VERSION ""

NS_ :

BS_:

BU_: DCM CCU C_ECU C_ECU_GW

BO_ 940 BIU3AC: 8 C_ECU_GW
 SG_ BIU3AC_7_0_HEADLAMP_SMALL : 56|1@1+ (1,0) [0|1] ""  CCU
 SG_ BIU3AC_7_1_HEADLAMP_LO_REQ : 57|1@1+ (1,0) [0|1] "" Vector__XXX
 SG_ BIU3AC_7_2_HEADLAMP_HI_REQ : 58|1@1+ (1,0) [0|1] ""  CCU
 SG_ BIU3AC_7_3_FT_FOG_RELAY_REQ : 59|1@1+ (1,0) [0|1] ""  CCU
 SG_ BIU3AC_7_4_FOGLAMP_RR : 60|1@1+ (1,0) [0|1] ""  CCU
 SG_ BIU3AC_7_5_DRL : 61|1@1+ (1,0) [0|1] "" Vector__XXX
 SG_ BIU3AC_7_6_WIPER_FRONT : 62|1@1+ (1,0) [0|1] ""  CCU
 SG_ BIU3AC_7_7_RDEF_RELAY_REQ : 63|1@1+ (1,0) [0|1] "" Vector__XXX
 SG_ BIU3AC_6_0_RDEFOGSW : 48|1@1+ (1,0) [0|1] "" Vector__XXX
 SG_ BIU3AC_6_1_CSTM_PRG : 49|1@1+ (1,0) [0|1] ""  CCU
 SG_ BIU3AC_6_2_FAIL_SHIFTLOCKSOL : 50|1@1+ (1,0) [0|1] "" Vector__XXX
 SG_ BIU3AC_6_3_REQ_CANCEL_ISS : 51|1@1+ (1,0) [0|1] "" Vector__XXX
 SG_ BIU3AC_6_4_REVERSE_MT : 52|1@1+ (1,0) [0|1] ""  CCU
 SG_ BIU3AC_6_5_HANDBRAKE : 53|1@1+ (1,0) [0|1] ""  CCU
 SG_ BIU3AC_6_6_BRAKELAMPSW : 54|1@1+ (1,0) [0|1] "" Vector__XXX
 SG_ BIU3AC_6_7_TOWING_SW : 55|1@1+ (1,0) [0|1] "" Vector__XXX
 SG_ BIU3AC_5_0_LANE_OFF_SW : 40|2@1+ (1,0) [0|3] "" Vector__XXX
 SG_ BIU3AC_5_2_PCR_OFF_SW : 42|2@1+ (1,0) [0|3] "" Vector__XXX
 SG_ BIU3AC_5_4_DIMMER_CANCEL : 44|1@1+ (1,0) [0|1] ""  CCU
 SG_ BIU3AC_5_5_KEYSW : 45|1@1+ (1,0) [0|1] "" Vector__XXX
 SG_ BIU3AC_5_6_IND_ND_SHIFTLOCK : 46|1@1+ (1,0) [0|1] "" Vector__XXX
 SG_ BIU3AC_4_0_DOOR_DRVR : 32|1@1+ (1,0) [0|1] ""  DCM,CCU
 SG_ BIU3AC_4_1_DOOR_PASS : 33|1@1+ (1,0) [0|1] ""  DCM,CCU
 SG_ BIU3AC_4_2_DOOR_RRRH : 34|1@1+ (1,0) [0|1] ""  DCM,CCU
 SG_ BIU3AC_4_3_DOOR_RRLH : 35|1@1+ (1,0) [0|1] ""  DCM,CCU
 SG_ BIU3AC_4_4_DOOR_RG : 36|1@1+ (1,0) [0|1] ""  DCM,CCU
 SG_ BIU3AC_4_5_DOOR_TR : 37|1@1+ (1,0) [0|1] ""  DCM,CCU
 SG_ BIU3AC_4_6_HOOD_CLOSE : 38|1@1+ (1,0) [0|1] ""  DCM,CCU
 SG_ BIU3AC_4_7_HOOD_OPEN : 39|1@1+ (1,0) [0|1] ""  CCU
 SG_ BIU3AC_3_0_GW_STSW_RES : 24|1@1+ (1,0) [0|1] "" Vector__XXX
 SG_ BIU3AC_3_1_GW_POWER_RES : 25|2@1+ (1,0) [0|2] "" Vector__XXX
 SG_ BIU3AC_3_3_ST1 : 27|1@1+ (1,0) [0|1] "" Vector__XXX
 SG_ BIU3AC_3_4_ST2 : 28|1@1+ (1,0) [0|1] "" Vector__XXX
 SG_ BIU3AC_3_5_ACC : 29|1@1+ (1,0) [0|1] ""  CCU
 SG_ BIU3AC_3_6_IGA : 30|1@1+ (1,0) [0|1] ""  CCU
 SG_ BIU3AC_3_7_BAT_BACKUP : 31|1@1+ (1,0) [0|1] "" Vector__XXX
 SG_ BIU3AC_2_0_CSTM_AC : 16|1@1+ (1,0) [0|1] "" Vector__XXX
 SG_ BIU3AC_2_1_IMB_SMT : 17|2@1+ (1,0) [0|3] ""  DCM,CCU
 SG_ BIU3AC_2_3_CSTM_WGN_SDN : 19|1@1+ (1,0) [0|1] ""  DCM
 SG_ BIU3AC_2_4_VAL_SEAT_BACK_CTSM : 20|1@1+ (1,0) [0|1] "" Vector__XXX
 SG_ BIU3AC_2_5_VAL_MIR_AFOLD_CTSM : 21|1@1+ (1,0) [0|1] "" Vector__XXX
 SG_ BIU3AC_2_6_VAL_MIR_RTILT_CTSM : 22|1@1+ (1,0) [0|1] "" Vector__XXX
 SG_ BIU3AC_2_7_WIPER_REAR : 23|1@1+ (1,0) [0|1] ""  CCU
 SG_ BIU3AC_1_0_MSG_COUNTER : 8|4@1+ (1,0) [0|15] ""  DCM,CCU
 SG_ BIU3AC_1_4_PADDLESHIFT_DOWN_SW : 12|1@1+ (1,0) [0|1] "" Vector__XXX
 SG_ BIU3AC_1_5_PADDLESHIFT_UP_SW : 13|1@1+ (1,0) [0|1] "" Vector__XXX
 SG_ BIU3AC_1_6_MANUALMODE_SW : 14|1@1+ (1,0) [0|1] "" Vector__XXX
 SG_ BIU3AC_0_0_CHECK_SUM : 0|8@1+ (1,0) [0|255] ""  DCM,CCU

BO_ 1616 BIU650: 8 C_ECU_GW
 SG_ BIU650_7_0_Reserved : 56|1@1+ (1,0) [0|1] ""  CCU
 SG_ BIU650_7_1_Reserved : 57|1@1+ (1,0) [0|1] ""  CCU
 SG_ BIU650_7_2_Reserved : 58|1@1+ (1,0) [0|1] ""  CCU
 SG_ BIU650_7_3_DOOR_LINK_SW_STS : 59|1@1+ (1,0) [0|1] ""  CCU
 SG_ BIU650_7_4_Reserved : 60|1@1+ (1,0) [0|1] ""  CCU
 SG_ BIU650_6_0_Reserved : 48|3@1+ (1,0) [0|7] ""  CCU
 SG_ BIU650_6_3_RR_WIPER_STATUS : 51|2@1+ (1,0) [0|3] ""  CCU
 SG_ BIU650_6_5_WIPER_SENSITIVITY_CTM : 53|2@1+ (1,0) [0|3] ""  CCU
 SG_ BIU650_5_0_Reserved : 40|1@1+ (1,0) [0|1] "" Vector__XXX
 SG_ BIU650_5_1_Reserved : 41|1@1+ (1,0) [0|1] "" Vector__XXX
 SG_ BIU650_5_2_FMH_DOOR_LOCK : 42|2@1+ (1,0) [0|3] "" Vector__XXX
 SG_ BIU650_5_4_LMH_DOOR_LOCK : 44|2@1+ (1,0) [0|3] "" Vector__XXX
 SG_ BIU650_4_0_REQ_OPE_AUTOLIGHT : 32|2@1+ (1,0) [0|3] "" Vector__XXX
 SG_ BIU650_4_2_STATE_SHINSSR : 34|2@1+ (1,0) [0|3] "" Vector__XXX
 SG_ BIU650_4_4_STATE_RLS_FAIL : 36|2@1+ (1,0) [0|3] "" Vector__XXX
 SG_ BIU650_3_0_REQ_FWASHER_ITLOCK : 24|1@1+ (1,0) [0|1] "" Vector__XXX
 SG_ BIU650_3_1_FWIPER_RTN : 25|1@1+ (1,0) [0|1] "" Vector__XXX
 SG_ BIU650_3_2_TURN_LAMP_STATE_LEFT : 26|1@1+ (1,0) [0|1] "" Vector__XXX
 SG_ BIU650_3_3_TURN_LAMP_STATE_RIGHT : 27|1@1+ (1,0) [0|1] "" Vector__XXX
 SG_ BIU650_3_4_Reserved : 28|1@1+ (1,0) [0|1] "" Vector__XXX
 SG_ BIU650_2_0_HEADLAMP_SMALL_SW : 16|1@1+ (1,0) [0|1] "" Vector__XXX
 SG_ BIU650_2_1_HEADLAMP_LO_SW : 17|1@1+ (1,0) [0|1] "" Vector__XXX
 SG_ BIU650_2_2_HEADLAMP_OFF_SW : 18|1@1+ (1,0) [0|1] "" Vector__XXX
 SG_ BIU650_2_3_HEADLAMP_Hi_SW : 19|1@1+ (1,0) [0|1] "" Vector__XXX
 SG_ BIU650_2_4_HEAD_LAMP_PASS_SW : 20|1@1+ (1,0) [0|1] "" Vector__XXX
 SG_ BIU650_2_5_FFOG_SW : 21|1@1+ (1,0) [0|1] "" Vector__XXX
 SG_ BIU650_2_6_RFOG_SW : 22|1@1+ (1,0) [0|1] "" Vector__XXX
 SG_ BIU650_1_0_MSG_COUNTER : 8|4@1+ (1,0) [0|15] "" Vector__XXX
 SG_ BIU650_0_0_CHECK_SUM : 0|8@1+ (1,0) [0|255] "" Vector__XXX

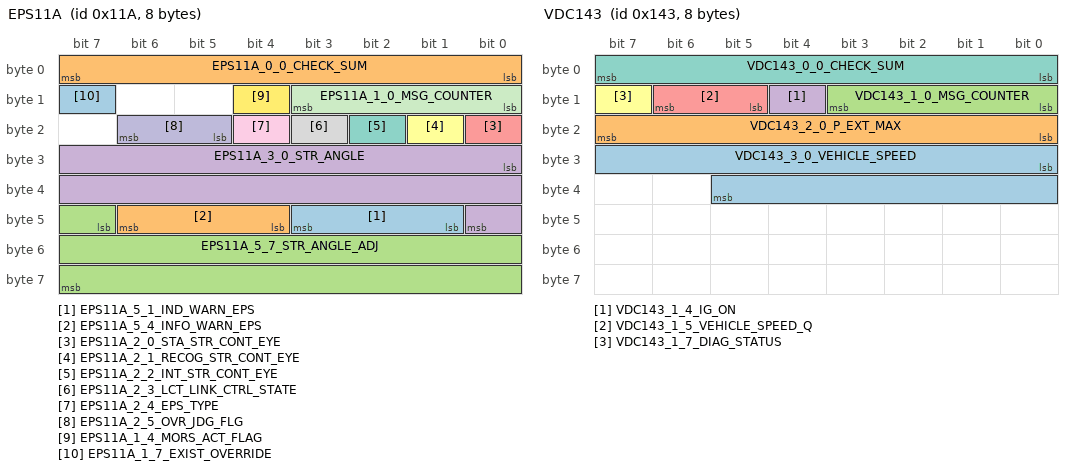
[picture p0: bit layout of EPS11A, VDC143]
BO_ 282 EPS11A: 8 C_ECU_GW
 SG_ EPS11A_5_1_IND_WARN_EPS : 41|3@1+ (1,0) [0|6] ""  DCM
 SG_ EPS11A_5_4_INFO_WARN_EPS : 44|3@1+ (1,0) [0|7] "" Vector__XXX
 SG_ EPS11A_5_7_STR_ANGLE_ADJ : 47|17@1- (0.01,0) [-655|655] "deg"  CCU
 SG_ EPS11A_3_0_STR_ANGLE : 24|17@1- (0.01,0) [-655|655] "deg" Vector__XXX
 SG_ EPS11A_2_0_STA_STR_CONT_EYE : 16|1@1+ (1,0) [0|1] "" Vector__XXX
 SG_ EPS11A_2_1_RECOG_STR_CONT_EYE : 17|1@1+ (1,0) [0|1] "" Vector__XXX
 SG_ EPS11A_2_2_INT_STR_CONT_EYE : 18|1@1+ (1,0) [0|1] "" Vector__XXX
 SG_ EPS11A_2_3_LCT_LINK_CTRL_STATE : 19|1@1+ (1,0) [0|1] "" Vector__XXX
 SG_ EPS11A_2_4_EPS_TYPE : 20|1@1+ (1,0) [0|1] "" Vector__XXX
 SG_ EPS11A_2_5_OVR_JDG_FLG : 21|2@1+ (1,0) [0|3] "" Vector__XXX
 SG_ EPS11A_1_0_MSG_COUNTER : 8|4@1+ (1,0) [0|15] ""  DCM
 SG_ EPS11A_1_4_MORS_ACT_FLAG : 12|1@1+ (1,0) [0|1] "" Vector__XXX
 SG_ EPS11A_1_7_EXIST_OVERRIDE : 15|1@1+ (1,0) [0|1] "" Vector__XXX
 SG_ EPS11A_0_0_CHECK_SUM : 0|8@1+ (1,0) [0|255] ""  DCM

BO_ 811 EPB32B: 8 C_ECU_GW
 SG_ EPB32B_7_0_AVH_TARGET_PRESS : 56|8@1+ (0.0235,0) [0|255] "MPa" Vector__XXX
 SG_ EPB32B_6_0_VEHICLE_RUN_STOP_FLG : 48|2@1+ (1,0) [0|3] "" Vector__XXX
 SG_ EPB32B_6_2_REQ_HILL_P_CAUTION : 50|1@1+ (1,0) [0|1] "" Vector__XXX
 SG_ EPB32B_5_0_FLG_AVH_OILPRES_EPB : 40|1@1+ (1,0) [0|1] "" Vector__XXX
 SG_ EPB32B_5_1_FLG_AVH : 41|1@1+ (1,0) [0|1] "" Vector__XXX
 SG_ EPB32B_5_2_AVH_INTENSIFY_PRES : 42|1@1+ (1,0) [0|1] "" Vector__XXX
 SG_ EPB32B_5_3_BREAK_IND : 43|2@1+ (1,0) [0|3] "" Vector__XXX
 SG_ EPB32B_5_5_AVH_ON_LAMP : 45|1@1+ (1,0) [0|1] ""  CCU
 SG_ EPB32B_5_6_AVH_FUNC_ON_LUMP : 46|1@1+ (1,0) [0|1] ""  CCU
 SG_ EPB32B_5_7_AVH_ACTIVE : 47|1@1+ (1,0) [0|1] ""  CCU
 SG_ EPB32B_4_0_BUZZER : 32|2@1+ (1,0) [0|3] "" Vector__XXX
 SG_ EPB32B_4_2_HILL_HOLD_ON_LAMP : 34|1@1+ (1,0) [0|1] "" Vector__XXX
 SG_ EPB32B_4_3_CLAMP_LAMP : 35|2@1+ (1,0) [0|3] ""  CCU
 SG_ EPB32B_4_5_WARN_LAMP : 37|2@1+ (1,0) [0|3] "" Vector__XXX
 SG_ EPB32B_4_7_WARN_EPB_MET_LCD : 39|1@1+ (1,0) [0|1] "" Vector__XXX
 SG_ EPB32B_3_0_STATUS_EPB : 24|3@1+ (1,0) [0|7] ""  CCU
 SG_ EPB32B_3_3_DYNAMIC_PARKING : 27|1@1+ (1,0) [0|1] "" Vector__XXX
 SG_ EPB32B_3_4_HILL_HOLD_RUN_FLG : 28|1@1+ (1,0) [0|1] "" Vector__XXX
 SG_ EPB32B_3_5_INHIBIT_ISS_DELAY : 29|1@1+ (1,0) [0|1] "" Vector__XXX
 SG_ EPB32B_3_6_INHIBIT_ISS : 30|1@1+ (1,0) [0|1] "" Vector__XXX
 SG_ EPB32B_3_7_AVH_PERMIT_CONT_ACC : 31|1@1+ (1,0) [0|1] "" Vector__XXX
 SG_ EPB32B_2_0_ERR_INFO : 16|2@1+ (1,0) [0|3] "" Vector__XXX
 SG_ EPB32B_2_2_EPB_FAIL_FLG1 : 18|1@1+ (1,0) [0|1] "" Vector__XXX
 SG_ EPB32B_2_3_EPB_FAIL_FLG2 : 19|1@1+ (1,0) [0|1] "" Vector__XXX
 SG_ EPB32B_2_4_EPB_FAIL_FLG3 : 20|1@1+ (1,0) [0|1] "" Vector__XXX
 SG_ EPB32B_1_0_MSG_COUNTER : 8|4@1+ (1,0) [0|15] ""  CCU
 SG_ EPB32B_1_4_WAKE_UP_FRAME : 12|1@1+ (1,0) [0|1] "" Vector__XXX
 SG_ EPB32B_1_5_REQ_COMM_CONT : 13|1@1+ (1,0) [0|1] "" Vector__XXX
 SG_ EPB32B_1_6 : 14|1@1+ (1,0) [0|1] "" Vector__XXX
 SG_ EPB32B_0_0_CHECK_SUM : 0|8@1+ (1,0) [0|255] ""  CCU

BO_ 323 VDC143: 8 C_ECU_GW
 SG_ VDC143_3_0_VEHICLE_SPEED : 24|14@1+ (0.05625,0) [0|299.98125] "km/h"  CCU
 SG_ VDC143_2_0_P_EXT_MAX : 16|8@1+ (1,0) [0|250] "bar" Vector__XXX
 SG_ VDC143_1_0_MSG_COUNTER : 8|4@1+ (1,0) [0|15] "" Vector__XXX
 SG_ VDC143_1_4_IG_ON : 12|1@1+ (1,0) [0|1] "" Vector__XXX
 SG_ VDC143_1_5_VEHICLE_SPEED_Q : 13|2@1+ (1,0) [0|3] "" Vector__XXX
 SG_ VDC143_1_7_DIAG_STATUS : 15|1@1+ (1,0) [0|1] "" Vector__XXX
 SG_ VDC143_0_0_CHECK_SUM : 0|8@1+ (1,0) [0|255] "" Vector__XXX

BO_ 808 VDC328: 8 C_ECU_GW
 SG_ VDC328_7_1_IND_WARN_CBC : 57|1@1+ (1,0) [0|1] "" Vector__XXX
 SG_ VDC328_7_2_ACTIVATE_CBC : 58|1@1+ (1,0) [0|1] "" Vector__XXX
 SG_ VDC328_7_3_FLAG_ACT_CBC : 59|1@1+ (1,0) [0|1] "" Vector__XXX
 SG_ VDC328_6_0_PROHIBIT_VDC_OFF_CCU : 48|1@1+ (1,0) [0|1] ""  CCU
 SG_ VDC328_6_1_PROHIBIT_AVH_CCU : 49|1@1+ (1,0) [0|1] "" Vector__XXX
 SG_ VDC328_5_0_VDC_BUZZER : 40|2@1+ (1,0) [0|3] "" Vector__XXX
 SG_ VDC328_5_2_WARN_BRAKE_BOOST : 42|1@1+ (1,0) [0|1] "" Vector__XXX
 SG_ VDC328_5_4_WARN_RBS : 44|2@1+ (1,0) [0|3] "" Vector__XXX
 SG_ VDC328_5_6_IND_HSA_ON : 46|1@1+ (1,0) [0|1] "" Vector__XXX
 SG_ VDC328_5_7_IND_TCS_OFF : 47|1@1+ (1,0) [0|1] "" Vector__XXX
 SG_ VDC328_4_0_IND_VDC_OFF : 32|1@1+ (1,0) [0|1] ""  CCU
 SG_ VDC328_4_1_STATE_ACTIVATE_VDC : 33|1@1+ (1,0) [0|1] ""  CCU
 SG_ VDC328_4_2_IND_HSA_OFF : 34|1@1+ (1,0) [0|1] ""  DCM
 SG_ VDC328_4_3_IND_HDC : 35|2@1+ (1,0) [0|3] ""  CCU
 SG_ VDC328_4_5_WARNING_BRAKE_SYS : 37|2@1+ (1,0) [0|3] "" Vector__XXX
 SG_ VDC328_4_7_ACTIVE_OHB : 39|1@1+ (1,0) [0|1] "" Vector__XXX
 SG_ VDC328_3_0_IND_WARN_EBD : 24|1@1+ (1,0) [0|1] ""  DCM
 SG_ VDC328_3_1_IND_WARN_ABS : 25|1@1+ (1,0) [0|1] ""  DCM
 SG_ VDC328_3_2_IND_WARN_VDC : 26|1@1+ (1,0) [0|1] ""  DCM,CCU
 SG_ VDC328_3_3_IND_WARN_HSA : 27|1@1+ (1,0) [0|1] ""  DCM
 SG_ VDC328_3_4_WARN_BRAKEFLUID_LV : 28|2@1+ (1,0) [0|3] "" Vector__XXX
 SG_ VDC328_3_6_IND_TCS_OFF : 30|1@1+ (1,0) [0|1] "" Vector__XXX
 SG_ VDC328_3_7_EXIST_EPB : 31|1@1+ (1,0) [0|1] ""  CCU
 SG_ VDC328_2_0_WARN_EBD_MET_LCD : 16|1@1+ (1,0) [0|1] "" Vector__XXX
 SG_ VDC328_2_1_WARN_ABS_MET_LCD : 17|1@1+ (1,0) [0|1] "" Vector__XXX
 SG_ VDC328_2_2_WARN_VDC_MET_LCD : 18|1@1+ (1,0) [0|1] "" Vector__XXX
 SG_ VDC328_2_3_WARN_HSA_MET_LCD : 19|1@1+ (1,0) [0|1] "" Vector__XXX
 SG_ VDC328_2_4_EXIST_VECTARING : 20|1@1+ (1,0) [0|1] "" Vector__XXX
 SG_ VDC328_1_0_MSG_COUNTER : 8|4@1+ (1,0) [0|15] ""  DCM,CCU
 SG_ VDC328_0_0_CHECK_SUM : 0|8@1+ (1,0) [0|255] ""  DCM,CCU

BO_ 316 VDC13C: 8 C_ECU_GW
 SG_ VDC13C_7_0_RCV_FAIL_ADA : 56|1@1+ (1,0) [0|1] "" Vector__XXX
 SG_ VDC13C_7_1_FAIL_PCU : 57|1@1+ (1,0) [0|1] "" Vector__XXX
 SG_ VDC13C_7_2_CONT_STATE_ES_BRAKE : 58|1@1+ (1,0) [0|1] "" Vector__XXX
 SG_ VDC13C_7_3_ASST_PRECRUSH_ACC : 59|1@1+ (1,0) [0|1] "" Vector__XXX
 SG_ VDC13C_7_4_CONT_STATE_PRECRUSH : 60|1@1+ (1,0) [0|1] "" Vector__XXX
 SG_ VDC13C_7_5_PERMIT_BRAKE_ACC : 61|1@1+ (1,0) [0|1] "" Vector__XXX
 SG_ VDC13C_7_6_DETECT_BRAKING : 62|1@1+ (1,0) [0|1] "" Vector__XXX
 SG_ VDC13C_7_7_EMERGENCY_BRAKE : 63|1@1+ (1,0) [0|1] "" Vector__XXX
 SG_ VDC13C_6_0_SPD_PULSE_INTEGRAL : 48|6@1+ (1,0) [0|63] ""  CCU
 SG_ VDC13C_6_6_VDC_OFF : 54|1@1+ (1,0) [0|1] ""  CCU
 SG_ VDC13C_6_7_STBY_PREVIEW_VDC : 55|1@1+ (1,0) [0|1] "" Vector__XXX
 SG_ VDC13C_5_0_SPD_PULSE_RRRH : 40|7@1+ (1,0) [0|95] "" Vector__XXX
 SG_ VDC13C_5_7_ACTIVATE_TSM : 47|1@1+ (1,0) [0|1] "" Vector__XXX
 SG_ VDC13C_4_0_SPD_PULSE_RRLH : 32|7@1+ (1,0) [0|95] "" Vector__XXX
 SG_ VDC13C_4_7_ACTIVATE_RMI : 39|1@1+ (1,0) [0|1] "" Vector__XXX
 SG_ VDC13C_3_0_SPD_PULSE_FTRH : 24|7@1+ (1,0) [0|95] "" Vector__XXX
 SG_ VDC13C_3_7_ACTIVATE_VECTARING : 31|1@1+ (1,0) [0|1] ""  CCU
 SG_ VDC13C_2_0_SPD_PULSE_FTLH : 16|7@1+ (1,0) [0|95] "" Vector__XXX
 SG_ VDC13C_2_7_STATE_ACTIVATE_HSA : 23|1@1+ (1,0) [0|1] "" Vector__XXX
 SG_ VDC13C_1_0_MSG_COUNTER : 8|4@1+ (1,0) [0|15] ""  CCU
 SG_ VDC13C_1_4_ACTIVE_BRAKEHOLD : 12|1@1+ (1,0) [0|1] "" Vector__XXX
 SG_ VDC13C_1_5_PROHIBIT_BRAKEHOLD : 13|1@1+ (1,0) [0|1] "" Vector__XXX
 SG_ VDC13C_1_6_BRAKELAMP_RELAY : 14|1@1+ (1,0) [0|1] "" Vector__XXX
 SG_ VDC13C_1_7_STATUS_BRAKELAMP : 15|1@1+ (1,0) [0|1] "" Vector__XXX
 SG_ VDC13C_0_0_CHECK_SUM : 0|8@1+ (1,0) [0|255] ""  CCU

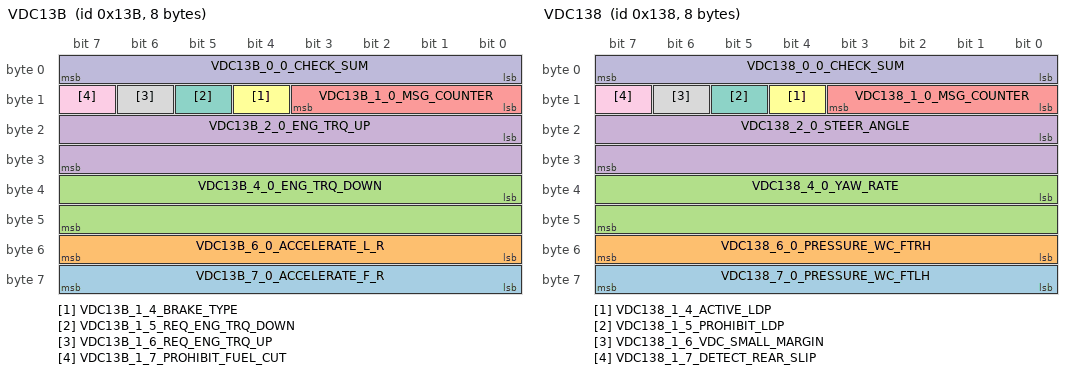
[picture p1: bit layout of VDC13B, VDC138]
BO_ 315 VDC13B: 8 C_ECU_GW
 SG_ VDC13B_7_0_ACCELERATE_F_R : 56|8@1- (0.1,0) [-12.5|12.5] "m/s^2"  CCU
 SG_ VDC13B_6_0_ACCELERATE_L_R : 48|8@1- (0.1923,0) [-17.64|17.64] "m/s^2"  CCU
 SG_ VDC13B_4_0_ENG_TRQ_DOWN : 32|16@1+ (0.1,-1000) [-1000|5553.5] "Nm" Vector__XXX
 SG_ VDC13B_2_0_ENG_TRQ_UP : 16|16@1+ (0.1,-1000) [-1000|5553.5] "Nm" Vector__XXX
 SG_ VDC13B_1_0_MSG_COUNTER : 8|4@1+ (1,0) [0|15] ""  CCU
 SG_ VDC13B_1_4_BRAKE_TYPE : 12|1@1+ (1,0) [0|1] "" Vector__XXX
 SG_ VDC13B_1_5_REQ_ENG_TRQ_DOWN : 13|1@1+ (1,0) [0|1] "" Vector__XXX
 SG_ VDC13B_1_6_REQ_ENG_TRQ_UP : 14|1@1+ (1,0) [0|1] "" Vector__XXX
 SG_ VDC13B_1_7_PROHIBIT_FUEL_CUT : 15|1@1+ (1,0) [0|1] "" Vector__XXX
 SG_ VDC13B_0_0_CHECK_SUM : 0|8@1+ (1,0) [0|255] ""  CCU

BO_ 313 VDC139: 8 C_ECU_GW
 SG_ VDC139_7_4_FAIL_PRESSURE_SSR : 60|1@1+ (1,0) [0|1] "" Vector__XXX
 SG_ VDC139_7_5_STATUS_EPB : 61|3@1+ (1,0) [0|7] "" Vector__XXX
 SG_ VDC139_6_0_SSR_N_PRESS : 48|12@1+ (1,0) [193|3896] "" Vector__XXX
 SG_ VDC139_5_0_PRESSURE_BRAKE : 40|8@1+ (0.13058823529412,0) [0|25] "MPa" Vector__XXX
 SG_ VDC139_4_0_HDC_STATUS : 32|2@1+ (1,0) [0|3] "" Vector__XXX
 SG_ VDC139_4_2_BRAKELAMPSW : 34|1@1+ (1,0) [0|1] ""  CCU
 SG_ VDC139_4_3_FAIL_BRAKELAMPSW : 35|1@1+ (1,0) [0|1] "" Vector__XXX
 SG_ VDC139_4_4_ACTIVATE_ABS : 36|1@1+ (1,0) [0|1] ""  CCU
 SG_ VDC139_4_5_ACTIVATE_TCS : 37|1@1+ (1,0) [0|1] ""  CCU
 SG_ VDC139_4_6_CONT_OVER_STR : 38|1@1+ (1,0) [0|1] ""  CCU
 SG_ VDC139_4_7_CONT_UNDER_STR : 39|1@1+ (1,0) [0|1] ""  CCU
 SG_ VDC139_3_5_FAIL_VDC_SSR : 29|1@1+ (1,0) [0|1] ""  CCU
 SG_ VDC139_3_6_FAIL_SPD_SSR_FHI : 30|1@1+ (1,0) [0|1] "" Vector__XXX
 SG_ VDC139_3_7_FAIL_ABS_SYS : 31|1@1+ (1,0) [0|1] "" Vector__XXX
 SG_ VDC139_2_0_SPD_WHEEL_AVE : 16|13@1+ (0.05625,0) [0|299.98125] "km/h"  DCM,CCU
 SG_ VDC139_1_0_MSG_COUNTER : 8|4@1+ (1,0) [0|15] ""  DCM,CCU
 SG_ VDC139_1_4_FAIL_HDC_SYS : 12|1@1+ (1,0) [0|1] "" Vector__XXX
 SG_ VDC139_1_5_VEHICLE_HIGHT : 13|2@1+ (1,0) [0|2] ""  CCU
 SG_ VDC139_1_7_REPROGRAMING : 15|1@1+ (1,0) [0|1] ""  CCU
 SG_ VDC139_0_0_CHECK_SUM : 0|8@1+ (1,0) [0|255] ""  DCM,CCU

BO_ 312 VDC138: 8 C_ECU_GW
 SG_ VDC138_7_0_PRESSURE_WC_FTLH : 56|8@1+ (0.08,0) [0|20.4] "MPa" Vector__XXX
 SG_ VDC138_6_0_PRESSURE_WC_FTRH : 48|8@1+ (0.08,0) [0|20.4] "MPa" Vector__XXX
 SG_ VDC138_4_0_YAW_RATE : 32|16@1- (0.0047358121330724,0) [-1.571|1.571] "rad/s"  CCU
 SG_ VDC138_2_0_STEER_ANGLE : 16|16@1- (0.1,0) [-719.9|719.9] "deg"  CCU
 SG_ VDC138_1_0_MSG_COUNTER : 8|4@1+ (1,0) [0|15] ""  CCU
 SG_ VDC138_1_4_ACTIVE_LDP : 12|1@1+ (1,0) [0|1] "" Vector__XXX
 SG_ VDC138_1_5_PROHIBIT_LDP : 13|1@1+ (1,0) [0|1] "" Vector__XXX
 SG_ VDC138_1_6_VDC_SMALL_MARGIN : 14|1@1+ (1,0) [0|1] "" Vector__XXX
 SG_ VDC138_1_7_DETECT_REAR_SLIP : 15|1@1+ (1,0) [0|1] "" Vector__XXX
 SG_ VDC138_0_0_CHECK_SUM : 0|8@1+ (1,0) [0|255] ""  CCU

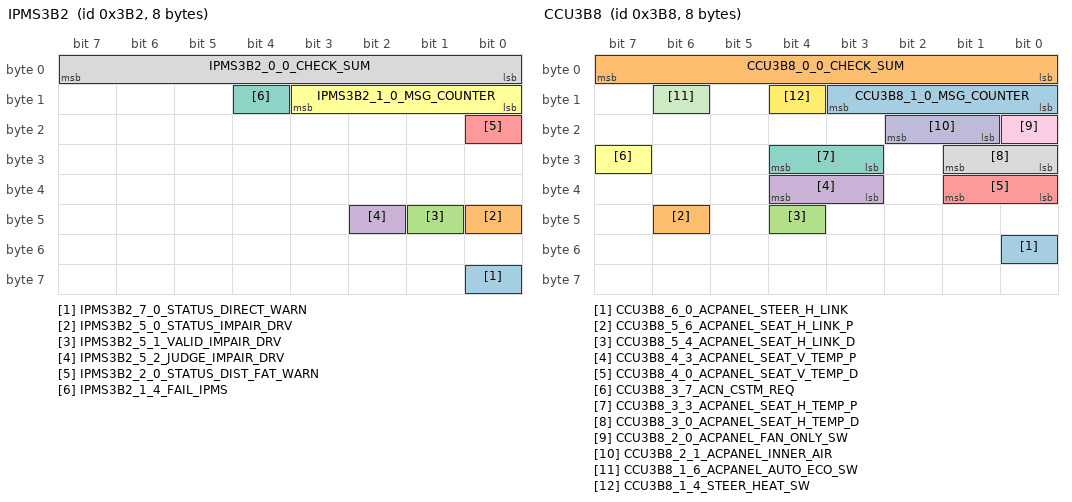
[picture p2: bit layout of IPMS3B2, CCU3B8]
BO_ 946 IPMS3B2: 8 C_ECU_GW
 SG_ IPMS3B2_7_0_STATUS_DIRECT_WARN : 56|1@1+ (1,0) [0|0] ""  CCU
 SG_ IPMS3B2_5_0_STATUS_IMPAIR_DRV : 40|1@1+ (1,0) [0|1] ""  CCU
 SG_ IPMS3B2_5_1_VALID_IMPAIR_DRV : 41|1@1+ (1,0) [0|1] ""  CCU
 SG_ IPMS3B2_5_2_JUDGE_IMPAIR_DRV : 42|1@1+ (1,0) [0|1] ""  CCU
 SG_ IPMS3B2_2_0_STATUS_DIST_FAT_WARN : 16|1@1+ (1,0) [0|1] ""  CCU
 SG_ IPMS3B2_1_0_MSG_COUNTER : 8|4@1+ (1,0) [0|15] ""  CCU
 SG_ IPMS3B2_1_4_FAIL_IPMS : 12|1@1+ (1,0) [0|1] "" Vector__XXX
 SG_ IPMS3B2_0_0_CHECK_SUM : 0|8@1+ (1,0) [0|255] ""  CCU

BO_ 952 CCU3B8: 8 CCU
 SG_ CCU3B8_6_0_ACPANEL_STEER_H_LINK : 48|1@1+ (1,0) [0|3] ""  C_ECU_GW
 SG_ CCU3B8_5_6_ACPANEL_SEAT_H_LINK_P : 46|1@1+ (1,0) [0|3] ""  C_ECU_GW
 SG_ CCU3B8_5_4_ACPANEL_SEAT_H_LINK_D : 44|1@1+ (1,0) [0|3] ""  C_ECU_GW
 SG_ CCU3B8_4_3_ACPANEL_SEAT_V_TEMP_P : 35|2@1+ (1,0) [0|3] ""  C_ECU_GW
 SG_ CCU3B8_4_0_ACPANEL_SEAT_V_TEMP_D : 32|2@1+ (1,0) [0|3] ""  C_ECU_GW
 SG_ CCU3B8_3_7_ACN_CSTM_REQ : 31|1@1+ (1,0) [0|1] ""  C_ECU_GW
 SG_ CCU3B8_3_3_ACPANEL_SEAT_H_TEMP_P : 27|2@1+ (1,0) [0|3] ""  C_ECU_GW
 SG_ CCU3B8_3_0_ACPANEL_SEAT_H_TEMP_D : 24|2@1+ (1,0) [0|3] ""  C_ECU_GW
 SG_ CCU3B8_2_0_ACPANEL_FAN_ONLY_SW : 16|1@1+ (1,0) [0|3] ""  C_ECU_GW
 SG_ CCU3B8_2_1_ACPANEL_INNER_AIR : 17|2@1+ (1,0) [0|3] ""  C_ECU_GW
 SG_ CCU3B8_1_6_ACPANEL_AUTO_ECO_SW : 14|1@1+ (1,0) [0|3] ""  C_ECU,C_ECU_GW
 SG_ CCU3B8_1_4_STEER_HEAT_SW : 12|1@1+ (1,0) [0|3] ""  C_ECU_GW
 SG_ CCU3B8_1_0_MSG_COUNTER : 8|4@1+ (1,0) [0|15] ""  C_ECU_GW
 SG_ CCU3B8_0_0_CHECK_SUM : 0|8@1+ (1,0) [0|255] ""  C_ECU_GW

BO_ 1712 CCU6B0: 8 CCU
 SG_ CCU6B0_7_0_AIL_CSTM_PRS_REQ : 56|1@1+ (1,0) [0|1] ""  C_ECU_GW
 SG_ CCU6B0_7_1_AIL_RENDER_REQ : 57|3@1+ (1,0) [0|5] ""  C_ECU_GW
 SG_ CCU6B0_6_0_AIL_FIRST_BRIGHT_REQ : 48|4@1+ (1,0) [0|9] ""  C_ECU_GW
 SG_ CCU6B0_6_4_AIL_SECOND_BRIGHT_REQ : 52|4@1+ (1,0) [0|15] ""  C_ECU_GW
 SG_ CCU6B0_5_0_AIL_SECOND_COLOR_REQ : 40|6@1+ (1,0) [0|63] ""  C_ECU_GW
 SG_ CCU6B0_4_0_AIL_FIRST_COLOR_REQ : 32|6@1+ (1,0) [0|63] ""  C_ECU_GW
 SG_ CCU6B0_3_0_AIL_ADAS_VEH_DIS_REQ : 24|1@1+ (1,0) [0|1] ""  C_ECU_GW
 SG_ CCU6B0_3_1_AIL_ADAS_LANE_DEV_REQ : 25|1@1+ (1,0) [0|1] ""  C_ECU_GW
 SG_ CCU6B0_3_2_AIL_ADAS_FT_CROSS_REQ : 26|1@1+ (1,0) [0|1] ""  C_ECU_GW
 SG_ CCU6B0_3_3_AIL_ADAS_HANDS_FR_REQ : 27|1@1+ (1,0) [0|1] ""  C_ECU_GW
 SG_ CCU6B0_2_0_AIL_WEL_FOL_REQ : 16|1@1+ (1,0) [0|1] ""  C_ECU_GW
 SG_ CCU6B0_2_1_AIL_ADAS_EXP_REQ : 17|1@1+ (1,0) [0|1] ""  C_ECU_GW
 SG_ CCU6B0_2_2_AIL_NOTIFI_EXP_REQ : 18|1@1+ (1,0) [0|1] ""  C_ECU_GW
 SG_ CCU6B0_2_3_AIL_AIR_CON_EXP_REQ : 19|1@1+ (1,0) [0|1] ""  C_ECU_GW
 SG_ CCU6B0_1_0_MSG_COUNTER : 8|4@1+ (1,0) [0|15] ""  C_ECU_GW
 SG_ CCU6B0_1_4_AIL_CUSTOM_REQ : 12|1@1+ (1,0) [0|1] ""  C_ECU_GW
 SG_ CCU6B0_1_5_AIL_CUSTOM_RESET_REQ : 13|1@1+ (1,0) [0|1] ""  C_ECU_GW
 SG_ CCU6B0_1_6_AIL_ON_OFF_REQ : 14|1@1+ (1,0) [0|1] ""  C_ECU_GW
 SG_ CCU6B0_0_0_CHECK_SUM : 0|8@1+ (1,0) [0|255] ""  C_ECU_GW

BO_ 1711 CCU6AF: 8 CCU
 SG_ CCU6AF_1_0_MSG_COUNTER : 8|4@1+ (1,0) [0|15] ""  C_ECU_GW
 SG_ CCU6AF_0_0_CHECK_SUM : 0|8@1+ (1,0) [0|255] ""  C_ECU_GW

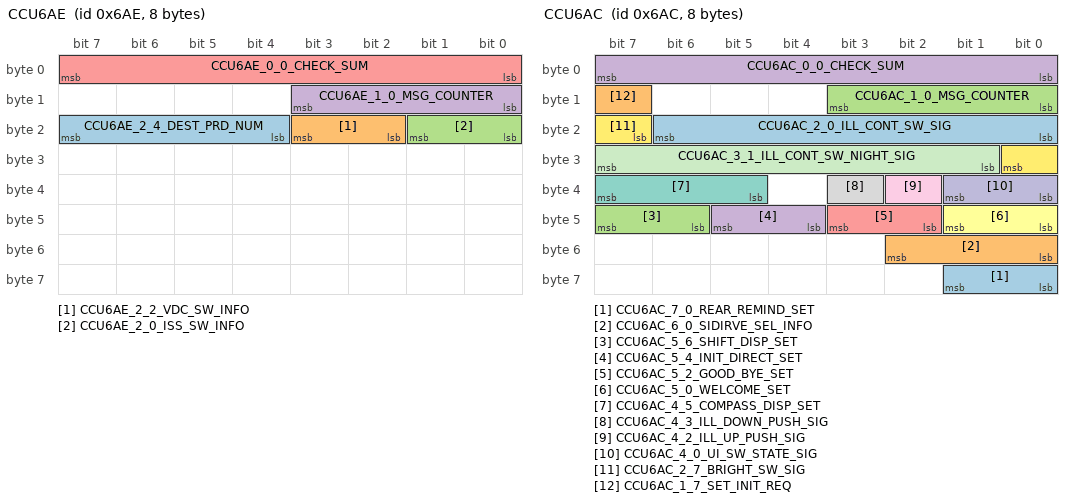
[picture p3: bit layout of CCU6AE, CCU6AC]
BO_ 1710 CCU6AE: 8 CCU
 SG_ CCU6AE_2_4_DEST_PRD_NUM : 20|4@1+ (1,0) [0|21] ""  C_ECU_GW
 SG_ CCU6AE_2_2_VDC_SW_INFO : 18|2@1+ (1,0) [0|2] ""  C_ECU_GW
 SG_ CCU6AE_2_0_ISS_SW_INFO : 16|2@1+ (1,0) [0|1] ""  C_ECU_GW
 SG_ CCU6AE_1_0_MSG_COUNTER : 8|4@1+ (1,0) [0|15] ""  C_ECU_GW
 SG_ CCU6AE_0_0_CHECK_SUM : 0|8@1+ (1,0) [0|255] ""  C_ECU_GW

BO_ 1709 CCU6AD: 8 CCU
 SG_ CCU6AD_7_0_DMS_SET_REQ : 56|1@1+ (1,0) [0|1] ""  C_ECU_GW
 SG_ CCU6AD_7_1_DP_POPUP_RES : 57|2@1+ (1,0) [0|3] ""  C_ECU,C_ECU_GW
 SG_ CCU6AD_6_3_EYE_MONI_BLUE_IND_SET : 51|1@1+ (1,0) [0|1] ""  C_ECU_GW
 SG_ CCU6AD_6_2_EYE_MONI_GRE_IND_SET : 50|1@1+ (1,0) [0|1] ""  C_ECU_GW
 SG_ CCU6AD_6_1_EYE_MONI_YEL_IND_SET : 49|1@1+ (1,0) [0|1] ""  C_ECU_GW
 SG_ CCU6AD_6_0_EYE_MONI_RED_IND_SET : 48|1@1+ (1,0) [0|1] ""  C_ECU_GW
 SG_ CCU6AD_5_0_DP_OPERATION_FLAG : 40|4@1+ (1,0) [0|15] ""  C_ECU_GW
 SG_ CCU6AD_5_4_DP_OPERATION_NO : 44|4@1+ (1,0) [0|15] ""  C_ECU_GW
 SG_ CCU6AD_4_7_DP_CCU_FAIL : 39|1@1+ (1,0) [0|1] ""  C_ECU,C_ECU_GW
 SG_ CCU6AD_4_3_ALERT_BUZZ_REQ : 35|3@1+ (1,0) [0|3] ""  C_ECU_GW
 SG_ CCU6AD_4_0_ALERT_VOL_LEVEL_SET : 32|3@1+ (1,0) [0|3] ""  C_ECU_GW
 SG_ CCU6AD_3_2_PREC_CAR_START_VOL : 26|3@1+ (1,0) [0|3] ""  C_ECU_GW
 SG_ CCU6AD_3_0_PREC_CAR_SIG_VOL_SET : 24|2@1+ (1,0) [0|2] ""  C_ECU_GW
 SG_ CCU6AD_2_3_MET_TEMP_UNIT_SET : 19|2@1+ (1,0) [0|2] ""  C_ECU_GW
 SG_ CCU6AD_2_0_UNIT_SET : 16|3@1+ (1,0) [0|6] ""  C_ECU_GW
 SG_ CCU6AD_1_0_MSG_COUNTER : 8|4@1+ (1,0) [0|15] ""  C_ECU_GW
 SG_ CCU6AD_1_4_DP_DKY_OPERATION_NO : 12|4@1+ (1,0) [0|15] ""  C_ECU,C_ECU_GW
 SG_ CCU6AD_0_0_CHECK_SUM : 0|8@1+ (1,0) [0|255] ""  C_ECU_GW

BO_ 1708 CCU6AC: 8 CCU
 SG_ CCU6AC_7_0_REAR_REMIND_SET : 56|2@1+ (1,0) [0|3] ""  C_ECU_GW
 SG_ CCU6AC_6_0_SIDIRVE_SEL_INFO : 48|3@1+ (1,0) [0|6] ""  C_ECU_GW
 SG_ CCU6AC_5_6_SHIFT_DISP_SET : 46|2@1+ (1,0) [0|2] ""  C_ECU_GW
 SG_ CCU6AC_5_4_INIT_DIRECT_SET : 44|2@1+ (1,0) [0|2] ""  C_ECU_GW
 SG_ CCU6AC_5_2_GOOD_BYE_SET : 42|2@1+ (1,0) [0|2] ""  C_ECU_GW
 SG_ CCU6AC_5_0_WELCOME_SET : 40|2@1+ (1,0) [0|2] ""  C_ECU_GW
 SG_ CCU6AC_4_5_COMPASS_DISP_SET : 37|3@1+ (1,0) [0|5] ""  C_ECU_GW
 SG_ CCU6AC_4_3_ILL_DOWN_PUSH_SIG : 35|1@1+ (1,0) [0|1] ""  C_ECU_GW
 SG_ CCU6AC_4_2_ILL_UP_PUSH_SIG : 34|1@1+ (1,0) [0|1] ""  C_ECU_GW
 SG_ CCU6AC_4_0_UI_SW_STATE_SIG : 32|2@1+ (1,0) [0|3] ""  C_ECU_GW
 SG_ CCU6AC_3_1_ILL_CONT_SW_NIGHT_SIG : 25|7@1+ (1,0) [0|100] ""  C_ECU_GW
 SG_ CCU6AC_2_7_BRIGHT_SW_SIG : 23|2@1+ (1,0) [0|2] ""  C_ECU_GW
 SG_ CCU6AC_2_0_ILL_CONT_SW_SIG : 16|7@1+ (1,0) [0|100] ""  C_ECU_GW
 SG_ CCU6AC_1_7_SET_INIT_REQ : 15|1@1+ (1,0) [0|1] ""  C_ECU_GW
 SG_ CCU6AC_1_0_MSG_COUNTER : 8|4@1+ (1,0) [0|15] ""  C_ECU_GW
 SG_ CCU6AC_0_0_CHECK_SUM : 0|8@1+ (1,0) [0|255] ""  C_ECU_GW

BO_ 1707 CCU6AB: 8 CCU
 SG_ CCU6AB_7_3_REQ_RESET_CSTM_TPM : 59|1@1+ (1,0) [0|1] ""  C_ECU_GW
 SG_ CCU6AB_7_2_TPM_CSTM_CHG_REQ : 58|1@1+ (1,0) [0|1] ""  C_ECU_GW
 SG_ CCU6AB_7_0_CSTM_TIRE_UNIT : 56|2@1+ (1,0) [0|1] ""  C_ECU_GW
 SG_ CCU6AB_6_3_REQ_RESET_CSTM_AHL : 51|1@1+ (1,0) [0|1] ""  C_ECU_GW
 SG_ CCU6AB_6_2_SRH_CSTM_CHG_REQ : 50|1@1+ (1,0) [0|1] ""  C_ECU_GW
 SG_ CCU6AB_6_0_SRH_CSTM_CHG_SET : 48|2@1+ (1,0) [0|1] ""  C_ECU_GW
 SG_ CCU6AB_5_0_SEATAWAY_DST_CSTM : 40|2@1+ (1,0) [0|3] ""  C_ECU,C_ECU_GW
 SG_ CCU6AB_5_2_DRIVER_POSI_REQ : 42|4@1+ (1,0) [0|2] ""  C_ECU,C_ECU_GW
 SG_ CCU6AB_5_6_OCCUPANT_DETECT_REQ : 46|2@1+ (1,0) [0|3] ""  C_ECU,C_ECU_GW
 SG_ CCU6AB_4_6_AFOLD_SW_MIR_SW : 38|2@1+ (1,0) [0|1] ""  C_ECU,C_ECU_GW
 SG_ CCU6AB_4_2_MIR_DIRECTION_MIR_SW : 34|4@1+ (1,0) [0|4] ""  C_ECU,C_ECU_GW
 SG_ CCU6AB_4_0_MIR_SELECT_LR_MIR_SW : 32|2@1+ (1,0) [0|2] ""  C_ECU,C_ECU_GW
 SG_ CCU6AB_3_0_PRG_OPENER_SW : 24|1@1+ (1,0) [0|1] ""  C_ECU,C_ECU_GW
 SG_ CCU6AB_3_1_PRG_MEM_CHG_REQ : 25|1@1+ (1,0) [0|1] ""  C_ECU,C_ECU_GW
 SG_ CCU6AB_3_2_PRG_HF_CHG_REQ : 26|1@1+ (1,0) [0|1] ""  C_ECU,C_ECU_GW
 SG_ CCU6AB_3_6_MIR_RTILT_R_CSTM : 30|1@1+ (1,0) [0|1] ""  C_ECU,C_ECU_GW
 SG_ CCU6AB_3_7_MIR_RTILT_L_CSTM : 31|1@1+ (1,0) [0|1] ""  C_ECU,C_ECU_GW
 SG_ CCU6AB_2_6_WASH_CAR_MODE_REQ : 22|2@1+ (1,0) [0|1] ""  C_ECU,C_ECU_GW
 SG_ CCU6AB_2_4_SHUT_DOWN_MODE_REQ : 20|2@1+ (1,0) [0|1] ""  C_ECU,C_ECU_GW
 SG_ CCU6AB_2_2_PET_MODE_SWITCH_REQ : 18|2@1+ (1,0) [0|1] ""  C_ECU,C_ECU_GW
 SG_ CCU6AB_2_0_POW_ON_FIX_MODE_REQ : 16|2@1+ (1,0) [0|1] ""  C_ECU,C_ECU_GW
 SG_ CCU6AB_1_7_CECU_CSTM_RESET_REQ : 15|1@1+ (1,0) [0|1] ""  C_ECU,C_ECU_GW
 SG_ CCU6AB_1_0_MSG_COUNTER : 8|4@1+ (1,0) [0|15] ""  C_ECU,C_ECU_GW
 SG_ CCU6AB_0_0_CHECK_SUM : 0|8@1+ (1,0) [0|255] ""  C_ECU,C_ECU_GW

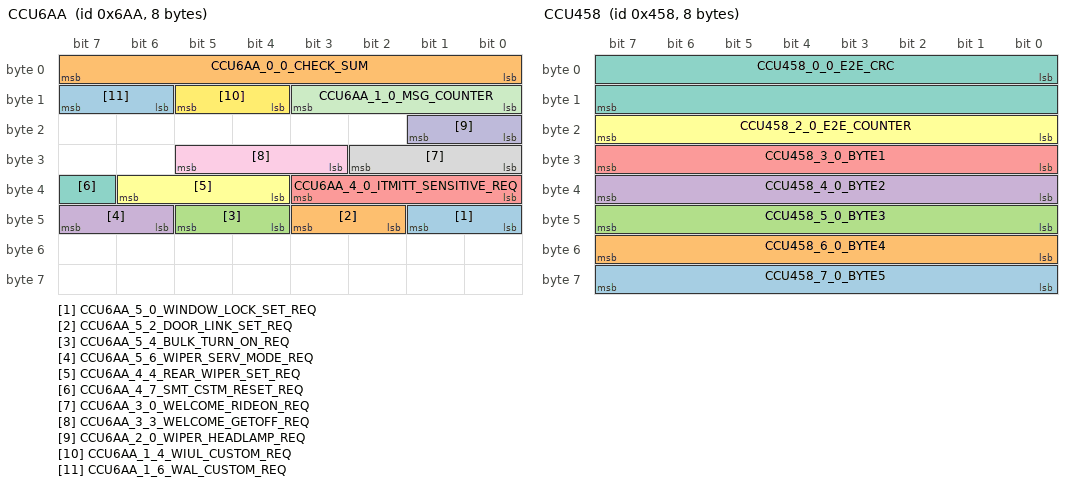
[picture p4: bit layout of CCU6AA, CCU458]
BO_ 1706 CCU6AA: 8 CCU
 SG_ CCU6AA_5_0_WINDOW_LOCK_SET_REQ : 40|2@1+ (1,0) [0|1] ""  C_ECU_GW
 SG_ CCU6AA_5_2_DOOR_LINK_SET_REQ : 42|2@1+ (1,0) [0|1] ""  C_ECU_GW
 SG_ CCU6AA_5_4_BULK_TURN_ON_REQ : 44|2@1+ (1,0) [0|1] ""  C_ECU_GW
 SG_ CCU6AA_5_6_WIPER_SERV_MODE_REQ : 46|2@1+ (1,0) [0|3] ""  C_ECU_GW
 SG_ CCU6AA_4_0_ITMITT_SENSITIVE_REQ : 32|4@1+ (1,0) [0|21] ""  C_ECU_GW
 SG_ CCU6AA_4_4_REAR_WIPER_SET_REQ : 36|3@1+ (1,0) [0|3] ""  C_ECU_GW
 SG_ CCU6AA_4_7_SMT_CSTM_RESET_REQ : 39|1@1+ (1,0) [0|1] ""  C_ECU_GW
 SG_ CCU6AA_3_0_WELCOME_RIDEON_REQ : 24|3@1+ (1,0) [0|7] ""  C_ECU,C_ECU_GW
 SG_ CCU6AA_3_3_WELCOME_GETOFF_REQ : 27|3@1+ (1,0) [0|7] ""  C_ECU,C_ECU_GW
 SG_ CCU6AA_2_0_WIPER_HEADLAMP_REQ : 16|2@1+ (1,0) [0|3] ""  C_ECU,C_ECU_GW
 SG_ CCU6AA_1_0_MSG_COUNTER : 8|4@1+ (1,0) [0|15] ""  C_ECU,C_ECU_GW
 SG_ CCU6AA_1_4_WIUL_CUSTOM_REQ : 12|2@1+ (1,0) [0|2] ""  C_ECU_GW
 SG_ CCU6AA_1_6_WAL_CUSTOM_REQ : 14|2@1+ (1,0) [0|2] ""  C_ECU_GW
 SG_ CCU6AA_0_0_CHECK_SUM : 0|8@1+ (1,0) [0|255] ""  C_ECU,C_ECU_GW

BO_ 1704 CCU6A8: 8 CCU
 SG_ CCU6A8_7_5_TRQ_CHG_MODE_SET : 61|2@1+ (1,0) [0|3] ""  C_ECU_GW
 SG_ CCU6A8_7_3_ADAPT_DEC_CHG_REQ : 59|2@1+ (1,0) [0|3] ""  C_ECU_GW
 SG_ CCU6A8_7_0_DEC_SELECT_REQ_B : 56|3@1+ (1,0) [0|3] ""  C_ECU_GW
 SG_ CCU6A8_6_5_DEC_SELECT_REQ_D : 53|3@1+ (1,0) [0|3] ""  C_ECU_GW
 SG_ CCU6A8_6_2_DEC_SELECT_REQ_ALL : 50|3@1+ (1,0) [0|3] ""  C_ECU_GW
 SG_ CCU6A8_6_0_DEC_SELECT_REQ_IND : 48|2@1+ (1,0) [0|3] ""  C_ECU_GW
 SG_ CCU6A8_5_2_TOWING_MODE_REQ : 42|2@1+ (1,0) [0|2] ""  C_ECU_GW
 SG_ CCU6A8_5_0_FACTORY_MODE_STATE : 40|2@1+ (1,0) [0|3] ""  C_ECU_GW
 SG_ CCU6A8_4_2_TRIP_RESET_REQ : 34|2@1+ (1,0) [0|1] ""  C_ECU_GW
 SG_ CCU6A8_4_0_TRIP_SWITCH_REQ : 32|2@1+ (1,0) [0|3] ""  C_ECU_GW
 SG_ CCU6A8_3_0_DOW_SFT_POS_SET : 24|2@1+ (1,0) [0|1] ""  C_ECU_GW
 SG_ CCU6A8_2_6_DOW_SET : 22|2@1+ (1,0) [0|1] ""  C_ECU_GW
 SG_ CCU6A8_2_4_RCTA_SET : 20|2@1+ (1,0) [0|1] ""  C_ECU_GW
 SG_ CCU6A8_2_2_BSD_LCA_2ND_SET : 18|2@1+ (1,0) [0|1] ""  C_ECU_GW
 SG_ CCU6A8_2_0_SRVD_SET : 16|2@1+ (1,0) [0|1] ""  C_ECU_GW
 SG_ CCU6A8_1_6_RCR_CSTM_RESET_REQ : 14|1@1+ (1,0) [0|1] ""  C_ECU_GW
 SG_ CCU6A8_1_4_BEV_CSTM_RESET_REQ : 12|1@1+ (1,0) [0|1] ""  C_ECU_GW
 SG_ CCU6A8_1_0_MSG_COUNTER : 8|4@1+ (1,0) [0|15] ""  C_ECU_GW
 SG_ CCU6A8_0_0_CHECK_SUM : 0|8@1+ (1,0) [0|255] ""  C_ECU_GW

BO_ 1149 CCU47D: 32 CCU
 SG_ CCU47D_3_0_AA_EST_CHG_TIME : 24|32@1+ (1,0) [0|4294967294] "sec"  C_ECU_GW
 SG_ CCU47D_2_0_E2E_COUNTER : 16|8@1+ (1,0) [0|255] ""  C_ECU_GW
 SG_ CCU47D_0_0_E2E_CRC : 0|16@1+ (1,0) [0|65535] ""  C_ECU_GW

BO_ 1148 CCU47C: 32 CCU
 SG_ CCU47C_7_0_AA_CRG_MAX_OUT_WAT : 56|32@1+ (1,0) [0|4294967294] "watts"  C_ECU_GW
 SG_ CCU47C_3_0_AA_DEP_MIN_BAT_LEVEL : 24|32@1+ (1,0) [0|4294967294] "wh"  C_ECU_GW
 SG_ CCU47C_2_0_E2E_COUNTER : 16|8@1+ (1,0) [0|255] ""  C_ECU_GW
 SG_ CCU47C_0_0_E2E_CRC : 0|16@1+ (1,0) [0|65535] ""  C_ECU_GW

BO_ 1146 CCU47A: 32 CCU
 SG_ CCU47A_24_0_MRM_OPERATION_INFO : 192|3@1+ (1,0) [0|6] ""  C_ECU_GW
 SG_ CCU47A_21_2_DATA_COLLECT_LOC : 170|2@1+ (1,0) [0|3] ""  C_ECU_GW
 SG_ CCU47A_21_0_DATA_COLLECT_IMAGE : 168|2@1+ (1,0) [0|3] ""  C_ECU_GW
 SG_ CCU47A_20_6_ADDON_CSTM : 166|2@1+ (1,0) [0|3] ""  C_ECU_GW
 SG_ CCU47A_20_4_EYE_LANE_SELECT_CONT : 164|2@1+ (1,0) [0|3] ""  C_ECU_GW
 SG_ CCU47A_20_2_DATA_COLLECT_CSTM : 162|2@1+ (1,0) [0|3] ""  C_ECU_GW
 SG_ CCU47A_20_0_V2N_CSTM : 160|2@1+ (1,0) [0|3] ""  C_ECU_GW
 SG_ CCU47A_19_6_PROPOSAL_HMI_CSTM : 158|2@1+ (1,0) [0|3] ""  C_ECU_GW
 SG_ CCU47A_19_4_EYE_LANE_SELECT_CSTM : 156|2@1+ (1,0) [0|3] ""  C_ECU_GW
 SG_ CCU47A_19_2_EYE_GREEN_LIGHT_CSTM : 154|2@1+ (1,0) [0|3] ""  C_ECU_GW
 SG_ CCU47A_19_0_LSW_CSTM : 152|2@1+ (1,0) [0|3] ""  C_ECU_GW
 SG_ CCU47A_16_0_ISA_IACC_ACCEPT_CONT : 128|2@1+ (1,0) [0|3] ""  C_ECU_GW
 SG_ CCU47A_15_0_SLWF_OFFSET_OV50 : 120|5@1+ (1,0) [0|31] ""  C_ECU_GW
 SG_ CCU47A_14_0_SLWF_OFFSET_U50 : 112|5@1+ (1,0) [0|31] ""  C_ECU_GW
 SG_ CCU47A_13_0_ISA_IACC_OFFSET_OV50 : 104|5@1+ (1,0) [0|31] ""  C_ECU_GW
 SG_ CCU47A_12_0_ISA_IACC_OFFSET_U50 : 96|5@1+ (1,0) [0|31] ""  C_ECU_GW
 SG_ CCU47A_11_5_SLWF_OFS_CONT : 93|2@1+ (1,0) [0|3] ""  C_ECU_GW
 SG_ CCU47A_11_3_ISA_IACC_OFS_CONT : 91|2@1+ (1,0) [0|3] ""  C_ECU_GW
 SG_ CCU47A_11_0_ISA_IACC_ACCEPT_CSTM : 88|3@1+ (1,0) [0|7] ""  C_ECU_GW
 SG_ CCU47A_10_6_EYE_LOADSIGNS_SYS : 86|2@1+ (1,0) [0|3] ""  C_ECU_GW
 SG_ CCU47A_10_4_SLWF_CSTM : 84|2@1+ (1,0) [0|3] ""  C_ECU_GW
 SG_ CCU47A_10_2_SIGN_SWITCH_SOUND : 82|2@1+ (1,0) [0|3] ""  C_ECU_GW
 SG_ CCU47A_10_0_EYE_LOADSIGNS_ADD : 80|2@1+ (1,0) [0|3] ""  C_ECU_GW
 SG_ CCU47A_6_6_TEMP_OFF_REQ : 54|1@1+ (1,0) [0|1] ""  C_ECU_GW
 SG_ CCU47A_6_2_CSTM_SONNER : 50|2@1+ (1,0) [0|3] ""  C_ECU_GW
 SG_ CCU47A_6_0_CSTM_RAB : 48|2@1+ (1,0) [0|3] ""  C_ECU_GW
 SG_ CCU47A_5_7_SNR_CSTM_RESET_REQ : 47|1@1+ (1,0) [0|1] ""  C_ECU_GW
 SG_ CCU47A_5_6_ADAS_CSTM_RESET_REQ : 46|1@1+ (1,0) [0|1] ""  C_ECU_GW
 SG_ CCU47A_5_2_PED_RAB_TIMING : 42|3@1+ (1,0) [0|7] ""  C_ECU_GW
 SG_ CCU47A_5_0_PED_RAB_ON_OFF : 40|2@1+ (1,0) [0|3] ""  C_ECU_GW
 SG_ CCU47A_3_0_EYE_CSTM_CHG_REQ_47A : 24|1@1+ (1,0) [0|1] ""  C_ECU_GW
 SG_ CCU47A_2_0_E2E_COUNTER : 16|8@1+ (1,0) [0|255] ""  C_ECU_GW
 SG_ CCU47A_0_0_E2E_CRC : 0|16@1+ (1,0) [0|65535] ""  C_ECU_GW

BO_ 1145 CCU479: 32 CCU
 SG_ CCU479_29_4_ACC_TGT_OPT_HIGHWAY : 236|2@1+ (1,0) [0|3] ""  C_ECU_GW
 SG_ CCU479_29_2_ACC_TGT_OPT_SLOWDOWN : 234|2@1+ (1,0) [0|3] ""  C_ECU_GW
 SG_ CCU479_29_0_ACC_TGT_OPT_STOP : 232|2@1+ (1,0) [0|3] ""  C_ECU_GW
 SG_ CCU479_28_2_EYE_ACC_FUNC_CONT : 226|2@1+ (1,0) [0|3] ""  C_ECU_GW
 SG_ CCU479_28_0_ACC_TARGET_OPT_CSTM : 224|2@1+ (1,0) [0|3] ""  C_ECU_GW
 SG_ CCU479_27_5_EYE_ACC_SYS_CSTM : 221|2@1+ (1,0) [0|3] ""  C_ECU_GW
 SG_ CCU479_27_3_ACC_OVERTAKE_CSTM : 219|2@1+ (1,0) [0|3] ""  C_ECU_GW
 SG_ CCU479_27_0_EYE_ACC_CONT_CSTM : 216|3@1+ (1,0) [0|7] ""  C_ECU_GW
 SG_ CCU479_24_4_EYE_LKS_OPT_OFFSET : 196|2@1+ (1,0) [0|3] ""  C_ECU_GW
 SG_ CCU479_24_2_EYE_LKS_OPT_NAVI : 194|2@1+ (1,0) [0|3] ""  C_ECU_GW
 SG_ CCU479_24_0_EYE_LKS_OPT_AUTOPASS : 192|2@1+ (1,0) [0|3] ""  C_ECU_GW
 SG_ CCU479_23_2_EYE_LKS_OPT_CONT : 186|2@1+ (1,0) [0|3] ""  C_ECU_GW
 SG_ CCU479_23_0_EYE_ACTIVE_LKS_CSTM : 184|2@1+ (1,0) [0|3] ""  C_ECU_GW
 SG_ CCU479_21_4_EYE_ELK_CTRL_CSTM : 172|2@1+ (1,0) [0|3] ""  C_ECU_GW
 SG_ CCU479_21_2_EYE_ELK_VIB_CSTM : 170|2@1+ (1,0) [0|3] ""  C_ECU_GW
 SG_ CCU479_21_0_EYE_ELK_SOUND_CSTM : 168|2@1+ (1,0) [0|3] ""  C_ECU_GW
 SG_ CCU479_20_6_ELK_ASSISTTYPE_CONT : 166|2@1+ (1,0) [0|3] ""  C_ECU_GW
 SG_ CCU479_20_4_EYE_LDW_TIMING_CONT : 164|2@1+ (1,0) [0|3] ""  C_ECU_GW
 SG_ CCU479_20_2_LDW_OFF_EXE : 162|2@1+ (1,0) [0|3] ""  C_ECU_GW
 SG_ CCU479_20_0_EYE_ELK_CSTM : 160|2@1+ (1,0) [0|3] ""  C_ECU_GW
 SG_ CCU479_19_6_LDP_TARGET_SIDE_VHCL : 158|2@1+ (1,0) [0|3] ""  C_ECU_GW
 SG_ CCU479_19_4_LDP_TARGET_SIDE_OBJ : 156|2@1+ (1,0) [0|3] ""  C_ECU_GW
 SG_ CCU479_19_2_LDP_TARGET_DASHLINE : 154|2@1+ (1,0) [0|3] ""  C_ECU_GW
 SG_ CCU479_19_0_LDP_TARGET_SOLIDLINE : 152|2@1+ (1,0) [0|3] ""  C_ECU_GW
 SG_ CCU479_18_6_LDP_TARGET_CONT : 150|2@1+ (1,0) [0|3] ""  C_ECU_GW
 SG_ CCU479_18_4_LANE_DEP_LDP_CSTM : 148|2@1+ (1,0) [0|3] ""  C_ECU_GW
 SG_ CCU479_18_2_LANE_DEP_LDW_VI_CSTM : 146|2@1+ (1,0) [0|3] ""  C_ECU_GW
 SG_ CCU479_18_0_LANE_DEP_LDW_SO_CSTM : 144|2@1+ (1,0) [0|3] ""  C_ECU_GW
 SG_ CCU479_17_5_LANE_DEP_LDW_CONT : 141|2@1+ (1,0) [0|3] ""  C_ECU_GW
 SG_ CCU479_17_2_EYE_LDW_TIMING_CSTM : 138|3@1+ (1,0) [0|7] ""  C_ECU_GW
 SG_ CCU479_17_0_LANE_DEPARTURE_CSTM : 136|2@1+ (1,0) [0|3] ""  C_ECU_GW
 SG_ CCU479_16_2_EYE_MIS_AT_BACK_CONT : 130|2@1+ (1,0) [0|3] ""  C_ECU_GW
 SG_ CCU479_16_0_EYE_SAFTY_MODE_SENS : 128|2@1+ (1,0) [0|3] ""  C_ECU_GW
 SG_ CCU479_15_6_FCTI_NOTICE_CONT : 126|2@1+ (1,0) [0|3] ""  C_ECU_GW
 SG_ CCU479_15_4_FCW_TYPE_CONT : 124|2@1+ (1,0) [0|3] ""  C_ECU_GW
 SG_ CCU479_15_2_FCW_TIMING_CONT : 122|2@1+ (1,0) [0|3] ""  C_ECU_GW
 SG_ CCU479_15_0_BRAKE_TIMING_CONT : 120|2@1+ (1,0) [0|3] ""  C_ECU_GW
 SG_ CCU479_14_5_FCW_OFF_EXE : 117|2@1+ (1,0) [0|3] ""  C_ECU_GW
 SG_ CCU479_14_2_EYE_MIS_AT_BACK_LV : 114|3@1+ (1,0) [0|7] ""  C_ECU_GW
 SG_ CCU479_14_0_EYE_MIS_AT_BACK_CSTM : 112|2@1+ (1,0) [0|3] ""  C_ECU_GW
 SG_ CCU479_13_2_FCTI_PULSE_CSTM : 106|2@1+ (1,0) [0|3] ""  C_ECU_GW
 SG_ CCU479_13_0_FCTI_SOUND_CSTM : 104|2@1+ (1,0) [0|3] ""  C_ECU_GW
 SG_ CCU479_12_4_EYE_SAFTY_MODE_LV : 100|3@1+ (1,0) [0|7] ""  C_ECU_GW
 SG_ CCU479_12_2_EYE_SAFTY_MODE_CSTM : 98|2@1+ (1,0) [0|3] ""  C_ECU_GW
 SG_ CCU479_12_0_FCTI_CONT_CSTM : 96|2@1+ (1,0) [0|3] ""  C_ECU_GW
 SG_ CCU479_11_2_FCW_TYPE_PULSE_CSTM : 90|2@1+ (1,0) [0|3] ""  C_ECU_GW
 SG_ CCU479_11_0_FCW_TYPE_SOUND_CSTM : 88|2@1+ (1,0) [0|3] ""  C_ECU_GW
 SG_ CCU479_10_5_FCW_TIMING_CSTM : 85|3@1+ (1,0) [0|7] ""  C_ECU_GW
 SG_ CCU479_10_2_BRAKE_TIMING_CSTM : 82|3@1+ (1,0) [0|7] ""  C_ECU_GW
 SG_ CCU479_10_0_EYE_P_CR_CSTM : 80|2@1+ (1,0) [0|3] ""  C_ECU_GW
 SG_ CCU479_6_4_SUPPRESS_SPD_TGT_SLO : 52|2@1+ (1,0) [0|3] ""  C_ECU_GW
 SG_ CCU479_6_2_SUPPRESS_SPD_TGT_SUR : 50|2@1+ (1,0) [0|3] ""  C_ECU_GW
 SG_ CCU479_6_0_SUPPRESS_SPD_TGT_VEH : 48|2@1+ (1,0) [0|3] ""  C_ECU_GW
 SG_ CCU479_5_5_ACTIVE_AVOIDANCE_LV : 45|3@1+ (1,0) [0|7] ""  C_ECU_GW
 SG_ CCU479_5_3_ACTIVE_AVOIDANCE : 43|2@1+ (1,0) [0|3] ""  C_ECU_GW
 SG_ CCU479_5_0_SUPPRESS_SPEED_LEVEL : 40|3@1+ (1,0) [0|7] ""  C_ECU_GW
 SG_ CCU479_4_4_SUPPRESS_SPD_TGT_CONT : 36|2@1+ (1,0) [0|3] ""  C_ECU_GW
 SG_ CCU479_4_2_SUPPRESS_SPEED_CSTM : 34|2@1+ (1,0) [0|3] ""  C_ECU_GW
 SG_ CCU479_4_0_PDA_CSTM : 32|2@1+ (1,0) [0|3] ""  C_ECU_GW
 SG_ CCU479_3_1_FAIL_CCU_TO_EYE : 25|2@1+ (1,0) [0|3] ""  C_ECU_GW
 SG_ CCU479_3_0_CCU_VALID : 24|1@1+ (1,0) [0|1] ""  C_ECU_GW
 SG_ CCU479_2_0_E2E_COUNTER : 16|8@1+ (1,0) [0|255] ""  C_ECU_GW
 SG_ CCU479_0_0_E2E_CRC : 0|16@1+ (1,0) [0|65535] ""  C_ECU_GW

BO_ 1144 CCU478: 32 CCU
 SG_ CCU478_25_0_LAT_CHG_WEEK_DAYS : 200|8@1+ (1,0) [0|255] ""  C_ECU_GW
 SG_ CCU478_24_3_Reserved : 195|5@1+ (1,0) [0|31] ""  C_ECU_GW
 SG_ CCU478_23_0_LAT_CHG_END_TIME : 184|11@1+ (1,0) [0|1439] "min"  C_ECU_GW
 SG_ CCU478_22_5_Reserved : 181|3@1+ (1,0) [0|7] ""  C_ECU_GW
 SG_ CCU478_21_2_LAT_CHG_START_TIME : 170|11@1+ (1,0) [0|1439] "min"  C_ECU_GW
 SG_ CCU478_21_0_LAT_CHG_SET_TYPE : 168|2@1+ (1,0) [0|3] ""  C_ECU_GW
 SG_ CCU478_20_6_Reserved : 166|2@1+ (1,0) [0|3] ""  C_ECU_GW
 SG_ CCU478_20_2_TIRE_SIZE : 162|4@1+ (1,0) [0|7] ""  C_ECU_GW
 SG_ CCU478_20_0_TIRE_TYPE : 160|2@1+ (1,0) [0|3] ""  C_ECU_GW
 SG_ CCU478_19_4_Reserved : 156|2@1+ (1,0) [0|3] ""  C_ECU_GW
 SG_ CCU478_19_2_SW_PFO_MOD_CHG : 154|2@1+ (1,0) [0|2] ""  C_ECU_GW
 SG_ CCU478_19_0_DEP_TIM_CHG_FLG : 152|1@1+ (1,0) [0|3] ""  DCM,C_ECU_GW
 SG_ CCU478_18_0_DEP_TIM4_WEEK_DAYS : 144|8@1+ (1,0) [0|255] ""  DCM,C_ECU_GW
 SG_ CCU478_17_3_Reserved : 139|5@1+ (1,0) [0|31] ""  C_ECU_GW
 SG_ CCU478_16_0_DEP_TIM4_START_TIME : 128|11@1+ (1,0) [0|1439] "min"  DCM,C_ECU_GW
 SG_ CCU478_15_7_DEP_TIM4_PER_FLG : 127|1@1+ (1,0) [0|1] ""  DCM,C_ECU_GW
 SG_ CCU478_15_5_DEP_TIM4_SW_STS : 125|2@1+ (1,0) [0|3] ""  DCM,C_ECU_GW
 SG_ CCU478_15_0_TIM4_DISP_ID : 120|5@1+ (1,0) [0|31] ""  DCM,C_ECU_GW
 SG_ CCU478_14_0_DEP_TIM3_WEEK_DAYS : 112|8@1+ (1,0) [0|255] ""  DCM,C_ECU_GW
 SG_ CCU478_13_3_Reserved : 107|5@1+ (1,0) [0|31] ""  C_ECU_GW
 SG_ CCU478_12_0_DEP_TIM3_START_TIME : 96|11@1+ (1,0) [0|1439] "min"  DCM,C_ECU_GW
 SG_ CCU478_11_7_DEP_TIM3_PER_FLG : 95|1@1+ (1,0) [0|1] ""  DCM,C_ECU_GW
 SG_ CCU478_11_5_DEP_TIM3_SW_STS : 93|2@1+ (1,0) [0|3] ""  DCM,C_ECU_GW
 SG_ CCU478_11_0_TIM3_DISP_ID : 88|5@1+ (1,0) [0|31] ""  DCM,C_ECU_GW
 SG_ CCU478_10_0_DEP_TIM2_WEEK_DAYS : 80|8@1+ (1,0) [0|255] ""  DCM,C_ECU_GW
 SG_ CCU478_9_3_Reserved : 75|5@1+ (1,0) [0|31] ""  C_ECU_GW
 SG_ CCU478_8_0_DEP_TIM2_START_TIME : 64|11@1+ (1,0) [0|1439] "min"  DCM,C_ECU_GW
 SG_ CCU478_7_7_DEP_TIM2_PER_FLG : 63|1@1+ (1,0) [0|1] ""  DCM,C_ECU_GW
 SG_ CCU478_7_5_DEP_TIM2_SW_STS : 61|2@1+ (1,0) [0|3] ""  DCM,C_ECU_GW
 SG_ CCU478_7_0_TIM2_DISP_ID : 56|5@1+ (1,0) [0|31] ""  DCM,C_ECU_GW
 SG_ CCU478_6_0_DEP_TIM1_WEEK_DAYS : 48|8@1+ (1,0) [0|255] ""  DCM,C_ECU_GW
 SG_ CCU478_5_3_Reserved : 43|5@1+ (1,0) [0|31] ""  C_ECU_GW
 SG_ CCU478_4_0_DEP_TIM1_START_TIME : 32|11@1+ (1,0) [0|1439] "min"  DCM,C_ECU_GW
 SG_ CCU478_3_7_DEP_TIM1_PER_FLG : 31|1@1+ (1,0) [0|1] ""  DCM,C_ECU_GW
 SG_ CCU478_3_5_DEP_TIM1_SW_STS : 29|2@1+ (1,0) [0|3] ""  DCM,C_ECU_GW
 SG_ CCU478_3_0_TIM1_DISP_ID : 24|5@1+ (1,0) [0|31] ""  DCM,C_ECU_GW
 SG_ CCU478_2_0_E2E_COUNTER : 16|8@1+ (1,0) [0|255] ""  DCM,C_ECU_GW
 SG_ CCU478_0_0_E2E_CRC : 0|16@1+ (1,0) [0|65535] ""  DCM,C_ECU_GW

BO_ 1143 CCU477: 32 CCU
 SG_ CCU477_28_4_Reserved : 228|4@1+ (1,0) [0|16] ""  C_ECU_GW
 SG_ CCU477_28_2_TIM_CHG_CHG_FLG : 226|1@1+ (1,0) [0|3] ""  DCM,C_ECU_GW
 SG_ CCU477_28_0_TIM_CHG_ICON_DISP : 224|2@1+ (1,0) [0|3] ""  C_ECU_GW
 SG_ CCU477_27_4_TIM_CHG_STATUS : 220|4@1+ (1,0) [0|15] ""  C_ECU_GW
 SG_ CCU477_27_1_DEP_TIM_PRE_CON_FLAG : 217|3@1+ (1,0) [0|7] ""  C_ECU,C_ECU_GW
 SG_ CCU477_27_0_TIM_CHG_PERM_FLAG : 216|1@1+ (1,0) [0|1] ""  C_ECU,C_ECU_GW
 SG_ CCU477_26_0_TIM4_CHG_WEEK_DAYS : 208|8@1+ (1,0) [0|255] ""  DCM,C_ECU_GW
 SG_ CCU477_25_3_Reserved : 203|5@1+ (1,0) [0|31] ""  C_ECU_GW
 SG_ CCU477_24_0_TIM4_CHG_END_TIME : 192|11@1+ (1,0) [0|1439] "min"  DCM,C_ECU_GW
 SG_ CCU477_23_5_Reserved : 189|3@1+ (1,0) [0|7] ""  C_ECU_GW
 SG_ CCU477_22_2_TIM4_CHG_START_TIME : 178|11@1+ (1,0) [0|1439] "min"  DCM,C_ECU_GW
 SG_ CCU477_22_0_TIM4_CHG_SET_TYPE : 176|2@1+ (1,0) [0|3] ""  DCM,C_ECU_GW
 SG_ CCU477_21_7_Reserved : 175|1@1+ (1,0) [0|1] ""  C_ECU_GW
 SG_ CCU477_21_5_TIM4_CHG_SW_STS : 173|2@1+ (1,0) [0|3] ""  DCM,C_ECU_GW
 SG_ CCU477_21_0_TIM4_DISP_ID : 168|5@1+ (1,0) [0|31] ""  DCM,C_ECU_GW
 SG_ CCU477_20_0_TIM3_CHG_WEEK_DAYS : 160|8@1+ (1,0) [0|255] ""  DCM,C_ECU_GW
 SG_ CCU477_19_3_Reserved : 155|5@1+ (1,0) [0|31] ""  C_ECU_GW
 SG_ CCU477_18_0_TIM3_CHG_END_TIME : 144|11@1+ (1,0) [0|1439] "min"  DCM,C_ECU_GW
 SG_ CCU477_17_5_Reserved : 141|3@1+ (1,0) [0|7] ""  C_ECU_GW
 SG_ CCU477_16_2_TIM3_CHG_START_TIME : 130|11@1+ (1,0) [0|1439] "min"  DCM,C_ECU_GW
 SG_ CCU477_16_0_TIM3_CHG_SET_TYPE : 128|2@1+ (1,0) [0|3] ""  DCM,C_ECU_GW
 SG_ CCU477_15_7_Reserved : 127|1@1+ (1,0) [0|1] ""  C_ECU_GW
 SG_ CCU477_15_5_TIM3_CHG_SW_STS : 125|2@1+ (1,0) [0|3] ""  DCM,C_ECU_GW
 SG_ CCU477_15_0_TIM3_DISP_ID : 120|5@1+ (1,0) [0|31] ""  DCM,C_ECU_GW
 SG_ CCU477_14_0_TIM2_CHG_WEEK_DAYS : 112|8@1+ (1,0) [0|255] ""  DCM,C_ECU_GW
 SG_ CCU477_13_3_Reserved : 107|5@1+ (1,0) [0|31] ""  C_ECU_GW
 SG_ CCU477_12_0_TIM2_CHG_END_TIME : 96|11@1+ (1,0) [0|1439] "min"  DCM,C_ECU_GW
 SG_ CCU477_11_5_Reserved : 93|3@1+ (1,0) [0|7] ""  C_ECU_GW
 SG_ CCU477_10_2_TIM2_CHG_START_TIME : 82|11@1+ (1,0) [0|1439] "min"  DCM,C_ECU_GW
 SG_ CCU477_10_0_TIM2_CHG_SET_TYPE : 80|2@1+ (1,0) [0|3] ""  DCM,C_ECU_GW
 SG_ CCU477_9_7_Reserved : 79|1@1+ (1,0) [0|1] ""  C_ECU_GW
 SG_ CCU477_9_5_TIM2_CHG_SW_STS : 77|2@1+ (1,0) [0|3] ""  DCM,C_ECU_GW
 SG_ CCU477_9_0_TIM2_DISP_ID : 72|5@1+ (1,0) [0|31] ""  DCM,C_ECU_GW
 SG_ CCU477_8_0_TIM1_CHG_WEEK_DAYS : 64|8@1+ (1,0) [0|255] ""  DCM,C_ECU_GW
 SG_ CCU477_7_3_Reserved : 59|5@1+ (1,0) [0|31] ""  C_ECU_GW
 SG_ CCU477_6_0_TIM1_CHG_END_TIME : 48|11@1+ (1,0) [0|1439] "min"  DCM,C_ECU_GW
 SG_ CCU477_5_5_Reserved : 45|3@1+ (1,0) [0|7] ""  C_ECU_GW
 SG_ CCU477_4_2_TIM1_CHG_START_TIME : 34|11@1+ (1,0) [0|1439] "min"  DCM,C_ECU_GW
 SG_ CCU477_4_0_TIM1_CHG_SET_TYPE : 32|2@1+ (1,0) [0|3] ""  DCM,C_ECU_GW
 SG_ CCU477_3_7_Reserved : 31|1@1+ (1,0) [0|1] ""  C_ECU_GW
 SG_ CCU477_3_5_TIM1_CHG_SW_STS : 29|2@1+ (1,0) [0|3] ""  DCM,C_ECU_GW
 SG_ CCU477_3_0_TIM1_DISP_ID : 24|5@1+ (1,0) [0|31] ""  DCM,C_ECU_GW
 SG_ CCU477_2_0_E2E_COUNTER : 16|8@1+ (1,0) [0|255] ""  DCM,C_ECU,C_ECU_GW
 SG_ CCU477_0_0_E2E_CRC : 0|16@1+ (1,0) [0|65535] ""  DCM,C_ECU,C_ECU_GW

BO_ 1142 CCU476: 32 CCU
 SG_ CCU476_17_2_SW_STOP_CHG : 138|1@1+ (1,0) [0|1] ""  C_ECU_GW
 SG_ CCU476_17_1_SW_NORMAL_MOD_CHG : 137|1@1+ (1,0) [0|1] ""  C_ECU_GW
 SG_ CCU476_17_0_SW_PWR_MOD_CHG : 136|1@1+ (1,0) [0|1] ""  C_ECU_GW
 SG_ CCU476_16_4_AC_CUR_MAX_LIM_CHG : 132|4@1+ (1,0) [0|6] "A"  C_ECU_GW
 SG_ CCU476_16_0_DC_PWR_MAX_LIM_CHG : 128|4@1+ (1,0) [0|8] "kW"  C_ECU_GW
 SG_ CCU476_15_0_SOC_MAX_LIM_CHG : 120|7@1+ (1,0) [0|100] "%"  C_ECU_GW
 SG_ CCU476_14_0_HIS_ID_PNC : 112|7@1+ (1,0) [0|100] ""  C_ECU_GW
 SG_ CCU476_13_5_SW_CAUTION_PNC : 109|1@1+ (1,0) [0|1] ""  C_ECU_GW
 SG_ CCU476_13_4_SW_NEW_PNC : 108|1@1+ (1,0) [0|1] ""  C_ECU_GW
 SG_ CCU476_13_3_START_CTR_PNC : 107|1@1+ (1,0) [0|1] ""  C_ECU_GW
 SG_ CCU476_13_1_STS_PNC : 105|2@1+ (1,0) [0|3] ""  C_ECU_GW
 SG_ CCU476_13_0_DESC_PNC : 104|1@1+ (1,0) [0|1] ""  C_ECU_GW
 SG_ CCU476_11_1_STOP_TIM_TIM_CHG : 89|9@1+ (5,0) [0|1435] ""  C_ECU_GW
 SG_ CCU476_10_0_START_TIM_TIM_CHG : 80|9@1+ (5,0) [0|1435] ""  C_ECU_GW
 SG_ CCU476_9_0_WKD_SET_TIM_CHG : 72|3@1+ (1,0) [0|7] ""  C_ECU_GW
 SG_ CCU476_8_0_LOGIN_REQ_TIM_CHG : 64|2@1+ (1,0) [0|3] ""  C_ECU_GW
 SG_ CCU476_7_0_WKD_SEL_TIM_CHG : 56|7@1+ (1,0) [0|127] ""  C_ECU_GW
 SG_ CCU476_5_1_STOP_TIM_CH_TIM_CHG : 41|9@1+ (5,0) [0|1435] ""  C_ECU_GW
 SG_ CCU476_4_0_START_TIM_CH_TIM_CHG : 32|9@1+ (5,0) [0|1435] ""  C_ECU_GW
 SG_ CCU476_3_0_PNC_SW_REQ_CCU : 24|3@1+ (1,0) [0|5] ""  C_ECU_GW
 SG_ CCU476_2_7_SW_TIM_CHG : 23|1@1+ (1,0) [0|1] ""  C_ECU_GW
 SG_ CCU476_2_0_E2E_COUNTER : 16|8@1+ (1,0) [0|255] ""  C_ECU_GW
 SG_ CCU476_0_0_E2E_CRC : 0|16@1+ (1,0) [0|65535] ""  C_ECU_GW

BO_ 1141 CCU475: 32 CCU
 SG_ CCU475_4_0_SOC_MIN_PWR_SPL : 32|7@1+ (1,0) [0|100] "%"  C_ECU_GW
 SG_ CCU475_3_4_Reserved : 28|4@1+ (1,0) [0|15] ""  C_ECU_GW
 SG_ CCU475_3_2_SW_PWR_SPL_DC : 26|2@1+ (1,0) [0|2] ""  C_ECU_GW
 SG_ CCU475_3_0_SW_PWR_SPL_AC : 24|2@1+ (1,0) [0|3] ""  C_ECU_GW
 SG_ CCU475_2_0_E2E_COUNTER : 16|8@1+ (1,0) [0|255] ""  C_ECU_GW
 SG_ CCU475_0_0_E2E_CRC : 0|16@1+ (1,0) [0|65535] ""  C_ECU_GW

BO_ 927 AVN39F: 8 CCU

BO_ 1112 CCU458: 8 CCU
 SG_ CCU458_7_0_BYTE5 : 56|8@1+ (1,0) [0|255] ""  C_ECU_GW
 SG_ CCU458_6_0_BYTE4 : 48|8@1+ (1,0) [0|255] ""  C_ECU_GW
 SG_ CCU458_5_0_BYTE3 : 40|8@1+ (1,0) [0|255] ""  C_ECU_GW
 SG_ CCU458_4_0_BYTE2 : 32|8@1+ (1,0) [0|255] ""  C_ECU_GW
 SG_ CCU458_3_0_BYTE1 : 24|8@1+ (1,0) [0|255] ""  C_ECU_GW
 SG_ CCU458_2_0_E2E_COUNTER : 16|8@1+ (1,0) [0|255] ""  C_ECU_GW
 SG_ CCU458_0_0_E2E_CRC : 0|16@1+ (1,0) [0|65535] ""  C_ECU_GW

BO_ 1105 CCU451: 32 CCU
 SG_ CCU451_31_0_BYTE26 : 248|8@1+ (1,0) [0|255] ""  C_ECU_GW
 SG_ CCU451_30_0_BYTE25 : 240|8@1+ (1,0) [0|255] ""  C_ECU_GW
 SG_ CCU451_29_0_BYTE24 : 232|8@1+ (1,0) [0|255] ""  C_ECU_GW
 SG_ CCU451_28_0_BYTE23 : 224|8@1+ (1,0) [0|255] ""  C_ECU_GW
 SG_ CCU451_27_0_BYTE22 : 216|8@1+ (1,0) [0|255] ""  C_ECU_GW
 SG_ CCU451_26_0_BYTE21 : 208|8@1+ (1,0) [0|255] ""  C_ECU_GW
 SG_ CCU451_25_0_BYTE20 : 200|8@1+ (1,0) [0|255] ""  C_ECU_GW
 SG_ CCU451_24_0_BYTE19 : 192|8@1+ (1,0) [0|255] ""  C_ECU_GW
 SG_ CCU451_23_0_BYTE18 : 184|8@1+ (1,0) [0|255] ""  C_ECU_GW
 SG_ CCU451_22_0_BYTE17 : 176|8@1+ (1,0) [0|255] ""  C_ECU_GW
 SG_ CCU451_21_0_BYTE16 : 168|8@1+ (1,0) [0|255] ""  C_ECU_GW
 SG_ CCU451_20_0_BYTE15 : 160|8@1+ (1,0) [0|255] ""  C_ECU_GW
 SG_ CCU451_19_0_BYTE14 : 152|8@1+ (1,0) [0|255] ""  C_ECU_GW
 SG_ CCU451_18_0_BYTE13 : 144|8@1+ (1,0) [0|255] ""  C_ECU_GW
 SG_ CCU451_17_0_BYTE12 : 136|8@1+ (1,0) [0|255] ""  C_ECU_GW
 SG_ CCU451_16_0_BYTE11 : 128|8@1+ (1,0) [0|255] ""  C_ECU_GW
 SG_ CCU451_15_0_BYTE10 : 120|8@1+ (1,0) [0|255] ""  C_ECU_GW
 SG_ CCU451_14_0_BYTE9 : 112|8@1+ (1,0) [0|255] ""  C_ECU_GW
 SG_ CCU451_13_0_BYTE8 : 104|8@1+ (1,0) [0|255] ""  C_ECU_GW
 SG_ CCU451_12_0_BYTE7 : 96|8@1+ (1,0) [0|255] ""  C_ECU_GW
 SG_ CCU451_11_0_BYTE6 : 88|8@1+ (1,0) [0|255] ""  C_ECU_GW
 SG_ CCU451_10_0_BYTE5 : 80|8@1+ (1,0) [0|255] ""  C_ECU_GW
 SG_ CCU451_9_0_BYTE4 : 72|8@1+ (1,0) [0|255] ""  C_ECU_GW
 SG_ CCU451_8_0_CHG_BTN_FLG_CCU : 64|3@1+ (1,0) [0|4] ""  DCM,C_ECU_GW
 SG_ CCU451_8_3_CHG_CNG_FLG_CCU : 67|1@1+ (1,0) [0|1] ""  DCM,C_ECU_GW
 SG_ CCU451_8_4_Reserved : 68|4@1+ (1,0) [0|15] ""  C_ECU_GW
 SG_ CCU451_7_3_Reserved : 59|5@1+ (1,0) [0|31] ""  C_ECU_GW
 SG_ CCU451_6_0_CHG_COMTI : 48|11@1+ (1,0) [0|1439] ""  C_ECU_GW
 SG_ CCU451_5_0_SW_RIGHT_NOW_PRE_CON : 40|2@1+ (1,0) [0|4] ""  C_ECU_GW
 SG_ CCU451_5_2_Reserved : 42|6@1+ (1,0) [0|63] ""  C_ECU_GW
 SG_ CCU451_4_1_CHG_HILMT_REQ : 33|7@1+ (1,0) [50|100] "%"  C_ECU_GW
 SG_ CCU451_4_0_CHG_STP_REQ : 32|1@1+ (1,0) [0|1] ""  C_ECU_GW
 SG_ CCU451_3_4_DCCHG_PWRUPLMT : 28|4@1+ (1,0) [0|15] ""  C_ECU_GW
 SG_ CCU451_3_0_ACCHG_CORUPLMT : 24|4@1+ (1,0) [0|15] ""  C_ECU_GW
 SG_ CCU451_2_0_E2E_COUNTER : 16|8@1+ (1,0) [0|255] ""  DCM,C_ECU_GW
 SG_ CCU451_0_0_E2E_CRC : 0|16@1+ (1,0) [0|65535] ""  DCM,C_ECU_GW

BO_ 1665 CECU681: 8 C_ECU
 SG_ CECU681_6_7_DP_CHANGE_SET_REQ : 55|1@1+ (1,0) [0|1] ""  CCU
 SG_ CECU681_6_4_SMT_LINK : 52|1@1+ (1,0) [0|1] ""  CCU
 SG_ CECU681_6_3_IPMS_LINK : 51|1@1+ (1,0) [0|1] ""  CCU
 SG_ CECU681_5_6_DP_DKYMEM_LIST_NO15 : 46|1@1+ (1,0) [0|1] ""  CCU
 SG_ CECU681_5_5_DP_DKYMEM_LIST_NO14 : 45|1@1+ (1,0) [0|1] ""  CCU
 SG_ CECU681_5_4_DP_DKYMEM_LIST_NO13 : 44|1@1+ (1,0) [0|1] ""  CCU
 SG_ CECU681_5_3_DP_DKYMEM_LIST_NO12 : 43|1@1+ (1,0) [0|1] ""  CCU
 SG_ CECU681_5_2_DP_DKYMEM_LIST_NO11 : 42|1@1+ (1,0) [0|1] ""  CCU
 SG_ CECU681_5_1_DP_DKYMEM_LIST_NO10 : 41|1@1+ (1,0) [0|1] ""  CCU
 SG_ CECU681_5_0_DP_DKYMEM_LIST_NO9 : 40|1@1+ (1,0) [0|1] ""  CCU
 SG_ CECU681_4_7_DP_DKYMEM_LIST_NO8 : 39|1@1+ (1,0) [0|1] ""  CCU
 SG_ CECU681_4_6_DP_DKYMEM_LIST_NO7 : 38|1@1+ (1,0) [0|1] ""  CCU
 SG_ CECU681_4_5_DP_DKYMEM_LIST_NO6 : 37|1@1+ (1,0) [0|1] ""  CCU
 SG_ CECU681_4_4_DP_DKYMEM_LIST_NO5 : 36|1@1+ (1,0) [0|1] ""  CCU
 SG_ CECU681_4_3_DP_DKYMEM_LIST_NO4 : 35|1@1+ (1,0) [0|1] ""  CCU
 SG_ CECU681_4_2_DP_DKYMEM_LIST_NO3 : 34|1@1+ (1,0) [0|1] ""  CCU
 SG_ CECU681_4_1_DP_DKYMEM_LIST_NO2 : 33|1@1+ (1,0) [0|1] ""  CCU
 SG_ CECU681_4_0_DP_DKYMEM_LIST_NO1 : 32|1@1+ (1,0) [0|1] ""  CCU
 SG_ CECU681_3_5_RECOG_FACTOR : 29|3@1+ (1,0) [0|7] ""  CCU
 SG_ CECU681_3_4_RECOG_USER_VALIDFRAG : 28|1@1+ (1,0) [0|1] ""  CCU
 SG_ CECU681_3_0_RESULT_NOTICE_REQ : 24|4@1+ (1,0) [0|15] ""  CCU
 SG_ CECU681_2_4_RECOG_USER_NO : 20|4@1+ (1,0) [0|15] ""  CCU
 SG_ CECU681_2_0_POPUP_NOTICE_NO : 16|4@1+ (1,0) [0|15] ""  CCU
 SG_ CECU681_1_7_DP_FAILE_FRAG : 15|1@1+ (1,0) [0|1] ""  CCU
 SG_ CECU681_1_5_DP_PROCESS_RESULT : 13|2@1+ (1,0) [0|3] ""  CCU
 SG_ CECU681_1_4_POPUP_NOTICE_REQ : 12|1@1+ (1,0) [0|1] ""  CCU
 SG_ CECU681_1_0_MSG_COUNTER : 8|4@1+ (1,0) [0|15] ""  CCU
 SG_ CECU681_0_0_CHECK_SUM : 0|8@1+ (1,0) [0|255] ""  CCU

BO_ 1664 CECU680: 32 C_ECU
 SG_ CECU680_7_0_RSLT_DEV : 56|8@1+ (1,0) [0|79] ""  CCU
 SG_ CECU680_6_4_SDK_PRG : 52|3@1+ (1,0) [0|7] ""  CCU
 SG_ CECU680_6_0_RSLT_AUTHORITY : 48|4@1+ (1,0) [0|3] ""  CCU
 SG_ CECU680_5_6_RDK_SWAPGRL : 46|2@1+ (1,0) [0|2] "" Vector__XXX
 SG_ CECU680_5_4_RDK_ORRL : 44|2@1+ (1,0) [0|2] ""  CCU
 SG_ CECU680_4_6_RDK_ADRL : 38|2@1+ (1,0) [0|2] ""  CCU
 SG_ CECU680_4_4_RDK_ODRL : 36|2@1+ (1,0) [0|2] ""  CCU
 SG_ CECU680_4_2_RDK_FDRL : 34|2@1+ (1,0) [0|2] ""  CCU
 SG_ CECU680_4_0_RDK_OGRL : 32|2@1+ (1,0) [0|2] ""  CCU
 SG_ CECU680_3_7_ADK_ADLA : 31|1@1+ (1,0) [0|1] ""  CCU
 SG_ CECU680_3_6_ADK_OWDA : 30|1@1+ (1,0) [0|1] ""  CCU
 SG_ CECU680_3_4_ADK_REGA : 28|1@1+ (1,0) [0|1] "" Vector__XXX
 SG_ CECU680_3_3_ADK_STCA : 27|1@1+ (1,0) [0|1] "" Vector__XXX
 SG_ CECU680_3_2_ADK_SWAPSTACA : 26|1@1+ (1,0) [0|1] "" Vector__XXX
 SG_ CECU680_3_1_ADK_FWDA : 25|1@1+ (1,0) [0|1] ""  CCU
 SG_ CECU680_3_0_ADK_SWAPWDA : 24|1@1+ (1,0) [0|1] ""  CCU
 SG_ CECU680_2_0_E2E_COUNTER : 16|8@1+ (1,0) [0|255] ""  CCU
 SG_ CECU680_0_0_E2E_CRC : 0|16@1+ (1,0) [0|65535] ""  CCU

BO_ 1726 CCU6BE: 32 CCU
 SG_ CCU6BE_10_0_CCU_BOOT_STATE : 80|3@1+ (1,0) [0|7] ""  C_ECU_GW
 SG_ CCU6BE_9_0_DISP_DRAINAGE : 72|4@1+ (1,0) [0|5] ""  C_ECU_GW
 SG_ CCU6BE_8_0_DISP_POURING_WATER : 64|4@1+ (1,0) [0|13] ""  C_ECU_GW
 SG_ CCU6BE_7_4_QDK_DEV : 60|4@1+ (1,0) [0|15] ""  C_ECU,C_ECU_GW
 SG_ CCU6BE_5_0_SLOTID_ERASE : 40|16@1+ (1,0) [0|65535] ""  C_ECU,C_ECU_GW
 SG_ CCU6BE_4_2_QDK_OSWAP : 34|2@1+ (1,0) [0|2] ""  C_ECU,C_ECU_GW
 SG_ CCU6BE_4_4_QDK_FDRQ : 36|2@1+ (1,0) [0|2] ""  C_ECU,C_ECU_GW
 SG_ CCU6BE_4_6_QDK_OWCQ : 38|2@1+ (1,0) [0|2] ""  C_ECU,C_ECU_GW
 SG_ CCU6BE_3_0_QDK_ORRQ : 24|2@1+ (1,0) [0|2] ""  C_ECU,C_ECU_GW
 SG_ CCU6BE_3_2_QDK_OGRQ : 26|2@1+ (1,0) [0|2] ""  C_ECU,C_ECU_GW
 SG_ CCU6BE_3_4_QDK_ODRQ : 28|2@1+ (1,0) [0|2] ""  C_ECU,C_ECU_GW
 SG_ CCU6BE_3_6_QDK_ADLQ : 30|2@1+ (1,0) [0|2] ""  C_ECU,C_ECU_GW
 SG_ CCU6BE_2_0_E2E_COUNTER : 16|8@1+ (1,0) [0|255] ""  C_ECU,C_ECU_GW
 SG_ CCU6BE_0_0_CRC : 0|16@1+ (1,0) [0|65535] ""  C_ECU,C_ECU_GW

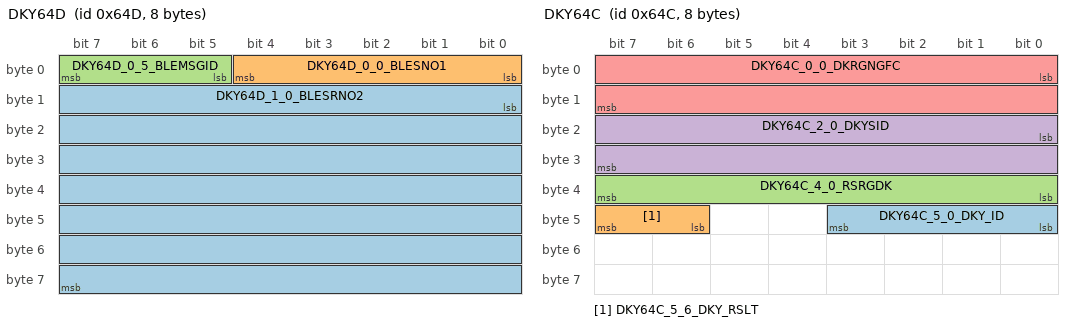
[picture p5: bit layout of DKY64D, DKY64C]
BO_ 1613 DKY64D: 8 C_ECU_GW
 SG_ DKY64D_1_0_BLESRNO2 : 8|56@1+ (1,0) [0|7.2057594037928E+16] ""  DCM
 SG_ DKY64D_0_0_BLESNO1 : 0|5@1+ (1,0) [0|31] ""  DCM
 SG_ DKY64D_0_5_BLEMSGID : 5|3@1+ (1,0) [0|5] ""  DCM

BO_ 1612 DKY64C: 8 C_ECU_GW
 SG_ DKY64C_5_0_DKY_ID : 40|4@1+ (1,0) [0|15] "" Vector__XXX
 SG_ DKY64C_5_6_DKY_RSLT : 46|2@1+ (1,0) [0|3] "" Vector__XXX
 SG_ DKY64C_4_0_RSRGDK : 32|8@1+ (1,0) [0|54] "" Vector__XXX
 SG_ DKY64C_2_0_DKYSID : 16|16@1+ (1,0) [0|65535] "" Vector__XXX
 SG_ DKY64C_0_0_DKRGNGFC : 0|16@1+ (1,0) [0|132] ""  CCU

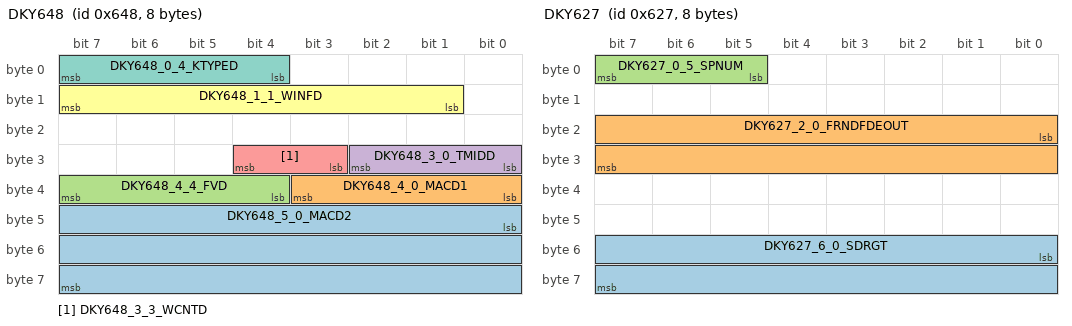
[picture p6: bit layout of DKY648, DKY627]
BO_ 1608 DKY648: 8 C_ECU_GW
 SG_ DKY648_5_0_MACD2 : 40|24@1+ (1,0) [0|16777215] "" Vector__XXX
 SG_ DKY648_4_0_MACD1 : 32|4@1+ (1,0) [0|15] "" Vector__XXX
 SG_ DKY648_4_4_FVD : 36|4@1+ (1,0) [0|15] "" Vector__XXX
 SG_ DKY648_3_0_TMIDD : 24|3@1+ (1,0) [0|7] "" Vector__XXX
 SG_ DKY648_3_3_WCNTD : 27|2@1+ (1,0) [0|3] "" Vector__XXX
 SG_ DKY648_1_1_WINFD : 9|7@1+ (1,0) [0|32] "" Vector__XXX
 SG_ DKY648_0_4_KTYPED : 4|4@1+ (1,0) [0|14] "" Vector__XXX

BO_ 1575 DKY627: 8 C_ECU_GW
 SG_ DKY627_6_0_SDRGT : 48|16@1+ (1,0) [0|65535] ""  CCU
 SG_ DKY627_2_0_FRNDFDEOUT : 16|16@1+ (1,0) [0|65535] ""  CCU
 SG_ DKY627_0_5_SPNUM : 5|3@1+ (1,0) [0|4] "" Vector__XXX

CM_ SG_ 940 BIU3AC_7_0_HEADLAMP_SMALL "ﾍｯﾄﾞﾗﾝﾌﾟ　ｽﾓｰﾙ
";
CM_ SG_ 940 BIU3AC_7_1_HEADLAMP_LO_REQ "ﾗｲﾃｨﾝｸﾞLo出力要求
";
CM_ SG_ 940 BIU3AC_7_2_HEADLAMP_HI_REQ "ﾗｲﾃｨﾝｸﾞHi出力要求
";
CM_ SG_ 940 BIU3AC_7_3_FT_FOG_RELAY_REQ "Fﾌｫｸﾞﾗﾝﾌﾟﾘﾚｰ出力要求
";
CM_ SG_ 940 BIU3AC_7_4_FOGLAMP_RR "ﾘｱﾌｫｸﾞﾗﾝﾌﾟ
";
CM_ SG_ 940 BIU3AC_7_5_DRL "DRL出力信号
";
CM_ SG_ 940 BIU3AC_7_6_WIPER_FRONT "FTﾜｲﾊﾟ(RTN)
";
CM_ SG_ 940 BIU3AC_7_7_RDEF_RELAY_REQ "ﾘｱﾃﾞﾌｫｯｶﾞ出力要求
";
CM_ SG_ 940 BIU3AC_6_0_RDEFOGSW "ﾘｱﾃﾞﾌｫｯｶﾞSW状態
";
CM_ SG_ 940 BIU3AC_6_1_CSTM_PRG "ﾊﾟﾜｰﾘｱｹﾞｰﾄ有無ﾌﾗｸﾞ
";
CM_ SG_ 940 BIU3AC_6_2_FAIL_SHIFTLOCKSOL "ｼﾌﾄﾛｯｸｿﾚﾉｲﾄﾞ異常
";
CM_ SG_ 940 BIU3AC_6_3_REQ_CANCEL_ISS "ISSｷｬﾝｾﾙ要求
";
CM_ SG_ 940 BIU3AC_6_4_REVERSE_MT "MTﾘﾊﾞｰｽSW
";
CM_ SG_ 940 BIU3AC_6_5_HANDBRAKE "ﾊﾟｰｷﾝｸﾞﾌﾞﾚｰｷSW
";
CM_ SG_ 940 BIU3AC_6_6_BRAKELAMPSW "ﾌﾞﾚｰｷﾗﾝﾌﾟSW
";
CM_ SG_ 940 BIU3AC_6_7_TOWING_SW "ﾄｰｲﾝｸﾞSW
";
CM_ SG_ 940 BIU3AC_5_0_LANE_OFF_SW "LANE OFFｽｲｯﾁ
";
CM_ SG_ 940 BIU3AC_5_2_PCR_OFF_SW "P-CR　OFFｽｲｯﾁ
";
CM_ SG_ 940 BIU3AC_5_4_DIMMER_CANCEL "ﾃﾞｨﾏｰｷｬﾝｾﾙ信号
";
CM_ SG_ 940 BIU3AC_5_5_KEYSW "ｷｰSW
";
CM_ SG_ 940 BIU3AC_5_6_IND_ND_SHIFTLOCK "N-Dｼﾌﾄﾛｯｸ用ﾌﾞﾚｰｷ押下表示有無
";
CM_ SG_ 940 BIU3AC_4_0_DOOR_DRVR "ﾄﾞｱSW　D席
";
CM_ SG_ 940 BIU3AC_4_1_DOOR_PASS "ﾄﾞｱSW　P席
";
CM_ SG_ 940 BIU3AC_4_2_DOOR_RRRH "ﾄﾞｱSW　後席右
";
CM_ SG_ 940 BIU3AC_4_3_DOOR_RRLH "ﾄﾞｱSW　後席左
";
CM_ SG_ 940 BIU3AC_4_4_DOOR_RG "ﾄﾞｱSW　Rｹﾞｰﾄ
";
CM_ SG_ 940 BIU3AC_4_5_DOOR_TR "ﾄﾞｱSW　ﾄﾗﾝｸ
";
CM_ SG_ 940 BIU3AC_4_6_HOOD_CLOSE "ﾌｰﾄﾞSW　閉側
";
CM_ SG_ 940 BIU3AC_4_7_HOOD_OPEN "ﾌｰﾄﾞＳＷ　開側
";
CM_ SG_ 940 BIU3AC_3_0_GW_STSW_RES "RESからのSTSWﾃﾞｰﾀ
";
CM_ SG_ 940 BIU3AC_3_1_GW_POWER_RES "SMTからのﾘﾓｽﾀ電源ONﾃﾞｰﾀ
";
CM_ SG_ 940 BIU3AC_3_3_ST1 "STﾌﾗｸﾞ1
";
CM_ SG_ 940 BIU3AC_3_4_ST2 "STﾌﾗｸﾞ2
";
CM_ SG_ 940 BIU3AC_3_5_ACC "ACC
";
CM_ SG_ 940 BIU3AC_3_6_IGA "IG-a
";
CM_ SG_ 940 BIU3AC_3_7_BAT_BACKUP "B/up
";
CM_ SG_ 940 BIU3AC_2_0_CSTM_AC "A/C　ＣＡＮ接続有無ﾌﾗｸﾞ
";
CM_ SG_ 940 BIU3AC_2_1_IMB_SMT "IM/SMT判別情報
";
CM_ SG_ 940 BIU3AC_2_3_CSTM_WGN_SDN "WGN/SDN判別ﾌﾗｸﾞ
";
CM_ SG_ 940 BIU3AC_2_4_VAL_SEAT_BACK_CTSM "ｼｰﾄ現在設定値
";
CM_ SG_ 940 BIU3AC_2_5_VAL_MIR_AFOLD_CTSM "ﾐﾗｰ電格設定値
";
CM_ SG_ 940 BIU3AC_2_6_VAL_MIR_RTILT_CTSM "R連動ﾐﾗｰ設定値
";
CM_ SG_ 940 BIU3AC_2_7_WIPER_REAR "RRﾜｲﾊﾟ(RTN)
";
CM_ SG_ 940 BIU3AC_1_0_MSG_COUNTER "ﾒｯｾｰｼﾞｶｳﾝﾀ
";
CM_ SG_ 940 BIU3AC_1_4_PADDLESHIFT_DOWN_SW "ﾊﾟﾄﾞﾙｼﾌﾄﾀﾞｳﾝSW
";
CM_ SG_ 940 BIU3AC_1_5_PADDLESHIFT_UP_SW "ﾊﾟﾄﾞﾙｼﾌﾄｱｯﾌﾟSW
";
CM_ SG_ 940 BIU3AC_1_6_MANUALMODE_SW "ﾏﾆｭｱﾙﾓｰﾄﾞSW
";
CM_ SG_ 940 BIU3AC_0_0_CHECK_SUM "ﾁｪｯｸｻﾑ
";
CM_ SG_ 1616 BIU650_7_0_Reserved "ワイパーサービスモードSW操作禁止フラグ
";
CM_ SG_ 1616 BIU650_7_1_Reserved "ワイパーサービスモード有無フラグ
";
CM_ SG_ 1616 BIU650_7_2_Reserved "ワイパーサービスモード状態
";
CM_ SG_ 1616 BIU650_7_3_DOOR_LINK_SW_STS "室内灯DOOR連動SW状態
";
CM_ SG_ 1616 BIU650_7_4_Reserved "ウィンドウロックSW信号
";
CM_ SG_ 1616 BIU650_6_0_Reserved "オートライト感度調整設定値
";
CM_ SG_ 1616 BIU650_6_3_RR_WIPER_STATUS "Ｒワイパ駆動状態
";
CM_ SG_ 1616 BIU650_6_5_WIPER_SENSITIVITY_CTM "ワイパ感度設定
";
CM_ SG_ 1616 BIU650_5_0_Reserved "ﾄﾞｱSW運転席信号
";
CM_ SG_ 1616 BIU650_5_1_Reserved "全ﾄﾞｱ開閉変化ｲﾍﾞﾝﾄ判定
";
CM_ SG_ 1616 BIU650_5_2_FMH_DOOR_LOCK "フォローミーホームドアロック判定
";
CM_ SG_ 1616 BIU650_5_4_LMH_DOOR_LOCK "リードミーホームドアロック判定
";
CM_ SG_ 1616 BIU650_4_0_REQ_OPE_AUTOLIGHT "オートライト点灯/消灯要求
";
CM_ SG_ 1616 BIU650_4_2_STATE_SHINSSR "ライトセンサステータス
";
CM_ SG_ 1616 BIU650_4_4_STATE_RLS_FAIL "RLS異常状態
";
CM_ SG_ 1616 BIU650_3_0_REQ_FWASHER_ITLOCK "F ウォッシャ連動要求
";
CM_ SG_ 1616 BIU650_3_1_FWIPER_RTN "F ワイパ（RTN)補正
";
CM_ SG_ 1616 BIU650_3_2_TURN_LAMP_STATE_LEFT "左ターンランプ状態
";
CM_ SG_ 1616 BIU650_3_3_TURN_LAMP_STATE_RIGHT "右ターンランプ状態
";
CM_ SG_ 1616 BIU650_3_4_Reserved "RES操作ﾗｲﾃｨﾝｸﾞ1出力要求
";
CM_ SG_ 1616 BIU650_2_0_HEADLAMP_SMALL_SW "ライティング1SW信号
";
CM_ SG_ 1616 BIU650_2_1_HEADLAMP_LO_SW "ライティング2SW信号
";
CM_ SG_ 1616 BIU650_2_2_HEADLAMP_OFF_SW "ライティングOFF SW信号
";
CM_ SG_ 1616 BIU650_2_3_HEADLAMP_Hi_SW "ディマーHi SW 信号
";
CM_ SG_ 1616 BIU650_2_4_HEAD_LAMP_PASS_SW "ディマーPass SW 信号
";
CM_ SG_ 1616 BIU650_2_5_FFOG_SW "FフォグランプSW信号
";
CM_ SG_ 1616 BIU650_2_6_RFOG_SW "RフォグランプSW信号
";
CM_ SG_ 1616 BIU650_1_0_MSG_COUNTER "メッセージカウンタ
";
CM_ SG_ 1616 BIU650_0_0_CHECK_SUM "チェックサム
";
CM_ SG_ 282 EPS11A_5_1_IND_WARN_EPS "EPS警告（テルテール用）
";
CM_ SG_ 282 EPS11A_5_4_INFO_WARN_EPS "EPS警告（INFO表示)
";
CM_ SG_ 282 EPS11A_5_7_STR_ANGLE_ADJ "EPS認識ﾊﾝﾄﾞﾙ角_補正後
";
CM_ SG_ 282 EPS11A_3_0_STR_ANGLE "EPS認識ﾊﾝﾄﾞﾙ角_補正前
";
CM_ SG_ 282 EPS11A_2_0_STA_STR_CONT_EYE "ｱｲｻｲﾄ協調舵角制御 作動状態
";
CM_ SG_ 282 EPS11A_2_1_RECOG_STR_CONT_EYE "アイサイト協調舵角制御認識フラグ
";
CM_ SG_ 282 EPS11A_2_2_INT_STR_CONT_EYE "アイサイト協調舵角制御　中断フラグ
";
CM_ SG_ 282 EPS11A_2_3_LCT_LINK_CTRL_STATE "ロケータ協調制御　可否フラグ
";
CM_ SG_ 282 EPS11A_2_4_EPS_TYPE "EPS種別
";
CM_ SG_ 282 EPS11A_2_5_OVR_JDG_FLG "オーバーライド判定フラグ
";
CM_ SG_ 282 EPS11A_1_0_MSG_COUNTER "ﾒｯｾｰｼﾞｶｳﾝﾀ
";
CM_ SG_ 282 EPS11A_1_4_MORS_ACT_FLAG "MORS作動フラグ
";
CM_ SG_ 282 EPS11A_1_7_EXIST_OVERRIDE "ｵｰﾊﾞｰﾗｲﾄﾞ有無ﾌﾗｸﾞ
";
CM_ SG_ 282 EPS11A_0_0_CHECK_SUM "ﾁｪｯｸｻﾑ
";
CM_ SG_ 811 EPB32B_7_0_AVH_TARGET_PRESS "AVH目標保持圧
";
CM_ SG_ 811 EPB32B_6_0_VEHICLE_RUN_STOP_FLG "車両走行停止判定ﾌﾗｸﾞ
";
CM_ SG_ 811 EPB32B_6_2_REQ_HILL_P_CAUTION "坂道駐車警告表示要求
";
CM_ SG_ 811 EPB32B_5_0_FLG_AVH_OILPRES_EPB "AVH制御ﾌﾗｸﾞ(液圧/EPB)
";
CM_ SG_ 811 EPB32B_5_1_FLG_AVH "AVH作動ﾌﾗｸﾞ
";
CM_ SG_ 811 EPB32B_5_2_AVH_INTENSIFY_PRES "ISS中AVH中増圧ﾌﾗｸﾞ
";
CM_ SG_ 811 EPB32B_5_3_BREAK_IND "ﾌﾞﾚｰｷ踏み指示
";
CM_ SG_ 811 EPB32B_5_5_AVH_ON_LAMP "AVH_ON灯
";
CM_ SG_ 811 EPB32B_5_6_AVH_FUNC_ON_LUMP "AVH 作動灯
";
CM_ SG_ 811 EPB32B_5_7_AVH_ACTIVE "AVH有無ﾌﾗｸﾞ
";
CM_ SG_ 811 EPB32B_4_0_BUZZER "ﾌﾞｻﾞｰ
";
CM_ SG_ 811 EPB32B_4_2_HILL_HOLD_ON_LAMP "ﾋﾙﾎｰﾙﾄﾞ機能ONﾗﾝﾌﾟ
";
CM_ SG_ 811 EPB32B_4_3_CLAMP_LAMP "EPB作動灯
";
CM_ SG_ 811 EPB32B_4_5_WARN_LAMP "EPB警告灯
";
CM_ SG_ 811 EPB32B_4_7_WARN_EPB_MET_LCD "ﾒｰﾀ内液晶用EPB警告灯
";
CM_ SG_ 811 EPB32B_3_0_STATUS_EPB "EPB作動状態
";
CM_ SG_ 811 EPB32B_3_3_DYNAMIC_PARKING "動的ﾊﾟｰｷﾝｸﾞﾌﾗｸﾞ
";
CM_ SG_ 811 EPB32B_3_4_HILL_HOLD_RUN_FLG "ﾋﾙﾎｰﾙﾄﾞ作動ﾌﾗｸﾞ
";
CM_ SG_ 811 EPB32B_3_5_INHIBIT_ISS_DELAY "ISS作動禁止要求ﾌﾗｸﾞ(判定ﾃﾞｨﾚｲ有り)
";
CM_ SG_ 811 EPB32B_3_6_INHIBIT_ISS "ISS作動禁止要求ﾌﾗｸﾞ(判定ﾃﾞｨﾚｲ無し)
";
CM_ SG_ 811 EPB32B_3_7_AVH_PERMIT_CONT_ACC "AVH-ACC協調許可フラグ
";
CM_ SG_ 811 EPB32B_2_0_ERR_INFO "EPBｴﾗｰ情報
";
CM_ SG_ 811 EPB32B_2_2_EPB_FAIL_FLG1 "EPBﾌｪｰﾙﾌﾗｸﾞ1
";
CM_ SG_ 811 EPB32B_2_3_EPB_FAIL_FLG2 "EPBﾌｪｰﾙﾌﾗｸﾞ2
";
CM_ SG_ 811 EPB32B_2_4_EPB_FAIL_FLG3 "EPBﾌｪｰﾙﾌﾗｸﾞ3
";
CM_ SG_ 811 EPB32B_1_0_MSG_COUNTER "ﾒｯｾｰｼﾞｶｳﾝﾀ
";
CM_ SG_ 811 EPB32B_1_4_WAKE_UP_FRAME "ｳｪｲｸｱｯﾌﾟﾌﾚｰﾑ識別ﾌﾗｸﾞ
";
CM_ SG_ 811 EPB32B_1_5_REQ_COMM_CONT "通信継続要求ﾌﾗｸﾞ
";
CM_ SG_ 811 EPB32B_1_6 "予約:通信継続要求ﾌﾗｸﾞ(拡張)
";
CM_ SG_ 811 EPB32B_0_0_CHECK_SUM "ﾁｪｯｸｻﾑ
";
CM_ SG_ 323 VDC143_3_0_VEHICLE_SPEED "車両速度
";
CM_ SG_ 323 VDC143_2_0_P_EXT_MAX "4輪の車輪液圧推定値の最大値
";
CM_ SG_ 323 VDC143_1_0_MSG_COUNTER "メッセージカウンタ
";
CM_ SG_ 323 VDC143_1_4_IG_ON "VDCイグニッションON/OFF情報
";
CM_ SG_ 323 VDC143_1_5_VEHICLE_SPEED_Q "車両速度ステータス信号
";
CM_ SG_ 323 VDC143_1_7_DIAG_STATUS "VDC DIAG状態フラグ
";
CM_ SG_ 323 VDC143_0_0_CHECK_SUM "チェックサム
";
CM_ SG_ 808 VDC328_7_1_IND_WARN_CBC "CBC 警告灯
";
CM_ SG_ 808 VDC328_7_2_ACTIVATE_CBC "CBC 作動灯
";
CM_ SG_ 808 VDC328_7_3_FLAG_ACT_CBC "CBC 作動フラグ
";
CM_ SG_ 808 VDC328_6_0_PROHIBIT_VDC_OFF_CCU "CCU協調VDC OFF制御禁止状態
";
CM_ SG_ 808 VDC328_6_1_PROHIBIT_AVH_CCU "CCU協調AVH制御禁止状態
";
CM_ SG_ 808 VDC328_5_0_VDC_BUZZER "VDCブザー
";
CM_ SG_ 808 VDC328_5_2_WARN_BRAKE_BOOST "ﾌﾞﾚｰｷ倍力機能ｳｫｰﾆﾝｸﾞ
";
CM_ SG_ 808 VDC328_5_4_WARN_RBS "RBS 警告灯
";
CM_ SG_ 808 VDC328_5_6_IND_HSA_ON "HSA ON灯
";
CM_ SG_ 808 VDC328_5_7_IND_TCS_OFF "TCS OFFﾗﾝﾌﾟ
";
CM_ SG_ 808 VDC328_4_0_IND_VDC_OFF "VDC OFFﾗﾝﾌﾟ
";
CM_ SG_ 808 VDC328_4_1_STATE_ACTIVATE_VDC "VDC/TCS作動状態信号
";
CM_ SG_ 808 VDC328_4_2_IND_HSA_OFF "HSA OFF灯
";
CM_ SG_ 808 VDC328_4_3_IND_HDC "HDCﾗﾝﾌﾟ
";
CM_ SG_ 808 VDC328_4_5_WARNING_BRAKE_SYS "ブレーキシステムウォーニング
";
CM_ SG_ 808 VDC328_4_7_ACTIVE_OHB "OHB作動ﾌﾗｸﾞ
";
CM_ SG_ 808 VDC328_3_0_IND_WARN_EBD "EBDｳｫｰﾆﾝｸﾞ
";
CM_ SG_ 808 VDC328_3_1_IND_WARN_ABS "ABSｳｫｰﾆﾝｸﾞ
";
CM_ SG_ 808 VDC328_3_2_IND_WARN_VDC "VDCｳｫｰﾆﾝｸﾞ
";
CM_ SG_ 808 VDC328_3_3_IND_WARN_HSA "HSA警告灯(HSAｳｫｰﾆﾝｸﾞ)
";
CM_ SG_ 808 VDC328_3_4_WARN_BRAKEFLUID_LV "ﾌﾞﾚｰｷﾌﾙｰﾄﾞﾚﾍﾞﾙ警告灯
";
CM_ SG_ 808 VDC328_3_6_IND_TCS_OFF "TCS OFFランプ
";
CM_ SG_ 808 VDC328_3_7_EXIST_EPB "EPB設定情報
";
CM_ SG_ 808 VDC328_2_0_WARN_EBD_MET_LCD "ﾒｰﾀ内液晶用EBDｳｫｰﾆﾝｸﾞ
";
CM_ SG_ 808 VDC328_2_1_WARN_ABS_MET_LCD "ﾒｰﾀ内液晶用ABSｳｫｰﾆﾝｸﾞ
";
CM_ SG_ 808 VDC328_2_2_WARN_VDC_MET_LCD "ﾒｰﾀ内液晶用VDCｳｫｰﾆﾝｸﾞ
";
CM_ SG_ 808 VDC328_2_3_WARN_HSA_MET_LCD "ﾒｰﾀ内液晶用HSA警告灯(HSAｳｫｰﾆﾝｸﾞ)
";
CM_ SG_ 808 VDC328_2_4_EXIST_VECTARING "ﾍﾞｸﾀﾘﾝｸﾞ機能設定情報
";
CM_ SG_ 808 VDC328_1_0_MSG_COUNTER "ﾒｯｾｰｼﾞｶｳﾝﾀ
";
CM_ SG_ 808 VDC328_0_0_CHECK_SUM "ﾁｪｯｸｻﾑ
";
CM_ SG_ 316 VDC13C_7_0_RCV_FAIL_ADA "ADA FAIL　受信
";
CM_ SG_ 316 VDC13C_7_1_FAIL_PCU "PCU通信異常
";
CM_ SG_ 316 VDC13C_7_2_CONT_STATE_ES_BRAKE "ACCブレーキ制御状態
";
CM_ SG_ 316 VDC13C_7_3_ASST_PRECRUSH_ACC "ACCﾌﾟﾘｸﾗﾌﾞﾚｰｷｱｼｽﾄ作動ﾌﾗｸﾞ
";
CM_ SG_ 316 VDC13C_7_4_CONT_STATE_PRECRUSH "プリクラ制御状態
";
CM_ SG_ 316 VDC13C_7_5_PERMIT_BRAKE_ACC "ACCﾌﾞﾚｰｷ制御許可ﾌﾗｸﾞ
";
CM_ SG_ 316 VDC13C_7_6_DETECT_BRAKING "ﾄﾞﾗｲﾊﾞﾌﾞﾚｰｷ検出ﾌﾗｸﾞ
";
CM_ SG_ 316 VDC13C_7_7_EMERGENCY_BRAKE "緊急ﾌﾞﾚｰｷｼｸﾞﾅﾙ
";
CM_ SG_ 316 VDC13C_6_0_SPD_PULSE_INTEGRAL "車速ﾊﾟﾙｽ信号積算値（SP1P）
";
CM_ SG_ 316 VDC13C_6_6_VDC_OFF "VDC OFFﾌﾗｸﾞ
";
CM_ SG_ 316 VDC13C_6_7_STBY_PREVIEW_VDC "ﾌﾟﾚﾋﾞｭｰVDCｽﾀﾝﾊﾞｲﾌﾗｸﾞ
";
CM_ SG_ 316 VDC13C_5_0_SPD_PULSE_RRRH "右後輪車輪速ﾊﾟﾙｽ信号(生ﾊﾟﾙｽ値)
";
CM_ SG_ 316 VDC13C_5_7_ACTIVATE_TSM "TSM作動ﾌﾗｸﾞ
";
CM_ SG_ 316 VDC13C_4_0_SPD_PULSE_RRLH "左後輪車輪速ﾊﾟﾙｽ信号(生ﾊﾟﾙｽ値)
";
CM_ SG_ 316 VDC13C_4_7_ACTIVATE_RMI "RMI作動ﾌﾗｸﾞ
";
CM_ SG_ 316 VDC13C_3_0_SPD_PULSE_FTRH "右前輪車輪速ﾊﾟﾙｽ信号(生ﾊﾟﾙｽ値)
";
CM_ SG_ 316 VDC13C_3_7_ACTIVATE_VECTARING "ﾌﾞﾚｰｷﾍﾞｸﾀﾘﾝｸﾞ制御作動ﾌﾗｸﾞ
";
CM_ SG_ 316 VDC13C_2_0_SPD_PULSE_FTLH "左前輪車輪速ﾊﾟﾙｽ信号(生ﾊﾟﾙｽ値)
";
CM_ SG_ 316 VDC13C_2_7_STATE_ACTIVATE_HSA "HSA作動状態信号
";
CM_ SG_ 316 VDC13C_1_0_MSG_COUNTER "ﾒｯｾｰｼﾞｶｳﾝﾀ
";
CM_ SG_ 316 VDC13C_1_4_ACTIVE_BRAKEHOLD "ﾌﾞﾚｰｷﾎｰﾙﾄﾞ作動ﾌﾗｸﾞ
";
CM_ SG_ 316 VDC13C_1_5_PROHIBIT_BRAKEHOLD "ﾌﾞﾚｰｷﾎｰﾙﾄﾞ禁止ﾌﾗｸﾞ
";
CM_ SG_ 316 VDC13C_1_6_BRAKELAMP_RELAY "ﾌﾞﾚｰｷﾗﾝﾌﾟﾘﾚｰ駆動信号
";
CM_ SG_ 316 VDC13C_1_7_STATUS_BRAKELAMP "ﾌﾞﾚｰｷﾗﾝﾌﾟ状態ﾌﾗｸﾞ
";
CM_ SG_ 316 VDC13C_0_0_CHECK_SUM "ﾁｪｯｸｻﾑ
";
CM_ SG_ 315 VDC13B_7_0_ACCELERATE_F_R "前後Gｾﾝｻ値
";
CM_ SG_ 315 VDC13B_6_0_ACCELERATE_L_R "横加速度
";
CM_ SG_ 315 VDC13B_4_0_ENG_TRQ_DOWN "ｴﾝｼﾞﾝﾄﾙｸ減少要求値
";
CM_ SG_ 315 VDC13B_2_0_ENG_TRQ_UP "ｴﾝｼﾞﾝﾄﾙｸｱｯﾌﾟ要求値
";
CM_ SG_ 315 VDC13B_1_0_MSG_COUNTER "ﾒｯｾｰｼﾞｶｳﾝﾀ
";
CM_ SG_ 315 VDC13B_1_4_BRAKE_TYPE "ﾌﾞﾚｰｷｼｽﾃﾑﾌﾗｸﾞ
";
CM_ SG_ 315 VDC13B_1_5_REQ_ENG_TRQ_DOWN "ｴﾝｼﾞﾝﾄﾙｸ減少要求ﾌﾗｸﾞ
";
CM_ SG_ 315 VDC13B_1_6_REQ_ENG_TRQ_UP "ｴﾝｼﾞﾝﾄﾙｸｱｯﾌﾟ要求ﾌﾗｸﾞ
";
CM_ SG_ 315 VDC13B_1_7_PROHIBIT_FUEL_CUT "ﾌｭｰｴﾙｶｯﾄ禁止ﾌﾗｸﾞ
";
CM_ SG_ 315 VDC13B_0_0_CHECK_SUM "ﾁｪｯｸｻﾑ
";
CM_ SG_ 313 VDC139_7_4_FAIL_PRESSURE_SSR "圧力ｾﾝｻ故障ﾌﾗｸﾞ
";
CM_ SG_ 313 VDC139_7_5_STATUS_EPB "EPB作動状態
";
CM_ SG_ 313 VDC139_6_0_SSR_N_PRESS "負圧ｾﾝｻ値
";
CM_ SG_ 313 VDC139_5_0_PRESSURE_BRAKE "ﾌﾞﾚｰｷ圧力
";
CM_ SG_ 313 VDC139_4_0_HDC_STATUS "HDC状態信号
";
CM_ SG_ 313 VDC139_4_2_BRAKELAMPSW "BLS信号
";
CM_ SG_ 313 VDC139_4_3_FAIL_BRAKELAMPSW "BLS故障信号
";
CM_ SG_ 313 VDC139_4_4_ACTIVATE_ABS "ABS作動ﾌﾗｸﾞ
";
CM_ SG_ 313 VDC139_4_5_ACTIVATE_TCS "TCS作動ﾌﾗｸﾞ
";
CM_ SG_ 313 VDC139_4_6_CONT_OVER_STR "VDCｵｰﾊﾞｰ制御ﾌﾗｸﾞ
";
CM_ SG_ 313 VDC139_4_7_CONT_UNDER_STR "VDCｱﾝﾀﾞｰ制御ﾌﾗｸﾞ
";
CM_ SG_ 313 VDC139_3_5_FAIL_VDC_SSR "VDCｾﾝｻﾌｪｰﾙﾌﾗｸﾞ
";
CM_ SG_ 313 VDC139_3_6_FAIL_SPD_SSR_FHI "ｽﾋﾟｰﾄﾞｾﾝｻﾌｪｰﾙﾌﾗｸﾞ（FHI）
";
CM_ SG_ 313 VDC139_3_7_FAIL_ABS_SYS "ABSｼｽﾃﾑﾌｪｰﾙﾌﾗｸﾞ
";
CM_ SG_ 313 VDC139_2_0_SPD_WHEEL_AVE "駆動輪軸平均車輪速（VSO）
";
CM_ SG_ 313 VDC139_1_0_MSG_COUNTER "ﾒｯｾｰｼﾞｶｳﾝﾀ
";
CM_ SG_ 313 VDC139_1_4_FAIL_HDC_SYS "HDCｼｽﾃﾑﾌｪｰﾙﾌﾗｸﾞ
";
CM_ SG_ 313 VDC139_1_5_VEHICLE_HIGHT "車高情報
";
CM_ SG_ 313 VDC139_1_7_REPROGRAMING "CAN診断・送信停止
";
CM_ SG_ 313 VDC139_0_0_CHECK_SUM "ﾁｪｯｸｻﾑ
";
CM_ SG_ 312 VDC138_7_0_PRESSURE_WC_FTLH "FL W/C実液圧
";
CM_ SG_ 312 VDC138_6_0_PRESSURE_WC_FTRH "FR W/C実液圧
";
CM_ SG_ 312 VDC138_4_0_YAW_RATE "ﾖｰﾚｰﾄ
";
CM_ SG_ 312 VDC138_2_0_STEER_ANGLE "舵角ｾﾝｻ
";
CM_ SG_ 312 VDC138_1_0_MSG_COUNTER "ﾒｯｾｰｼﾞｶｳﾝﾀ
";
CM_ SG_ 312 VDC138_1_4_ACTIVE_LDP "LDP作動ﾌﾗｸﾞ
";
CM_ SG_ 312 VDC138_1_5_PROHIBIT_LDP "LDP禁止ﾌﾗｸﾞ
";
CM_ SG_ 312 VDC138_1_6_VDC_SMALL_MARGIN "VDC介入余裕小ﾌﾗｸﾞ
";
CM_ SG_ 312 VDC138_1_7_DETECT_REAR_SLIP "ﾘｱｽﾘｯﾌﾟ検出ﾌﾗｸﾞ
";
CM_ SG_ 312 VDC138_0_0_CHECK_SUM "ﾁｪｯｸｻﾑ
";
CM_ SG_ 946 IPMS3B2_5_0_STATUS_IMPAIR_DRV "ドライバー異常状態判定機能ON/OFF状態
";
CM_ SG_ 946 IPMS3B2_5_1_VALID_IMPAIR_DRV "ドライバー異常状態判定参照可否
";
CM_ SG_ 946 IPMS3B2_5_2_JUDGE_IMPAIR_DRV "ドライバー異常状態判定
";
CM_ SG_ 946 IPMS3B2_2_0_STATUS_DIST_FAT_WARN "脇見・居眠り警報機能ON/OFF状態
";
CM_ SG_ 946 IPMS3B2_1_0_MSG_COUNTER "メッセージカウンタ
";
CM_ SG_ 946 IPMS3B2_1_4_FAIL_IPMS "IPMS故障通知
";
CM_ SG_ 946 IPMS3B2_0_0_CHECK_SUM "チェックサム
";
CM_ SG_ 952 CCU3B8_6_0_ACPANEL_STEER_H_LINK "ステアリングヒータAUTO連動カスタマイズ
";
CM_ SG_ 952 CCU3B8_5_6_ACPANEL_SEAT_H_LINK_P "P席 シートヒータ空調AUTO連動カスタマイズ
";
CM_ SG_ 952 CCU3B8_5_4_ACPANEL_SEAT_H_LINK_D "D席 シートヒータ空調AUTO連動カスタマイズ
";
CM_ SG_ 952 CCU3B8_4_3_ACPANEL_SEAT_V_TEMP_P "P席シートベンチレーション温度カスタマイズ
";
CM_ SG_ 952 CCU3B8_4_0_ACPANEL_SEAT_V_TEMP_D "D席シートベンチレーション温度カスタマイズ
";
CM_ SG_ 952 CCU3B8_3_7_ACN_CSTM_REQ "ACNカスタマイズ変更要求
";
CM_ SG_ 952 CCU3B8_3_3_ACPANEL_SEAT_H_TEMP_P "P席シートヒータ温度カスタマイズ
";
CM_ SG_ 952 CCU3B8_3_0_ACPANEL_SEAT_H_TEMP_D "D席シートヒータ温度カスタマイズ
";
CM_ SG_ 952 CCU3B8_2_0_ACPANEL_FAN_ONLY_SW "エアコンパネル 送風モードSW情報
";
CM_ SG_ 952 CCU3B8_2_1_ACPANEL_INNER_AIR "ｴｱｺﾝﾊﾟﾈﾙ 内外気
";
CM_ SG_ 952 CCU3B8_1_6_ACPANEL_AUTO_ECO_SW "エアコンパネル Auto 3 SW情報
";
CM_ SG_ 952 CCU3B8_1_4_STEER_HEAT_SW "ステアリングヒータSW情報
";
CM_ SG_ 952 CCU3B8_1_0_MSG_COUNTER "ﾒｯｾｰｼﾞｶｳﾝﾀ
";
CM_ SG_ 952 CCU3B8_0_0_CHECK_SUM "チェックサム
";
CM_ SG_ 1712 CCU6B0_7_0_AIL_CSTM_PRS_REQ "AIL CUSTOMプリセット要求
";
CM_ SG_ 1712 CCU6B0_7_1_AIL_RENDER_REQ "AIL 演出変更要求
";
CM_ SG_ 1712 CCU6B0_6_0_AIL_FIRST_BRIGHT_REQ "AIL 第1照明_輝度変更要求
";
CM_ SG_ 1712 CCU6B0_6_4_AIL_SECOND_BRIGHT_REQ "AIL 第2照明_輝度変更要求
";
CM_ SG_ 1712 CCU6B0_5_0_AIL_SECOND_COLOR_REQ "AIL 第2照明_カラー変更要求
";
CM_ SG_ 1712 CCU6B0_4_0_AIL_FIRST_COLOR_REQ "AIL 第1照明_カラー変更要求
";
CM_ SG_ 1712 CCU6B0_3_0_AIL_ADAS_VEH_DIS_REQ "AIL ADAS_車間距離連動変更要求
";
CM_ SG_ 1712 CCU6B0_3_1_AIL_ADAS_LANE_DEV_REQ "AIL ADAS_車線逸脱連動変更要求
";
CM_ SG_ 1712 CCU6B0_3_2_AIL_ADAS_FT_CROSS_REQ "AIL ADAS_前側方飛び出し連動変更要求
";
CM_ SG_ 1712 CCU6B0_3_3_AIL_ADAS_HANDS_FR_REQ "AIL ADAS_ハンズフリー切り替え連動変更要求
";
CM_ SG_ 1712 CCU6B0_2_0_AIL_WEL_FOL_REQ "AIL ｳｴﾙｶﾑﾌｫﾛｰﾐｰ連動変更要求
";
CM_ SG_ 1712 CCU6B0_2_1_AIL_ADAS_EXP_REQ "AIL ADAS連動変更要求
";
CM_ SG_ 1712 CCU6B0_2_2_AIL_NOTIFI_EXP_REQ "AILおしらせ連動変更要求
";
CM_ SG_ 1712 CCU6B0_2_3_AIL_AIR_CON_EXP_REQ "AIL 空調連動変更要求
";
CM_ SG_ 1712 CCU6B0_1_0_MSG_COUNTER "メッセージカウンタ
";
CM_ SG_ 1712 CCU6B0_1_4_AIL_CUSTOM_REQ "AIL カスタマイズ変更要求
";
CM_ SG_ 1712 CCU6B0_1_5_AIL_CUSTOM_RESET_REQ "AIL カスタマイズリセット変更要求
";
CM_ SG_ 1712 CCU6B0_1_6_AIL_ON_OFF_REQ "AIL ON/OFF変更要求
";
CM_ SG_ 1712 CCU6B0_0_0_CHECK_SUM "チェックサム
";
CM_ SG_ 1711 CCU6AF_1_0_MSG_COUNTER "メッセージカウンタ
";
CM_ SG_ 1711 CCU6AF_0_0_CHECK_SUM "チェックサム
";
CM_ SG_ 1710 CCU6AE_2_4_DEST_PRD_NUM "CCU仕向地品番
";
CM_ SG_ 1710 CCU6AE_2_2_VDC_SW_INFO "VDC SW情報
";
CM_ SG_ 1710 CCU6AE_2_0_ISS_SW_INFO "ISS SW情報
";
CM_ SG_ 1710 CCU6AE_1_0_MSG_COUNTER "メッセージカウンタ
";
CM_ SG_ 1710 CCU6AE_0_0_CHECK_SUM "チェックサム
";
CM_ SG_ 1709 CCU6AD_7_0_DMS_SET_REQ "DMS設定変更要求
";
CM_ SG_ 1709 CCU6AD_7_1_DP_POPUP_RES "ポップアップ操作結果
";
CM_ SG_ 1709 CCU6AD_6_3_EYE_MONI_BLUE_IND_SET "アイサイトモニター 青色インジケータ 設定値
";
CM_ SG_ 1709 CCU6AD_6_2_EYE_MONI_GRE_IND_SET "アイサイトモニター 緑色インジケータ 設定値
";
CM_ SG_ 1709 CCU6AD_6_1_EYE_MONI_YEL_IND_SET "アイサイトモニター 黄色インジケータ 設定値
";
CM_ SG_ 1709 CCU6AD_6_0_EYE_MONI_RED_IND_SET "アイサイトモニター 赤色インジケータ 設定値
";
CM_ SG_ 1709 CCU6AD_5_0_DP_OPERATION_FLAG "DriverProfile操作フラグ
";
CM_ SG_ 1709 CCU6AD_5_4_DP_OPERATION_NO "DriverProfile操作No
";
CM_ SG_ 1709 CCU6AD_4_7_DP_CCU_FAIL "DriverProfile_CCUフェールフラグ
";
CM_ SG_ 1709 CCU6AD_4_3_ALERT_BUZZ_REQ "警報音量ブザー吹鳴要求
";
CM_ SG_ 1709 CCU6AD_4_0_ALERT_VOL_LEVEL_SET "警報音量変更要求
";
CM_ SG_ 1709 CCU6AD_3_2_PREC_CAR_START_VOL "先行車発進お知らせ変更要求
";
CM_ SG_ 1709 CCU6AD_3_0_PREC_CAR_SIG_VOL_SET "先行車捕捉音変更要求
";
CM_ SG_ 1709 CCU6AD_2_3_MET_TEMP_UNIT_SET "外気温単位変更要求
";
CM_ SG_ 1709 CCU6AD_2_0_UNIT_SET "単位(BEV)変更要求
";
CM_ SG_ 1709 CCU6AD_1_0_MSG_COUNTER "メッセージカウンタ
";
CM_ SG_ 1709 CCU6AD_1_4_DP_DKY_OPERATION_NO "DKY操作No
";
CM_ SG_ 1709 CCU6AD_0_0_CHECK_SUM "チェックサム
";
CM_ SG_ 1708 CCU6AC_7_0_REAR_REMIND_SET "後席リマインダ 設定値
";
CM_ SG_ 1708 CCU6AC_6_0_SIDIRVE_SEL_INFO "SI-Drive/X選択項目変更要求
";
CM_ SG_ 1708 CCU6AC_5_6_SHIFT_DISP_SET "シフト表示変更要求
";
CM_ SG_ 1708 CCU6AC_5_4_INIT_DIRECT_SET "初期演出変更要求
";
CM_ SG_ 1708 CCU6AC_5_2_GOOD_BYE_SET "GoodBye変更要求
";
CM_ SG_ 1708 CCU6AC_5_0_WELCOME_SET "Welcome変更要求
";
CM_ SG_ 1708 CCU6AC_4_5_COMPASS_DISP_SET "コンパス表示設定
";
CM_ SG_ 1708 CCU6AC_4_3_ILL_DOWN_PUSH_SIG "イルミDOWNスイッチ押下信号
";
CM_ SG_ 1708 CCU6AC_4_2_ILL_UP_PUSH_SIG "イルミUPスイッチ押下信号
";
CM_ SG_ 1708 CCU6AC_4_0_UI_SW_STATE_SIG "UI切替スイッチ状態信号
";
CM_ SG_ 1708 CCU6AC_3_1_ILL_CONT_SW_NIGHT_SIG "イルミコンスイッチ操作信号(夜輝度用)
";
CM_ SG_ 1708 CCU6AC_2_7_BRIGHT_SW_SIG "Bright スイッチ押下信号
";
CM_ SG_ 1708 CCU6AC_2_0_ILL_CONT_SW_SIG "イルミコンスイッチ操作信号
";
CM_ SG_ 1708 CCU6AC_1_7_SET_INIT_REQ "設定初期化要求
";
CM_ SG_ 1708 CCU6AC_1_0_MSG_COUNTER "メッセージカウンタ
";
CM_ SG_ 1708 CCU6AC_0_0_CHECK_SUM "チェックサム
";
CM_ SG_ 1707 CCU6AB_7_3_REQ_RESET_CSTM_TPM "カスタマイズリセット要求(TPM)
";
CM_ SG_ 1707 CCU6AB_7_2_TPM_CSTM_CHG_REQ "TPMカスタマイズ要求変更
";
CM_ SG_ 1707 CCU6AB_7_0_CSTM_TIRE_UNIT "タイヤ空気圧表示単位設定
";
CM_ SG_ 1707 CCU6AB_6_3_REQ_RESET_CSTM_AHL "カスタマイズリセット要求(AHL)
";
CM_ SG_ 1707 CCU6AB_6_2_SRH_CSTM_CHG_REQ "SHRカスタマイズ要求変更
";
CM_ SG_ 1707 CCU6AB_6_0_SRH_CSTM_CHG_SET "SRHカスタマイズ変更設定
";
CM_ SG_ 1707 CCU6AB_5_0_SEATAWAY_DST_CSTM "シート後退量変更要求
";
CM_ SG_ 1707 CCU6AB_5_2_DRIVER_POSI_REQ "ドラポジ操作要求
";
CM_ SG_ 1707 CCU6AB_5_6_OCCUPANT_DETECT_REQ "乗員検知設定切替要求
";
CM_ SG_ 1707 CCU6AB_4_6_AFOLD_SW_MIR_SW "ミラコンSW：電格SW変更要求
";
CM_ SG_ 1707 CCU6AB_4_2_MIR_DIRECTION_MIR_SW "ミラコンSW：鏡面SW上下左右変更要求
";
CM_ SG_ 1707 CCU6AB_4_0_MIR_SELECT_LR_MIR_SW "ミラコンSW：鏡面SW左右選択変更要求
";
CM_ SG_ 1707 CCU6AB_3_0_PRG_OPENER_SW "PRG 運転席オープナSW 信号
";
CM_ SG_ 1707 CCU6AB_3_1_PRG_MEM_CHG_REQ "PRGメモリON/OFF設定変更要求
";
CM_ SG_ 1707 CCU6AB_3_2_PRG_HF_CHG_REQ "PRGハンズフリーON/OFF設定変更要求
";
CM_ SG_ 1707 CCU6AB_3_6_MIR_RTILT_R_CSTM "リバース連動機能ドアミラー右　設定変更要求
";
CM_ SG_ 1707 CCU6AB_3_7_MIR_RTILT_L_CSTM "リバース連動機能ドアミラー左　設定変更要求
";
CM_ SG_ 1707 CCU6AB_2_6_WASH_CAR_MODE_REQ "洗車モード切替要求
";
CM_ SG_ 1707 CCU6AB_2_4_SHUT_DOWN_MODE_REQ "シャットダウンモード切替要求
";
CM_ SG_ 1707 CCU6AB_2_2_PET_MODE_SWITCH_REQ "ペットモード切替要求
";
CM_ SG_ 1707 CCU6AB_2_0_POW_ON_FIX_MODE_REQ "電源ON固定モード切替要求
";
CM_ SG_ 1707 CCU6AB_1_7_CECU_CSTM_RESET_REQ "C-ECUカスタマイズリセット要求
";
CM_ SG_ 1707 CCU6AB_1_0_MSG_COUNTER "メッセージカウンタ
";
CM_ SG_ 1707 CCU6AB_0_0_CHECK_SUM "チェックサム
";
CM_ SG_ 1706 CCU6AA_5_0_WINDOW_LOCK_SET_REQ "ウィンドウロック変更要求
";
CM_ SG_ 1706 CCU6AA_5_2_DOOR_LINK_SET_REQ "室内灯ドア連動変更要求
";
CM_ SG_ 1706 CCU6AA_5_4_BULK_TURN_ON_REQ "室内灯一括点灯変更要求
";
CM_ SG_ 1706 CCU6AA_5_6_WIPER_SERV_MODE_REQ "ワイパーサービスモード変更要求
";
CM_ SG_ 1706 CCU6AA_4_0_ITMITT_SENSITIVE_REQ "ワイパー感度変更要求
";
CM_ SG_ 1706 CCU6AA_4_4_REAR_WIPER_SET_REQ "リアワイパー変更要求
";
CM_ SG_ 1706 CCU6AA_4_7_SMT_CSTM_RESET_REQ "SMTカスタマイズリセット要求
";
CM_ SG_ 1706 CCU6AA_3_0_WELCOME_RIDEON_REQ "ウェルカムランプ乗車時作動時間変更要求
";
CM_ SG_ 1706 CCU6AA_3_3_WELCOME_GETOFF_REQ "ウェルカムランプ降車時作動時間変更要求
";
CM_ SG_ 1706 CCU6AA_2_0_WIPER_HEADLAMP_REQ "ワイパー連動ヘッドランプ変更要求
";
CM_ SG_ 1706 CCU6AA_1_0_MSG_COUNTER "メッセージカウンタ
";
CM_ SG_ 1706 CCU6AA_1_4_WIUL_CUSTOM_REQ "WIUL変更要求
";
CM_ SG_ 1706 CCU6AA_1_6_WAL_CUSTOM_REQ "WAL変更要求
";
CM_ SG_ 1706 CCU6AA_0_0_CHECK_SUM "チェックサム
";
CM_ SG_ 1704 CCU6A8_7_5_TRQ_CHG_MODE_SET "トルク変動モード変更要求
";
CM_ SG_ 1704 CCU6A8_7_3_ADAPT_DEC_CHG_REQ "Adaptive変更要求
";
CM_ SG_ 1704 CCU6A8_7_0_DEC_SELECT_REQ_B "減速度セレクト変更要求_B
";
CM_ SG_ 1704 CCU6A8_6_5_DEC_SELECT_REQ_D "減速度セレクト変更要求_D
";
CM_ SG_ 1704 CCU6A8_6_2_DEC_SELECT_REQ_ALL "減速度セレクト変更要求_ALL
";
CM_ SG_ 1704 CCU6A8_6_0_DEC_SELECT_REQ_IND "減速度セレクト変更要求_Individual
";
CM_ SG_ 1704 CCU6A8_5_2_TOWING_MODE_REQ "トーイングモード変更要求
";
CM_ SG_ 1704 CCU6A8_5_0_FACTORY_MODE_STATE "工場状態モード
";
CM_ SG_ 1704 CCU6A8_4_2_TRIP_RESET_REQ "トリップリセット要求
";
CM_ SG_ 1704 CCU6A8_4_0_TRIP_SWITCH_REQ "トリップ切替要求
";
CM_ SG_ 1704 CCU6A8_3_0_DOW_SFT_POS_SET "DOW有効シフトポジション設定値
";
CM_ SG_ 1704 CCU6A8_2_6_DOW_SET "DOW設定値
";
CM_ SG_ 1704 CCU6A8_2_4_RCTA_SET "RCTA設定値
";
CM_ SG_ 1704 CCU6A8_2_2_BSD_LCA_2ND_SET "BSD/LCA2次警報音カスタマイズ設定値
";
CM_ SG_ 1704 CCU6A8_2_0_SRVD_SET "SRVD設定値
";
CM_ SG_ 1704 CCU6A8_1_6_RCR_CSTM_RESET_REQ "RCRカスタマイズリセット要求
";
CM_ SG_ 1704 CCU6A8_1_4_BEV_CSTM_RESET_REQ "BEVカスタマイズリセット要求
";
CM_ SG_ 1704 CCU6A8_1_0_MSG_COUNTER "メッセージカウンタ
";
CM_ SG_ 1704 CCU6A8_0_0_CHECK_SUM "チェックサム
";
CM_ SG_ 1149 CCU47D_3_0_AA_EST_CHG_TIME "AA 推定充電時間
";
CM_ SG_ 1149 CCU47D_2_0_E2E_COUNTER "E2Eカウンタ
";
CM_ SG_ 1149 CCU47D_0_0_E2E_CRC "CRC
";
CM_ SG_ 1148 CCU47C_7_0_AA_CRG_MAX_OUT_WAT "AA　充電時最大定格出力
";
CM_ SG_ 1148 CCU47C_3_0_AA_DEP_MIN_BAT_LEVEL "AA　出発時必要最小バッテリー量
";
CM_ SG_ 1148 CCU47C_2_0_E2E_COUNTER "E2Eカウンタ
";
CM_ SG_ 1148 CCU47C_0_0_E2E_CRC "CRC
";
CM_ SG_ 1146 CCU47A_24_0_MRM_OPERATION_INFO "MRM画面操作情報
";
CM_ SG_ 1146 CCU47A_21_2_DATA_COLLECT_LOC "データ収集・解析(位置データ)設定変更要求
";
CM_ SG_ 1146 CCU47A_21_0_DATA_COLLECT_IMAGE "データ収集・解析(画像データ)設定変更要求
";
CM_ SG_ 1146 CCU47A_20_6_ADDON_CSTM "その他項目設定変更要求
";
CM_ SG_ 1146 CCU47A_20_4_EYE_LANE_SELECT_CONT "通行区分設定-制御設定変更要求
";
CM_ SG_ 1146 CCU47A_20_2_DATA_COLLECT_CSTM "データ収集・解析設定変更要求
";
CM_ SG_ 1146 CCU47A_20_0_V2N_CSTM "V2N設定変更要求
";
CM_ SG_ 1146 CCU47A_19_6_PROPOSAL_HMI_CSTM "アイサイト使用提案設定変更要求
";
CM_ SG_ 1146 CCU47A_19_4_EYE_LANE_SELECT_CSTM "通行区分設定設定変更要求
";
CM_ SG_ 1146 CCU47A_19_2_EYE_GREEN_LIGHT_CSTM "青信号お知らせ設定変更要求
";
CM_ SG_ 1146 CCU47A_19_0_LSW_CSTM "ふらつき警報設定変更要求
";
CM_ SG_ 1146 CCU47A_16_0_ISA_IACC_ACCEPT_CONT "標識連動-制御設定変更要求
";
CM_ SG_ 1146 CCU47A_15_0_SLWF_OFFSET_OV50 "SLWFオフセット値50 km～設定変更要求
";
CM_ SG_ 1146 CCU47A_14_0_SLWF_OFFSET_U50 "SLWFオフセット値～50 km設定変更要求
";
CM_ SG_ 1146 CCU47A_13_0_ISA_IACC_OFFSET_OV50 "標識連動オフセット値50 km～設定変更要求
";
CM_ SG_ 1146 CCU47A_12_0_ISA_IACC_OFFSET_U50 "標識連動オフセット値～50 km設定変更要求
";
CM_ SG_ 1146 CCU47A_11_5_SLWF_OFS_CONT "SLWFオフセット値-制御設定変更要求
";
CM_ SG_ 1146 CCU47A_11_3_ISA_IACC_OFS_CONT "標識連動オフセット値-制御設定変更要求
";
CM_ SG_ 1146 CCU47A_11_0_ISA_IACC_ACCEPT_CSTM "標識連動設定変更要求
";
CM_ SG_ 1146 CCU47A_10_6_EYE_LOADSIGNS_SYS "標識関連機能設定変更要求
";
CM_ SG_ 1146 CCU47A_10_4_SLWF_CSTM "SLWF-制御設定変更要求
";
CM_ SG_ 1146 CCU47A_10_2_SIGN_SWITCH_SOUND "標識切替え音-制御設定変更要求
";
CM_ SG_ 1146 CCU47A_10_0_EYE_LOADSIGNS_ADD "標識表示お知らせ-制御設定変更要求
";
CM_ SG_ 1146 CCU47A_6_6_TEMP_OFF_REQ "一括一時OFF要求
";
CM_ SG_ 1146 CCU47A_6_2_CSTM_SONNER "ｿﾅｰｶｽﾀﾏｲｽﾞ変更要求(ｿﾅｰ ON/OFF)
";
CM_ SG_ 1146 CCU47A_6_0_CSTM_RAB "ｿﾅｰｶｽﾀﾏｲｽﾞ変更要求(RAB　ON/OFF)
";
CM_ SG_ 1146 CCU47A_5_7_SNR_CSTM_RESET_REQ "SNRカスタマイズリセット要求
";
CM_ SG_ 1146 CCU47A_5_6_ADAS_CSTM_RESET_REQ "ADASカスタマイズリセット要求
";
CM_ SG_ 1146 CCU47A_5_2_PED_RAB_TIMING "歩行者RABタイミング変更要求
";
CM_ SG_ 1146 CCU47A_5_0_PED_RAB_ON_OFF "歩行者RAB ON/OFF変更要求
";
CM_ SG_ 1146 CCU47A_3_0_EYE_CSTM_CHG_REQ_47A "EyeSightカスタマイズ変更要求_47A
";
CM_ SG_ 1146 CCU47A_2_0_E2E_COUNTER "E2Eカウンタ
";
CM_ SG_ 1146 CCU47A_0_0_E2E_CRC "CRC
";
CM_ SG_ 1145 CCU479_29_4_ACC_TGT_OPT_HIGHWAY "ACC-ターゲット(高速道路)設定変更要求
";
CM_ SG_ 1145 CCU479_29_2_ACC_TGT_OPT_SLOWDOWN "ACC-ターゲット(減速制御)設定変更要求
";
CM_ SG_ 1145 CCU479_29_0_ACC_TGT_OPT_STOP "ACC-ターゲット(停止制御)設定変更要求
";
CM_ SG_ 1145 CCU479_28_2_EYE_ACC_FUNC_CONT "ACC加速特性-制御設定変更要求
";
CM_ SG_ 1145 CCU479_28_0_ACC_TARGET_OPT_CSTM "ACC-ターゲット-制御設定変更要求
";
CM_ SG_ 1145 CCU479_27_5_EYE_ACC_SYS_CSTM "クルーズコントロールシステム設定変更要求
";
CM_ SG_ 1145 CCU479_27_3_ACC_OVERTAKE_CSTM "追い越し抑制-制御設定変更要求
";
CM_ SG_ 1145 CCU479_27_0_EYE_ACC_CONT_CSTM "ACC加速特性設定変更要求
";
CM_ SG_ 1145 CCU479_24_4_EYE_LKS_OPT_OFFSET "LKS-付加機能(走行位置オフセット)設定変更要求
";
CM_ SG_ 1145 CCU479_24_2_EYE_LKS_OPT_NAVI "LKS-付加機能(ナビルート連携)設定変更要求
";
CM_ SG_ 1145 CCU479_24_0_EYE_LKS_OPT_AUTOPASS "LKS-付加機能(自動追い越し)設定変更要求
";
CM_ SG_ 1145 CCU479_23_2_EYE_LKS_OPT_CONT "LKS-付加機能-制御
";
CM_ SG_ 1145 CCU479_23_0_EYE_ACTIVE_LKS_CSTM "車線中央維持設定変更要求
";
CM_ SG_ 1145 CCU479_21_4_EYE_ELK_CTRL_CSTM "ELK-アシストタイプ(制御)設定変更要求
";
CM_ SG_ 1145 CCU479_21_2_EYE_ELK_VIB_CSTM "ELK-アシストタイプ(振動)設定変更要求
";
CM_ SG_ 1145 CCU479_21_0_EYE_ELK_SOUND_CSTM "ELK-アシストタイプ(音)設定変更要求
";
CM_ SG_ 1145 CCU479_20_6_ELK_ASSISTTYPE_CONT "ELK-アシストタイプ-制御設定変更要求
";
CM_ SG_ 1145 CCU479_20_4_EYE_LDW_TIMING_CONT "LD-警報タイミング-制御設定変更要求
";
CM_ SG_ 1145 CCU479_20_2_LDW_OFF_EXE "LDW音OFF設定変更要求
";
CM_ SG_ 1145 CCU479_20_0_EYE_ELK_CSTM "ELK設定変更要求
";
CM_ SG_ 1145 CCU479_19_6_LDP_TARGET_SIDE_VHCL "LD-制御対象(側方車両)設定変更要求
";
CM_ SG_ 1145 CCU479_19_4_LDP_TARGET_SIDE_OBJ "LD-制御対象(側方構造物)設定変更要求
";
CM_ SG_ 1145 CCU479_19_2_LDP_TARGET_DASHLINE "LD-制御対象(破線)設定変更要求
";
CM_ SG_ 1145 CCU479_19_0_LDP_TARGET_SOLIDLINE "LD-制御対象(実線)設定変更要求
";
CM_ SG_ 1145 CCU479_18_6_LDP_TARGET_CONT "LD-制御対象-制御設定変更要求
";
CM_ SG_ 1145 CCU479_18_4_LANE_DEP_LDP_CSTM "LD-アシストタイプ(制御)設定変更要求
";
CM_ SG_ 1145 CCU479_18_2_LANE_DEP_LDW_VI_CSTM "LD-アシストタイプ(振動)設定変更要求
";
CM_ SG_ 1145 CCU479_18_0_LANE_DEP_LDW_SO_CSTM "LD-アシストタイプ(音)設定変更要求
";
CM_ SG_ 1145 CCU479_17_5_LANE_DEP_LDW_CONT "LD-アシストタイプ-制御設定変更要求
";
CM_ SG_ 1145 CCU479_17_2_EYE_LDW_TIMING_CSTM "LD-警報タイミング設定変更要求
";
CM_ SG_ 1145 CCU479_17_0_LANE_DEPARTURE_CSTM "車線逸脱抑制機能設定変更要求
";
CM_ SG_ 1145 CCU479_16_2_EYE_MIS_AT_BACK_CONT "リミット速度-制御設定変更要求
";
CM_ SG_ 1145 CCU479_16_0_EYE_SAFTY_MODE_SENS "踏み間違い加速抑制-感度-制御設定変更要求
";
CM_ SG_ 1145 CCU479_15_6_FCTI_NOTICE_CONT "前側方警戒アシスト通知方法-制御設定変更要求
";
CM_ SG_ 1145 CCU479_15_4_FCW_TYPE_CONT "FCW警報方法-制御設定変更要求
";
CM_ SG_ 1145 CCU479_15_2_FCW_TIMING_CONT "FCW警報タイミング-制御設定変更要求
";
CM_ SG_ 1145 CCU479_15_0_BRAKE_TIMING_CONT "ブレーキタイミング-制御設定変更要求
";
CM_ SG_ 1145 CCU479_14_5_FCW_OFF_EXE "FCW音OFF設定変更要求
";
CM_ SG_ 1145 CCU479_14_2_EYE_MIS_AT_BACK_LV "リミット速度設定変更要求
";
CM_ SG_ 1145 CCU479_14_0_EYE_MIS_AT_BACK_CSTM "後退速リミッター設定変更要求
";
CM_ SG_ 1145 CCU479_13_2_FCTI_PULSE_CSTM "前側方警戒アシスト通知方法(振動)設定変更要求
";
CM_ SG_ 1145 CCU479_13_0_FCTI_SOUND_CSTM "前側方警戒アシスト通知方法(音)設定変更要求
";
CM_ SG_ 1145 CCU479_12_4_EYE_SAFTY_MODE_LV "踏み間違い加速抑制-感度設定変更要求
";
CM_ SG_ 1145 CCU479_12_2_EYE_SAFTY_MODE_CSTM "踏み間違い加速抑制設定変更要求
";
CM_ SG_ 1145 CCU479_12_0_FCTI_CONT_CSTM "前側方警戒アシスト設定変更要求
";
CM_ SG_ 1145 CCU479_11_2_FCW_TYPE_PULSE_CSTM "FCW警報方法(振動)設定変更要求
";
CM_ SG_ 1145 CCU479_11_0_FCW_TYPE_SOUND_CSTM "FCW警報方法(音)設定変更要求
";
CM_ SG_ 1145 CCU479_10_5_FCW_TIMING_CSTM "FCW警報タイミング設定変更要求
";
CM_ SG_ 1145 CCU479_10_2_BRAKE_TIMING_CSTM "ブレーキタイミング設定変更要求
";
CM_ SG_ 1145 CCU479_10_0_EYE_P_CR_CSTM "プリクラッシュブレーキ設定変更要求
";
CM_ SG_ 1145 CCU479_6_4_SUPPRESS_SPD_TGT_SLO "抑制/減速制御-ターゲット(下り坂)設定変更要求
";
CM_ SG_ 1145 CCU479_6_2_SUPPRESS_SPD_TGT_SUR "抑制/減速制御-ターゲット(周辺環境)設定変更要求
";
CM_ SG_ 1145 CCU479_6_0_SUPPRESS_SPD_TGT_VEH "抑制/減速制御-ターゲット(車両)設定変更要求
";
CM_ SG_ 1145 CCU479_5_5_ACTIVE_AVOIDANCE_LV "先読み操舵減速アシスト設定変更要求
";
CM_ SG_ 1145 CCU479_5_3_ACTIVE_AVOIDANCE "先読み操舵減速アシスト-制御設定変更要求
";
CM_ SG_ 1145 CCU479_5_0_SUPPRESS_SPEED_LEVEL "抑制/減速制御-感度設定変更要求
";
CM_ SG_ 1145 CCU479_4_4_SUPPRESS_SPD_TGT_CONT "抑制/減速制御-ターゲット-制御設定変更要求
";
CM_ SG_ 1145 CCU479_4_2_SUPPRESS_SPEED_CSTM "抑制/減速制御-感度-制御設定変更要求
";
CM_ SG_ 1145 CCU479_4_0_PDA_CSTM "安全重視モード設定変更要求
";
CM_ SG_ 1145 CCU479_3_1_FAIL_CCU_TO_EYE "CCU通信異常通知
";
CM_ SG_ 1145 CCU479_3_0_CCU_VALID "CCUValidフラグ
";
CM_ SG_ 1145 CCU479_2_0_E2E_COUNTER "E2Eカウンタ
";
CM_ SG_ 1145 CCU479_0_0_E2E_CRC "CRC
";
CM_ SG_ 1144 CCU478_25_0_LAT_CHG_WEEK_DAYS "直近タイマー充電曜日
";
CM_ SG_ 1144 CCU478_24_3_Reserved "RESERVED
";
CM_ SG_ 1144 CCU478_23_0_LAT_CHG_END_TIME "直近タイマー充電終了時刻
";
CM_ SG_ 1144 CCU478_22_5_Reserved "RESERVED
";
CM_ SG_ 1144 CCU478_21_2_LAT_CHG_START_TIME "直近タイマー充電開始時刻
";
CM_ SG_ 1144 CCU478_21_0_LAT_CHG_SET_TYPE "直近タイマー充電設定タイプ
";
CM_ SG_ 1144 CCU478_20_6_Reserved "RESERVED
";
CM_ SG_ 1144 CCU478_20_2_TIRE_SIZE "タイヤサイズ
";
CM_ SG_ 1144 CCU478_20_0_TIRE_TYPE "タイヤ種別
";
CM_ SG_ 1144 CCU478_19_4_Reserved "RESERVED
";
CM_ SG_ 1144 CCU478_19_2_SW_PFO_MOD_CHG "パフォーマンスモード要求
";
CM_ SG_ 1144 CCU478_19_0_DEP_TIM_CHG_FLG "出発時刻プレコン設定変更フラグ
";
CM_ SG_ 1144 CCU478_18_0_DEP_TIM4_WEEK_DAYS "出発時刻プレコンID4曜日
";
CM_ SG_ 1144 CCU478_17_3_Reserved "RESERVED
";
CM_ SG_ 1144 CCU478_16_0_DEP_TIM4_START_TIME "出発時刻プレコンID4開始時刻
";
CM_ SG_ 1144 CCU478_15_7_DEP_TIM4_PER_FLG "出発時刻プレコンID4パフォーマンスモードフラグ
";
CM_ SG_ 1144 CCU478_15_5_DEP_TIM4_SW_STS "出発時刻プレコンID4オン・オフ状態
";
CM_ SG_ 1144 CCU478_15_0_TIM4_DISP_ID "出発時刻プレコンID4の表示順番ID
";
CM_ SG_ 1144 CCU478_14_0_DEP_TIM3_WEEK_DAYS "出発時刻プレコンID3曜日
";
CM_ SG_ 1144 CCU478_13_3_Reserved "RESERVED
";
CM_ SG_ 1144 CCU478_12_0_DEP_TIM3_START_TIME "出発時刻プレコンID3開始時刻
";
CM_ SG_ 1144 CCU478_11_7_DEP_TIM3_PER_FLG "出発時刻プレコンID3パフォーマンスモードフラグ
";
CM_ SG_ 1144 CCU478_11_5_DEP_TIM3_SW_STS "出発時刻プレコンID3オン・オフ状態
";
CM_ SG_ 1144 CCU478_11_0_TIM3_DISP_ID "出発時刻プレコンID3の表示順番ID
";
CM_ SG_ 1144 CCU478_10_0_DEP_TIM2_WEEK_DAYS "出発時刻プレコンID2曜日
";
CM_ SG_ 1144 CCU478_9_3_Reserved "RESERVED
";
CM_ SG_ 1144 CCU478_8_0_DEP_TIM2_START_TIME "出発時刻プレコンID2開始時刻
";
CM_ SG_ 1144 CCU478_7_7_DEP_TIM2_PER_FLG "出発時刻プレコンID2パフォーマンスモードフラグ
";
CM_ SG_ 1144 CCU478_7_5_DEP_TIM2_SW_STS "出発時刻プレコンID2オン・オフ状態
";
CM_ SG_ 1144 CCU478_7_0_TIM2_DISP_ID "出発時刻プレコンID2の表示順番ID
";
CM_ SG_ 1144 CCU478_6_0_DEP_TIM1_WEEK_DAYS "出発時刻プレコンID1曜日
";
CM_ SG_ 1144 CCU478_5_3_Reserved "RESERVED
";
CM_ SG_ 1144 CCU478_4_0_DEP_TIM1_START_TIME "出発時刻プレコンID1開始時刻
";
CM_ SG_ 1144 CCU478_3_7_DEP_TIM1_PER_FLG "出発時刻プレコンID1パフォーマンスモードフラグ
";
CM_ SG_ 1144 CCU478_3_5_DEP_TIM1_SW_STS "出発時刻プレコンID1オン・オフ状態
";
CM_ SG_ 1144 CCU478_3_0_TIM1_DISP_ID "出発時刻プレコンID1の表示順番ID
";
CM_ SG_ 1144 CCU478_2_0_E2E_COUNTER "E2Eカウンタ
";
CM_ SG_ 1144 CCU478_0_0_E2E_CRC "CRC
";
CM_ SG_ 1143 CCU477_28_4_Reserved "RESERVED
";
CM_ SG_ 1143 CCU477_28_2_TIM_CHG_CHG_FLG "タイマー充電設定変更フラグ
";
CM_ SG_ 1143 CCU477_28_0_TIM_CHG_ICON_DISP "タイマー充電アイコン表示要求
";
CM_ SG_ 1143 CCU477_27_4_TIM_CHG_STATUS "タイマー充電ステータス
";
CM_ SG_ 1143 CCU477_27_1_DEP_TIM_PRE_CON_FLAG "プレコンディションニングフラグ
";
CM_ SG_ 1143 CCU477_27_0_TIM_CHG_PERM_FLAG "タイマー充電許可禁止
";
CM_ SG_ 1143 CCU477_26_0_TIM4_CHG_WEEK_DAYS "タイマー充電ID4曜日
";
CM_ SG_ 1143 CCU477_25_3_Reserved "RESERVED
";
CM_ SG_ 1143 CCU477_24_0_TIM4_CHG_END_TIME "タイマー充電ID4終了時刻
";
CM_ SG_ 1143 CCU477_23_5_Reserved "RESERVED
";
CM_ SG_ 1143 CCU477_22_2_TIM4_CHG_START_TIME "タイマー充電ID4開始時刻
";
CM_ SG_ 1143 CCU477_22_0_TIM4_CHG_SET_TYPE "タイマー充電ID4タイプ
";
CM_ SG_ 1143 CCU477_21_7_Reserved "RESERVED
";
CM_ SG_ 1143 CCU477_21_5_TIM4_CHG_SW_STS "タイマー充電ID4オン・オフ状態
";
CM_ SG_ 1143 CCU477_21_0_TIM4_DISP_ID "タイマー充電ID4の表示順番ID
";
CM_ SG_ 1143 CCU477_20_0_TIM3_CHG_WEEK_DAYS "タイマー充電ID3曜日
";
CM_ SG_ 1143 CCU477_19_3_Reserved "RESERVED
";
CM_ SG_ 1143 CCU477_18_0_TIM3_CHG_END_TIME "タイマー充電ID3終了時刻
";
CM_ SG_ 1143 CCU477_17_5_Reserved "RESERVED
";
CM_ SG_ 1143 CCU477_16_2_TIM3_CHG_START_TIME "タイマー充電ID3開始時刻
";
CM_ SG_ 1143 CCU477_16_0_TIM3_CHG_SET_TYPE "タイマー充電ID3タイプ
";
CM_ SG_ 1143 CCU477_15_7_Reserved "RESERVED
";
CM_ SG_ 1143 CCU477_15_5_TIM3_CHG_SW_STS "タイマー充電ID3オン・オフ状態
";
CM_ SG_ 1143 CCU477_15_0_TIM3_DISP_ID "タイマー充電ID3の表示順番ID
";
CM_ SG_ 1143 CCU477_14_0_TIM2_CHG_WEEK_DAYS "タイマー充電ID2曜日
";
CM_ SG_ 1143 CCU477_13_3_Reserved "RESERVED
";
CM_ SG_ 1143 CCU477_12_0_TIM2_CHG_END_TIME "タイマー充電ID2終了時刻
";
CM_ SG_ 1143 CCU477_11_5_Reserved "RESERVED
";
CM_ SG_ 1143 CCU477_10_2_TIM2_CHG_START_TIME "タイマー充電ID2開始時刻
";
CM_ SG_ 1143 CCU477_10_0_TIM2_CHG_SET_TYPE "タイマー充電ID2タイプ
";
CM_ SG_ 1143 CCU477_9_7_Reserved "RESERVED
";
CM_ SG_ 1143 CCU477_9_5_TIM2_CHG_SW_STS "タイマー充電ID2オン・オフ状態
";
CM_ SG_ 1143 CCU477_9_0_TIM2_DISP_ID "タイマー充電ID2の表示順番ID
";
CM_ SG_ 1143 CCU477_8_0_TIM1_CHG_WEEK_DAYS "タイマー充電ID1曜日
";
CM_ SG_ 1143 CCU477_7_3_Reserved "RESERVED
";
CM_ SG_ 1143 CCU477_6_0_TIM1_CHG_END_TIME "タイマー充電ID1終了時刻
";
CM_ SG_ 1143 CCU477_5_5_Reserved "RESERVED
";
CM_ SG_ 1143 CCU477_4_2_TIM1_CHG_START_TIME "タイマー充電ID1開始時刻
";
CM_ SG_ 1143 CCU477_4_0_TIM1_CHG_SET_TYPE "タイマー充電ID1タイプ
";
CM_ SG_ 1143 CCU477_3_7_Reserved "RESERVED
";
CM_ SG_ 1143 CCU477_3_5_TIM1_CHG_SW_STS "タイマー充電ID1オン・オフ状態
";
CM_ SG_ 1143 CCU477_3_0_TIM1_DISP_ID "タイマー充電ID1の表示順番ID
";
CM_ SG_ 1143 CCU477_2_0_E2E_COUNTER "E2Eカウンタ
";
CM_ SG_ 1143 CCU477_0_0_E2E_CRC "CRC
";
CM_ SG_ 1142 CCU476_17_2_SW_STOP_CHG "充電停止要求
";
CM_ SG_ 1142 CCU476_17_1_SW_NORMAL_MOD_CHG "ノーマルモード要求
";
CM_ SG_ 1142 CCU476_17_0_SW_PWR_MOD_CHG "パワーモード要求
";
CM_ SG_ 1142 CCU476_16_4_AC_CUR_MAX_LIM_CHG "AC充電電流上限設定値(IVI)
";
CM_ SG_ 1142 CCU476_16_0_DC_PWR_MAX_LIM_CHG "DC充電電力上限設定値(IVI)
";
CM_ SG_ 1142 CCU476_15_0_SOC_MAX_LIM_CHG "充電量上限設定要求値
";
CM_ SG_ 1142 CCU476_14_0_HIS_ID_PNC "履歴ID
";
CM_ SG_ 1142 CCU476_13_5_SW_CAUTION_PNC "PnCcaution_push
";
CM_ SG_ 1142 CCU476_13_4_SW_NEW_PNC "New_push
";
CM_ SG_ 1142 CCU476_13_3_START_CTR_PNC "PnC_契約開始
";
CM_ SG_ 1142 CCU476_13_1_STS_PNC "PnC_Status
";
CM_ SG_ 1142 CCU476_13_0_DESC_PNC "PnC説明
";
CM_ SG_ 1142 CCU476_11_1_STOP_TIM_TIM_CHG "充電終了設定時刻
";
CM_ SG_ 1142 CCU476_10_0_START_TIM_TIM_CHG "充電開始設定時刻
";
CM_ SG_ 1142 CCU476_9_0_WKD_SET_TIM_CHG "充電設定曜日
";
CM_ SG_ 1142 CCU476_8_0_LOGIN_REQ_TIM_CHG "タイマー設定登録要求
";
CM_ SG_ 1142 CCU476_7_0_WKD_SEL_TIM_CHG "曜日選択
";
CM_ SG_ 1142 CCU476_5_1_STOP_TIM_CH_TIM_CHG "終了設定時刻変更
";
CM_ SG_ 1142 CCU476_4_0_START_TIM_CH_TIM_CHG "開始設定時刻変更
";
CM_ SG_ 1142 CCU476_3_0_PNC_SW_REQ_CCU "PnCサービスOnOff切替要求_CCU
";
CM_ SG_ 1142 CCU476_2_7_SW_TIM_CHG "オン/オフ状態
";
CM_ SG_ 1142 CCU476_2_0_E2E_COUNTER "E2Eカウンタ
";
CM_ SG_ 1142 CCU476_0_0_E2E_CRC "CRC
";
CM_ SG_ 1141 CCU475_4_0_SOC_MIN_PWR_SPL "給電量下限設定要求値(DC)
";
CM_ SG_ 1141 CCU475_3_4_Reserved "RESERVED
";
CM_ SG_ 1141 CCU475_3_2_SW_PWR_SPL_DC "給電ON/OFF要求(DC)
";
CM_ SG_ 1141 CCU475_3_0_SW_PWR_SPL_AC "給電ON/OFF要求(AC)
";
CM_ SG_ 1141 CCU475_2_0_E2E_COUNTER "E2Eカウンタ
";
CM_ SG_ 1141 CCU475_0_0_E2E_CRC "CRC
";
CM_ SG_ 1112 CCU458_7_0_BYTE5 "開発用変数5
";
CM_ SG_ 1112 CCU458_6_0_BYTE4 "開発用変数4
";
CM_ SG_ 1112 CCU458_5_0_BYTE3 "開発用変数3
";
CM_ SG_ 1112 CCU458_4_0_BYTE2 "開発用変数2
";
CM_ SG_ 1112 CCU458_3_0_BYTE1 "開発用変数1
";
CM_ SG_ 1112 CCU458_2_0_E2E_COUNTER "E2Eカウンタ
";
CM_ SG_ 1112 CCU458_0_0_E2E_CRC "CRC
";
CM_ SG_ 1105 CCU451_31_0_BYTE26 "開発用変数26
";
CM_ SG_ 1105 CCU451_30_0_BYTE25 "開発用変数25
";
CM_ SG_ 1105 CCU451_29_0_BYTE24 "開発用変数24
";
CM_ SG_ 1105 CCU451_28_0_BYTE23 "開発用変数23
";
CM_ SG_ 1105 CCU451_27_0_BYTE22 "開発用変数22
";
CM_ SG_ 1105 CCU451_26_0_BYTE21 "開発用変数21
";
CM_ SG_ 1105 CCU451_25_0_BYTE20 "開発用変数20
";
CM_ SG_ 1105 CCU451_24_0_BYTE19 "開発用変数19
";
CM_ SG_ 1105 CCU451_23_0_BYTE18 "開発用変数18
";
CM_ SG_ 1105 CCU451_22_0_BYTE17 "開発用変数17
";
CM_ SG_ 1105 CCU451_21_0_BYTE16 "開発用変数16
";
CM_ SG_ 1105 CCU451_20_0_BYTE15 "開発用変数15
";
CM_ SG_ 1105 CCU451_19_0_BYTE14 "開発用変数14
";
CM_ SG_ 1105 CCU451_18_0_BYTE13 "開発用変数13
";
CM_ SG_ 1105 CCU451_17_0_BYTE12 "開発用変数12
";
CM_ SG_ 1105 CCU451_16_0_BYTE11 "開発用変数11
";
CM_ SG_ 1105 CCU451_15_0_BYTE10 "開発用変数10
";
CM_ SG_ 1105 CCU451_14_0_BYTE9 "開発用変数9
";
CM_ SG_ 1105 CCU451_13_0_BYTE8 "開発用変数8
";
CM_ SG_ 1105 CCU451_12_0_BYTE7 "開発用変数7
";
CM_ SG_ 1105 CCU451_11_0_BYTE6 "開発用変数6
";
CM_ SG_ 1105 CCU451_10_0_BYTE5 "開発用変数5
";
CM_ SG_ 1105 CCU451_9_0_BYTE4 "開発用変数4
";
CM_ SG_ 1105 CCU451_8_0_CHG_BTN_FLG_CCU "充電ボタン表示フラグ_CCU
";
CM_ SG_ 1105 CCU451_8_3_CHG_CNG_FLG_CCU "充電ボタン変化フラグ_CCU
";
CM_ SG_ 1105 CCU451_8_4_Reserved "RESERVED
";
CM_ SG_ 1105 CCU451_7_3_Reserved "RESERVED
";
CM_ SG_ 1105 CCU451_6_0_CHG_COMTI "充電完了時間_CCU
";
CM_ SG_ 1105 CCU451_5_0_SW_RIGHT_NOW_PRE_CON "即時プレコンSW情報
";
CM_ SG_ 1105 CCU451_5_2_Reserved "RESERVED
";
CM_ SG_ 1105 CCU451_4_1_CHG_HILMT_REQ "充電量上限設定要求値_CCU
";
CM_ SG_ 1105 CCU451_4_0_CHG_STP_REQ "充電停止要求_CCU
";
CM_ SG_ 1105 CCU451_3_4_DCCHG_PWRUPLMT "DC充電電力上限設定値_CCU
";
CM_ SG_ 1105 CCU451_3_0_ACCHG_CORUPLMT "AC充電電流上限設定値_CCU
";
CM_ SG_ 1105 CCU451_2_0_E2E_COUNTER "E2Eカウンタ
";
CM_ SG_ 1105 CCU451_0_0_E2E_CRC "CRC
";
CM_ SG_ 1665 CECU681_6_7_DP_CHANGE_SET_REQ "ドライバプロファイル設定変更要求フラグ
";
CM_ SG_ 1665 CECU681_6_4_SMT_LINK "スマート紐づけ
";
CM_ SG_ 1665 CECU681_6_3_IPMS_LINK "IPMS紐づけ
";
CM_ SG_ 1665 CECU681_5_6_DP_DKYMEM_LIST_NO15 "DriverProfileデジキー登録リストNo15
";
CM_ SG_ 1665 CECU681_5_5_DP_DKYMEM_LIST_NO14 "DriverProfileデジキー登録リストNo14
";
CM_ SG_ 1665 CECU681_5_4_DP_DKYMEM_LIST_NO13 "DriverProfileデジキー登録リストNo13
";
CM_ SG_ 1665 CECU681_5_3_DP_DKYMEM_LIST_NO12 "DriverProfileデジキー登録リストNo12
";
CM_ SG_ 1665 CECU681_5_2_DP_DKYMEM_LIST_NO11 "DriverProfileデジキー登録リストNo11
";
CM_ SG_ 1665 CECU681_5_1_DP_DKYMEM_LIST_NO10 "DriverProfileデジキー登録リストNo10
";
CM_ SG_ 1665 CECU681_5_0_DP_DKYMEM_LIST_NO9 "DriverProfileデジキー登録リストNo9
";
CM_ SG_ 1665 CECU681_4_7_DP_DKYMEM_LIST_NO8 "DriverProfileデジキー登録リストNo8
";
CM_ SG_ 1665 CECU681_4_6_DP_DKYMEM_LIST_NO7 "DriverProfileデジキー登録リストNo7
";
CM_ SG_ 1665 CECU681_4_5_DP_DKYMEM_LIST_NO6 "DriverProfileデジキー登録リストNo6
";
CM_ SG_ 1665 CECU681_4_4_DP_DKYMEM_LIST_NO5 "DriverProfileデジキー登録リストNo5
";
CM_ SG_ 1665 CECU681_4_3_DP_DKYMEM_LIST_NO4 "DriverProfileデジキー登録リストNo4
";
CM_ SG_ 1665 CECU681_4_2_DP_DKYMEM_LIST_NO3 "DriverProfileデジキー登録リストNo3
";
CM_ SG_ 1665 CECU681_4_1_DP_DKYMEM_LIST_NO2 "DriverProfileデジキー登録リストNo2
";
CM_ SG_ 1665 CECU681_4_0_DP_DKYMEM_LIST_NO1 "DriverProfileデジキー登録リストNo1
";
CM_ SG_ 1665 CECU681_3_5_RECOG_FACTOR "識別要因信号
";
CM_ SG_ 1665 CECU681_3_4_RECOG_USER_VALIDFRAG "識別ユーザ有効フラグ
";
CM_ SG_ 1665 CECU681_3_0_RESULT_NOTICE_REQ "処理結果表示要求
";
CM_ SG_ 1665 CECU681_2_4_RECOG_USER_NO "識別ユーザNo.
";
CM_ SG_ 1665 CECU681_2_0_POPUP_NOTICE_NO "ポップアップ表示ユーザNo.
";
CM_ SG_ 1665 CECU681_1_7_DP_FAILE_FRAG "DPフェールフラグ
";
CM_ SG_ 1665 CECU681_1_5_DP_PROCESS_RESULT "DP処理結果
";
CM_ SG_ 1665 CECU681_1_4_POPUP_NOTICE_REQ "ポップアップ表示要求
";
CM_ SG_ 1665 CECU681_1_0_MSG_COUNTER "メッセージカウンタ
";
CM_ SG_ 1665 CECU681_0_0_CHECK_SUM "ﾁｪｯｸｻﾑ
";
CM_ SG_ 1664 CECU680_7_0_RSLT_DEV "利用者認証結果_CID制御
";
CM_ SG_ 1664 CECU680_6_4_SDK_PRG "デジタルキー登録進捗状態
";
CM_ SG_ 1664 CECU680_6_0_RSLT_AUTHORITY "権限通知
";
CM_ SG_ 1664 CECU680_5_6_RDK_SWAPGRL "オーナ用デジタルキー機種交換受付結果
";
CM_ SG_ 1664 CECU680_5_4_RDK_ORRL "オーナー用デジタルキー登録事前準備結果
";
CM_ SG_ 1664 CECU680_4_6_RDK_ADRL "デジタルキー全キー消去結果
";
CM_ SG_ 1664 CECU680_4_4_RDK_ODRL "オーナー用デジタルキー消去結果
";
CM_ SG_ 1664 CECU680_4_2_RDK_FDRL "フレンド用デジタルキー消去結果
";
CM_ SG_ 1664 CECU680_4_0_RDK_OGRL "オーナーデバイス登録処理ステータス確認結果
";
CM_ SG_ 1664 CECU680_3_7_ADK_ADLA "デジタルキー全キー消去受付可否判定結果
";
CM_ SG_ 1664 CECU680_3_6_ADK_OWDA "オーナー用デジタルキー消去要求受付可否判定結果
";
CM_ SG_ 1664 CECU680_3_4_ADK_REGA "オーナー用デジタルキー登録事前準備要求受付可否判定結果
";
CM_ SG_ 1664 CECU680_3_3_ADK_STCA "オーナーデバイス登録処理ステータス確認要求受付可否判定結果
";
CM_ SG_ 1664 CECU680_3_2_ADK_SWAPSTACA "オーナーデバイス機種交換処理ステータス確認要求受付可否判定結果
";
CM_ SG_ 1664 CECU680_3_1_ADK_FWDA "フレンド用デジタルキー消去要求受付可否判定結果
";
CM_ SG_ 1664 CECU680_3_0_ADK_SWAPWDA "オーナ用デジタルキー機種交換要求受付可否判定結果
";
CM_ SG_ 1664 CECU680_2_0_E2E_COUNTER "E2Eカウンタ
";
CM_ SG_ 1664 CECU680_0_0_E2E_CRC "E2E_CRC
";
CM_ SG_ 1726 CCU6BE_10_0_CCU_BOOT_STATE "CCU起動状態
";
CM_ SG_ 1726 CCU6BE_9_0_DISP_DRAINAGE "排水制御要求
";
CM_ SG_ 1726 CCU6BE_8_0_DISP_POURING_WATER "注水制御要求
";
CM_ SG_ 1726 CCU6BE_7_4_QDK_DEV "利用者認証デバイス_CID制御
";
CM_ SG_ 1726 CCU6BE_5_0_SLOTID_ERASE "消去対象デバイスSlotID
";
CM_ SG_ 1726 CCU6BE_4_2_QDK_OSWAP "オーナー用デジタルキー機種交換要求_CID制御
";
CM_ SG_ 1726 CCU6BE_4_4_QDK_FDRQ "フレンド用デジタルキー消去要求_CID制御
";
CM_ SG_ 1726 CCU6BE_4_6_QDK_OWCQ "利用者認証要求_CID制御
";
CM_ SG_ 1726 CCU6BE_3_0_QDK_ORRQ "オーナ用デジタルキー登録事前要求_CID制御
";
CM_ SG_ 1726 CCU6BE_3_2_QDK_OGRQ "オーナーデバイス登録処理ステータス確認要求_CID制御
";
CM_ SG_ 1726 CCU6BE_3_4_QDK_ODRQ "オーナ用デジタルキー消去要求_CID制御
";
CM_ SG_ 1726 CCU6BE_3_6_QDK_ADLQ "デジタルキー全キー消去要求_CID制御
";
CM_ SG_ 1726 CCU6BE_2_0_E2E_COUNTER "E2Eカウンタ
";
CM_ SG_ 1726 CCU6BE_0_0_CRC "CRC
";
CM_ SG_ 1613 DKY64D_1_0_BLESRNO2 "デジタルキー制御ECUシリアルNo#2～8
";
CM_ SG_ 1613 DKY64D_0_0_BLESNO1 "デジタルキー制御ECUシリアルNo#1
";
CM_ SG_ 1613 DKY64D_0_5_BLEMSGID "シリアルNo送信ID
";
CM_ SG_ 1612 DKY64C_5_0_DKY_ID "新規登録KID
";
CM_ SG_ 1612 DKY64C_5_6_DKY_RSLT "デバイス登録応答状態
";
CM_ SG_ 1612 DKY64C_4_0_RSRGDK "デバイス登録応答
";
CM_ SG_ 1612 DKY64C_2_0_DKYSID "新規登録SlotIdentifier
";
CM_ SG_ 1612 DKY64C_0_0_DKRGNGFC "登録NG要因
";
CM_ SG_ 1608 DKY648_5_0_MACD2 "MAC値(下位24bit)
";
CM_ SG_ 1608 DKY648_4_0_MACD1 "MAC値(上位4bit)
";
CM_ SG_ 1608 DKY648_4_4_FVD "FV値
";
CM_ SG_ 1608 DKY648_3_0_TMIDD "デジタルキーID
";
CM_ SG_ 1608 DKY648_3_3_WCNTD "カウンタ値
";
CM_ SG_ 1608 DKY648_1_1_WINFD "リモートコントロール情報種別
";
CM_ SG_ 1608 DKY648_0_4_KTYPED "デジタルキー種別
";
CM_ SG_ 1575 DKY627_6_0_SDRGT "スマートデバイス登録状態
";
CM_ SG_ 1575 DKY627_2_0_FRNDFDEOUT "フレンドデバイス猶予期間中
";
CM_ SG_ 1575 DKY627_0_5_SPNUM "スマートデバイス接続台数
";
BA_DEF_ SG_  "Fhi_SignalComment" STRING ;
BA_DEF_ SG_  "GenSigInactiveValue" INT 0 10000;
BA_DEF_ SG_  "GenSigStartValue" FLOAT 0 100000000000;
BA_DEF_ SG_  "GenSigSendType" ENUM  "Cyclic","OnWrite","OnWriteWithRepetition","OnChange","OnChangeWithRepetition","IfActive","IfActiveWithRepetition","NoSigSendType";
BA_DEF_ BO_  "MsgRoutingId" STRING ;
BA_DEF_ BO_  "DiagResponse" ENUM  "No","Yes";
BA_DEF_ BO_  "DiagRequest" ENUM  "No","Yes";
BA_DEF_ BO_  "DiagState" ENUM  "No","Yes";
BA_DEF_ BO_  "GenMsgILSupport" ENUM  "No","Yes";
BA_DEF_ BO_  "GenMsgNrOfRepetition" INT 0 999999;
BA_DEF_ BO_  "GenMsgDelayTime" INT 0 1000;
BA_DEF_ BO_  "GenMsgCycleTimeFast" INT 0 10000;
BA_DEF_ BO_  "GenMsgCycleTime" INT 0 10000;
BA_DEF_ BO_  "GenMsgSendType" ENUM  "Cyclic","NotUsed","NotUsed","NotUsed","NotUsed","Cyclic","NotUsed","IfActive","NoMsgSendType";
BA_DEF_ BO_  "CANFD_BRS" ENUM  "0","1";
BA_DEF_ BO_  "VFrameFormat" ENUM  "StandardCAN","ExtendedCAN","reserved","reserved","reserved","reserved","reserved","reserved","reserved","reserved","reserved","reserved","reserved","reserved","StandardCAN_FD","ExtendedCAN_FD";
BA_DEF_DEF_  "Fhi_SignalComment" "";
BA_DEF_DEF_  "GenSigInactiveValue" 0;
BA_DEF_DEF_  "GenSigStartValue" 0;
BA_DEF_DEF_  "GenSigSendType" "NoSigSendType";
BA_DEF_DEF_  "MsgRoutingId" "";
BA_DEF_DEF_  "DiagResponse" "No";
BA_DEF_DEF_  "DiagRequest" "No";
BA_DEF_DEF_  "DiagState" "No";
BA_DEF_DEF_  "GenMsgILSupport" "Yes";
BA_DEF_DEF_  "GenMsgNrOfRepetition" 0;
BA_DEF_DEF_  "GenMsgDelayTime" 0;
BA_DEF_DEF_  "GenMsgCycleTimeFast" 0;
BA_DEF_DEF_  "GenMsgCycleTime" 0;
BA_DEF_DEF_  "GenMsgSendType" "Cyclic";
BA_DEF_DEF_  "CANFD_BRS" "1";
BA_DEF_DEF_  "VFrameFormat" "StandardCAN";
BA_ "GenMsgCycleTime" BO_ 940 100;
BA_ "GenMsgDelayTime" BO_ 940 10;
BA_ "GenMsgCycleTimeFast" BO_ 940 20;
BA_ "GenMsgNrOfRepetition" BO_ 940 10;
BA_ "MsgRoutingId" BO_ 940 "49 ";
BA_ "GenMsgILSupport" BO_ 940 0;
BA_ "VFrameFormat" BO_ 940 14;
BA_ "GenMsgCycleTime" BO_ 1616 1000;
BA_ "GenMsgDelayTime" BO_ 1616 10;
BA_ "GenMsgCycleTimeFast" BO_ 1616 20;
BA_ "GenMsgNrOfRepetition" BO_ 1616 10;
BA_ "MsgRoutingId" BO_ 1616 "47 ";
BA_ "GenMsgILSupport" BO_ 1616 0;
BA_ "VFrameFormat" BO_ 1616 14;
BA_ "GenMsgCycleTime" BO_ 282 20;
BA_ "MsgRoutingId" BO_ 282 "44 ";
BA_ "GenMsgILSupport" BO_ 282 0;
BA_ "VFrameFormat" BO_ 282 14;
BA_ "GenMsgCycleTime" BO_ 811 100;
BA_ "GenMsgDelayTime" BO_ 811 10;
BA_ "MsgRoutingId" BO_ 811 "40 ";
BA_ "GenMsgILSupport" BO_ 811 0;
BA_ "VFrameFormat" BO_ 811 14;
BA_ "GenMsgCycleTime" BO_ 323 20;
BA_ "MsgRoutingId" BO_ 323 "39 ";
BA_ "GenMsgILSupport" BO_ 323 0;
BA_ "VFrameFormat" BO_ 323 14;
BA_ "GenMsgCycleTime" BO_ 808 100;
BA_ "GenMsgDelayTime" BO_ 808 10;
BA_ "MsgRoutingId" BO_ 808 "37 ";
BA_ "GenMsgILSupport" BO_ 808 0;
BA_ "VFrameFormat" BO_ 808 14;
BA_ "GenMsgCycleTime" BO_ 316 20;
BA_ "MsgRoutingId" BO_ 316 "36 ";
BA_ "GenMsgILSupport" BO_ 316 0;
BA_ "VFrameFormat" BO_ 316 14;
BA_ "GenMsgCycleTime" BO_ 315 20;
BA_ "MsgRoutingId" BO_ 315 "35 ";
BA_ "GenMsgILSupport" BO_ 315 0;
BA_ "VFrameFormat" BO_ 315 14;
BA_ "GenMsgCycleTime" BO_ 313 20;
BA_ "MsgRoutingId" BO_ 313 "33 ";
BA_ "GenMsgILSupport" BO_ 313 0;
BA_ "VFrameFormat" BO_ 313 14;
BA_ "GenMsgCycleTime" BO_ 312 20;
BA_ "MsgRoutingId" BO_ 312 "32 ";
BA_ "GenMsgILSupport" BO_ 312 0;
BA_ "VFrameFormat" BO_ 312 14;
BA_ "GenMsgCycleTime" BO_ 946 120;
BA_ "GenMsgCycleTimeFast" BO_ 946 50;
BA_ "GenMsgNrOfRepetition" BO_ 946 3;
BA_ "MsgRoutingId" BO_ 946 "30 ";
BA_ "GenMsgILSupport" BO_ 946 0;
BA_ "VFrameFormat" BO_ 946 14;
BA_ "GenMsgCycleTime" BO_ 952 500;
BA_ "MsgRoutingId" BO_ 952 "29 ";
BA_ "VFrameFormat" BO_ 952 14;
BA_ "GenMsgCycleTime" BO_ 1712 1200;
BA_ "GenMsgDelayTime" BO_ 1712 10;
BA_ "GenMsgCycleTimeFast" BO_ 1712 50;
BA_ "GenMsgNrOfRepetition" BO_ 1712 2;
BA_ "MsgRoutingId" BO_ 1712 "28 ";
BA_ "VFrameFormat" BO_ 1712 14;
BA_ "GenMsgCycleTime" BO_ 1711 1200;
BA_ "GenMsgDelayTime" BO_ 1711 10;
BA_ "GenMsgCycleTimeFast" BO_ 1711 50;
BA_ "GenMsgNrOfRepetition" BO_ 1711 4;
BA_ "MsgRoutingId" BO_ 1711 "27 ";
BA_ "VFrameFormat" BO_ 1711 14;
BA_ "GenMsgCycleTime" BO_ 1710 1200;
BA_ "GenMsgDelayTime" BO_ 1710 10;
BA_ "GenMsgCycleTimeFast" BO_ 1710 50;
BA_ "GenMsgNrOfRepetition" BO_ 1710 4;
BA_ "MsgRoutingId" BO_ 1710 "26 ";
BA_ "VFrameFormat" BO_ 1710 14;
BA_ "GenMsgCycleTime" BO_ 1709 1200;
BA_ "GenMsgDelayTime" BO_ 1709 10;
BA_ "GenMsgCycleTimeFast" BO_ 1709 50;
BA_ "GenMsgNrOfRepetition" BO_ 1709 4;
BA_ "MsgRoutingId" BO_ 1709 "25 ";
BA_ "VFrameFormat" BO_ 1709 14;
BA_ "GenMsgCycleTime" BO_ 1708 1200;
BA_ "GenMsgDelayTime" BO_ 1708 10;
BA_ "GenMsgCycleTimeFast" BO_ 1708 50;
BA_ "GenMsgNrOfRepetition" BO_ 1708 4;
BA_ "MsgRoutingId" BO_ 1708 "24 ";
BA_ "VFrameFormat" BO_ 1708 14;
BA_ "GenMsgCycleTime" BO_ 1707 1200;
BA_ "GenMsgDelayTime" BO_ 1707 10;
BA_ "GenMsgCycleTimeFast" BO_ 1707 50;
BA_ "GenMsgNrOfRepetition" BO_ 1707 4;
BA_ "MsgRoutingId" BO_ 1707 "23 ";
BA_ "VFrameFormat" BO_ 1707 14;
BA_ "GenMsgCycleTime" BO_ 1706 1200;
BA_ "GenMsgDelayTime" BO_ 1706 10;
BA_ "GenMsgCycleTimeFast" BO_ 1706 50;
BA_ "GenMsgNrOfRepetition" BO_ 1706 4;
BA_ "MsgRoutingId" BO_ 1706 "22 ";
BA_ "VFrameFormat" BO_ 1706 14;
BA_ "GenMsgCycleTime" BO_ 1704 1200;
BA_ "GenMsgDelayTime" BO_ 1704 10;
BA_ "GenMsgCycleTimeFast" BO_ 1704 50;
BA_ "GenMsgNrOfRepetition" BO_ 1704 4;
BA_ "MsgRoutingId" BO_ 1704 "21 ";
BA_ "VFrameFormat" BO_ 1704 14;
BA_ "GenMsgCycleTime" BO_ 1149 1200;
BA_ "GenMsgDelayTime" BO_ 1149 10;
BA_ "GenMsgCycleTimeFast" BO_ 1149 50;
BA_ "GenMsgNrOfRepetition" BO_ 1149 4;
BA_ "MsgRoutingId" BO_ 1149 "20 ";
BA_ "VFrameFormat" BO_ 1149 14;
BA_ "GenMsgCycleTime" BO_ 1148 1200;
BA_ "GenMsgDelayTime" BO_ 1148 10;
BA_ "GenMsgCycleTimeFast" BO_ 1148 50;
BA_ "GenMsgNrOfRepetition" BO_ 1148 4;
BA_ "MsgRoutingId" BO_ 1148 "19 ";
BA_ "VFrameFormat" BO_ 1148 14;
BA_ "GenMsgCycleTime" BO_ 1146 1200;
BA_ "GenMsgDelayTime" BO_ 1146 10;
BA_ "GenMsgCycleTimeFast" BO_ 1146 50;
BA_ "GenMsgNrOfRepetition" BO_ 1146 4;
BA_ "MsgRoutingId" BO_ 1146 "18 ";
BA_ "VFrameFormat" BO_ 1146 14;
BA_ "GenMsgCycleTime" BO_ 1145 1200;
BA_ "GenMsgDelayTime" BO_ 1145 10;
BA_ "GenMsgCycleTimeFast" BO_ 1145 50;
BA_ "GenMsgNrOfRepetition" BO_ 1145 4;
BA_ "MsgRoutingId" BO_ 1145 "17 ";
BA_ "VFrameFormat" BO_ 1145 14;
BA_ "GenMsgCycleTime" BO_ 1144 1000;
BA_ "GenMsgCycleTimeFast" BO_ 1144 20;
BA_ "GenMsgNrOfRepetition" BO_ 1144 3;
BA_ "MsgRoutingId" BO_ 1144 "16 ";
BA_ "VFrameFormat" BO_ 1144 14;
BA_ "GenMsgCycleTime" BO_ 1143 1000;
BA_ "GenMsgCycleTimeFast" BO_ 1143 20;
BA_ "GenMsgNrOfRepetition" BO_ 1143 3;
BA_ "MsgRoutingId" BO_ 1143 "15 ";
BA_ "VFrameFormat" BO_ 1143 14;
BA_ "GenMsgCycleTime" BO_ 1142 500;
BA_ "GenMsgCycleTimeFast" BO_ 1142 20;
BA_ "GenMsgNrOfRepetition" BO_ 1142 3;
BA_ "MsgRoutingId" BO_ 1142 "14 ";
BA_ "VFrameFormat" BO_ 1142 14;
BA_ "GenMsgCycleTime" BO_ 1141 1000;
BA_ "GenMsgCycleTimeFast" BO_ 1141 20;
BA_ "GenMsgNrOfRepetition" BO_ 1141 3;
BA_ "MsgRoutingId" BO_ 1141 "13 ";
BA_ "VFrameFormat" BO_ 1141 14;
BA_ "GenMsgCycleTime" BO_ 927 300;
BA_ "GenMsgDelayTime" BO_ 927 10;
BA_ "GenMsgNrOfRepetition" BO_ 927 1;
BA_ "MsgRoutingId" BO_ 927 "12 ";
BA_ "VFrameFormat" BO_ 927 14;
BA_ "GenMsgCycleTime" BO_ 1112 100;
BA_ "MsgRoutingId" BO_ 1112 "11 ";
BA_ "VFrameFormat" BO_ 1112 14;
BA_ "GenMsgCycleTime" BO_ 1105 1000;
BA_ "GenMsgCycleTimeFast" BO_ 1105 20;
BA_ "GenMsgNrOfRepetition" BO_ 1105 3;
BA_ "MsgRoutingId" BO_ 1105 "10 ";
BA_ "VFrameFormat" BO_ 1105 14;
BA_ "GenMsgCycleTime" BO_ 1665 1000;
BA_ "VFrameFormat" BO_ 1665 14;
BA_ "GenMsgCycleTime" BO_ 1664 1000;
BA_ "GenMsgNrOfRepetition" BO_ 1664 1;
BA_ "VFrameFormat" BO_ 1664 14;
BA_ "GenMsgCycleTime" BO_ 1726 1000;
BA_ "GenMsgDelayTime" BO_ 1726 10;
BA_ "GenMsgNrOfRepetition" BO_ 1726 1;
BA_ "MsgRoutingId" BO_ 1726 "8 ";
BA_ "VFrameFormat" BO_ 1726 14;
BA_ "GenMsgSendType" BO_ 1613 8;
BA_ "MsgRoutingId" BO_ 1613 "6 ";
BA_ "GenMsgILSupport" BO_ 1613 0;
BA_ "VFrameFormat" BO_ 1613 14;
BA_ "GenMsgSendType" BO_ 1612 8;
BA_ "GenMsgNrOfRepetition" BO_ 1612 1;
BA_ "MsgRoutingId" BO_ 1612 "5 ";
BA_ "GenMsgILSupport" BO_ 1612 0;
BA_ "VFrameFormat" BO_ 1612 14;
BA_ "GenMsgCycleTime" BO_ 1608 1000;
BA_ "GenMsgDelayTime" BO_ 1608 10;
BA_ "GenMsgNrOfRepetition" BO_ 1608 1;
BA_ "MsgRoutingId" BO_ 1608 "4 ";
BA_ "GenMsgILSupport" BO_ 1608 0;
BA_ "VFrameFormat" BO_ 1608 14;
BA_ "GenMsgCycleTime" BO_ 1575 1000;
BA_ "GenMsgNrOfRepetition" BO_ 1575 1;
BA_ "MsgRoutingId" BO_ 1575 "2 ";
BA_ "GenMsgILSupport" BO_ 1575 0;
BA_ "VFrameFormat" BO_ 1575 14;
BA_ "GenSigStartValue" SG_ 282 EPS11A_5_1_IND_WARN_EPS 4;
BA_ "GenSigStartValue" SG_ 282 EPS11A_2_2_INT_STR_CONT_EYE 1;
BA_ "Fhi_SignalComment" SG_ 811 EPB32B_6_0_VEHICLE_RUN_STOP_FLG "-

";
BA_ "Fhi_SignalComment" SG_ 811 EPB32B_5_0_FLG_AVH_OILPRES_EPB "-

";
BA_ "Fhi_SignalComment" SG_ 811 EPB32B_5_1_FLG_AVH "-

";
BA_ "Fhi_SignalComment" SG_ 811 EPB32B_5_2_AVH_INTENSIFY_PRES "-

";
BA_ "Fhi_SignalComment" SG_ 811 EPB32B_5_3_BREAK_IND "-

";
BA_ "Fhi_SignalComment" SG_ 811 EPB32B_5_5_AVH_ON_LAMP "-

";
BA_ "Fhi_SignalComment" SG_ 811 EPB32B_4_0_BUZZER "-

";
BA_ "Fhi_SignalComment" SG_ 811 EPB32B_4_2_HILL_HOLD_ON_LAMP "-

";
BA_ "Fhi_SignalComment" SG_ 811 EPB32B_4_3_CLAMP_LAMP "-

";
BA_ "Fhi_SignalComment" SG_ 811 EPB32B_4_5_WARN_LAMP "-

";
BA_ "Fhi_SignalComment" SG_ 811 EPB32B_4_7_WARN_EPB_MET_LCD "-

";
BA_ "Fhi_SignalComment" SG_ 811 EPB32B_3_0_STATUS_EPB "-

";
BA_ "Fhi_SignalComment" SG_ 811 EPB32B_3_3_DYNAMIC_PARKING "-

";
BA_ "Fhi_SignalComment" SG_ 811 EPB32B_3_4_HILL_HOLD_RUN_FLG "-

";
BA_ "Fhi_SignalComment" SG_ 811 EPB32B_3_5_INHIBIT_ISS_DELAY "-

";
BA_ "Fhi_SignalComment" SG_ 811 EPB32B_3_6_INHIBIT_ISS "-

";
BA_ "Fhi_SignalComment" SG_ 811 EPB32B_2_0_ERR_INFO "-

";
BA_ "Fhi_SignalComment" SG_ 811 EPB32B_2_2_EPB_FAIL_FLG1 "-

";
BA_ "Fhi_SignalComment" SG_ 811 EPB32B_2_3_EPB_FAIL_FLG2 "-

";
BA_ "Fhi_SignalComment" SG_ 811 EPB32B_2_4_EPB_FAIL_FLG3 "-

";
BA_ "Fhi_SignalComment" SG_ 811 EPB32B_1_5_REQ_COMM_CONT "-

";
BA_ "GenSigSendType" SG_ 808 VDC328_7_3_FLAG_ACT_CBC 3;
BA_ "GenSigStartValue" SG_ 808 VDC328_5_2_WARN_BRAKE_BOOST 1;
BA_ "GenSigSendType" SG_ 808 VDC328_5_4_WARN_RBS 3;
BA_ "GenSigSendType" SG_ 808 VDC328_5_6_IND_HSA_ON 3;
BA_ "GenSigStartValue" SG_ 808 VDC328_5_7_IND_TCS_OFF 1;
BA_ "GenSigSendType" SG_ 808 VDC328_5_7_IND_TCS_OFF 3;
BA_ "GenSigStartValue" SG_ 808 VDC328_4_0_IND_VDC_OFF 1;
BA_ "GenSigStartValue" SG_ 808 VDC328_4_5_WARNING_BRAKE_SYS 1;
BA_ "GenSigStartValue" SG_ 808 VDC328_3_0_IND_WARN_EBD 1;
BA_ "GenSigStartValue" SG_ 808 VDC328_3_1_IND_WARN_ABS 1;
BA_ "GenSigStartValue" SG_ 808 VDC328_3_2_IND_WARN_VDC 1;
BA_ "GenSigStartValue" SG_ 808 VDC328_3_3_IND_WARN_HSA 1;
BA_ "GenSigStartValue" SG_ 808 VDC328_3_6_IND_TCS_OFF 1;
BA_ "Fhi_SignalComment" SG_ 316 VDC13C_7_0_RCV_FAIL_ADA "EyeSight対応以外は『0固定』

";
BA_ "Fhi_SignalComment" SG_ 316 VDC13C_7_1_FAIL_PCU "EyeSight対応以外は『0固定』

";
BA_ "Fhi_SignalComment" SG_ 316 VDC13C_7_2_CONT_STATE_ES_BRAKE "EyeSight対応以外は『0固定』

";
BA_ "Fhi_SignalComment" SG_ 316 VDC13C_7_3_ASST_PRECRUSH_ACC "EyeSight対応以外は『0固定』

";
BA_ "Fhi_SignalComment" SG_ 316 VDC13C_7_4_CONT_STATE_PRECRUSH "EyeSight対応以外は『0固定』

";
BA_ "Fhi_SignalComment" SG_ 316 VDC13C_7_5_PERMIT_BRAKE_ACC "EyeSight対応以外は『0固定』

";
BA_ "Fhi_SignalComment" SG_ 316 VDC13C_7_6_DETECT_BRAKING "EyeSight対応以外は『0固定』

";
BA_ "GenSigStartValue" SG_ 316 VDC13C_6_6_VDC_OFF 1;
BA_ "Fhi_SignalComment" SG_ 316 VDC13C_5_7_ACTIVATE_TSM "BF4：「0：非制御中」固定

";
BA_ "Fhi_SignalComment" SG_ 316 VDC13C_1_7_STATUS_BRAKELAMP "EyeSight対応以外は『0固定』

";
BA_ "Fhi_SignalComment" SG_ 315 VDC13B_7_0_ACCELERATE_F_R "補正値

";
BA_ "Fhi_SignalComment" SG_ 315 VDC13B_6_0_ACCELERATE_L_R "補正値

";
BA_ "GenSigStartValue" SG_ 315 VDC13B_4_0_ENG_TRQ_DOWN 65535;
BA_ "GenSigStartValue" SG_ 313 VDC139_7_4_FAIL_PRESSURE_SSR 1;
BA_ "Fhi_SignalComment" SG_ 313 VDC139_7_5_STATUS_EPB "-

";
BA_ "GenSigStartValue" SG_ 313 VDC139_4_3_FAIL_BRAKELAMPSW 1;
BA_ "GenSigStartValue" SG_ 313 VDC139_3_5_FAIL_VDC_SSR 1;
BA_ "GenSigStartValue" SG_ 313 VDC139_3_6_FAIL_SPD_SSR_FHI 1;
BA_ "GenSigStartValue" SG_ 313 VDC139_3_7_FAIL_ABS_SYS 1;
BA_ "Fhi_SignalComment" SG_ 313 VDC139_2_0_SPD_WHEEL_AVE "GW:ID139-B3b4~B2b0→ID270-B5b4~B4b0

";
BA_ "GenSigStartValue" SG_ 313 VDC139_1_4_FAIL_HDC_SYS 1;
BA_ "Fhi_SignalComment" SG_ 313 VDC139_1_5_VEHICLE_HIGHT "XUVは「01:OBK」/北米SPORT_OBKは「10:標準」を送信

";
BA_ "Fhi_SignalComment" SG_ 312 VDC138_7_0_PRESSURE_WC_FTLH "EyeSight対応以外は『0固定』

";
BA_ "Fhi_SignalComment" SG_ 312 VDC138_6_0_PRESSURE_WC_FTRH "EyeSight対応以外は『0固定』

";
BA_ "Fhi_SignalComment" SG_ 312 VDC138_4_0_YAW_RATE "補正値

";
BA_ "Fhi_SignalComment" SG_ 312 VDC138_2_0_STEER_ANGLE "補正値

";
BA_ "GenSigStartValue" SG_ 952 CCU3B8_4_3_ACPANEL_SEAT_V_TEMP_P 3;
BA_ "GenSigStartValue" SG_ 952 CCU3B8_4_0_ACPANEL_SEAT_V_TEMP_D 3;
BA_ "GenSigStartValue" SG_ 952 CCU3B8_3_3_ACPANEL_SEAT_H_TEMP_P 3;
BA_ "GenSigStartValue" SG_ 952 CCU3B8_3_0_ACPANEL_SEAT_H_TEMP_D 3;
BA_ "GenSigStartValue" SG_ 1709 CCU6AD_6_3_EYE_MONI_BLUE_IND_SET 1;
BA_ "GenSigStartValue" SG_ 1709 CCU6AD_6_2_EYE_MONI_GRE_IND_SET 1;
BA_ "GenSigStartValue" SG_ 1709 CCU6AD_6_1_EYE_MONI_YEL_IND_SET 1;
BA_ "GenSigStartValue" SG_ 1709 CCU6AD_6_0_EYE_MONI_RED_IND_SET 1;
BA_ "Fhi_SignalComment" SG_ 1708 CCU6AC_5_0_WELCOME_SET "このシグナルにてイベント発生時は20ms×3times送信

";
BA_ "GenSigStartValue" SG_ 1708 CCU6AC_4_5_COMPASS_DISP_SET 4;
BA_ "GenSigStartValue" SG_ 1708 CCU6AC_3_1_ILL_CONT_SW_NIGHT_SIG 110;
BA_ "GenSigStartValue" SG_ 1708 CCU6AC_2_0_ILL_CONT_SW_SIG 110;
BA_ "GenSigStartValue" SG_ 1149 CCU47D_3_0_AA_EST_CHG_TIME 4294967295;
BA_ "GenSigStartValue" SG_ 1148 CCU47C_7_0_AA_CRG_MAX_OUT_WAT 4294967295;
BA_ "GenSigStartValue" SG_ 1148 CCU47C_3_0_AA_DEP_MIN_BAT_LEVEL 4294967295;
BA_ "GenSigStartValue" SG_ 1144 CCU478_23_0_LAT_CHG_END_TIME 2046;
BA_ "GenSigStartValue" SG_ 1144 CCU478_21_2_LAT_CHG_START_TIME 2046;
BA_ "GenSigStartValue" SG_ 1144 CCU478_16_0_DEP_TIM4_START_TIME 2046;
BA_ "GenSigStartValue" SG_ 1144 CCU478_12_0_DEP_TIM3_START_TIME 2046;
BA_ "GenSigStartValue" SG_ 1144 CCU478_8_0_DEP_TIM2_START_TIME 2046;
BA_ "GenSigStartValue" SG_ 1144 CCU478_4_0_DEP_TIM1_START_TIME 2046;
BA_ "GenSigStartValue" SG_ 1143 CCU477_24_0_TIM4_CHG_END_TIME 2046;
BA_ "GenSigStartValue" SG_ 1143 CCU477_22_2_TIM4_CHG_START_TIME 2046;
BA_ "GenSigStartValue" SG_ 1143 CCU477_18_0_TIM3_CHG_END_TIME 2046;
BA_ "GenSigStartValue" SG_ 1143 CCU477_16_2_TIM3_CHG_START_TIME 2046;
BA_ "GenSigStartValue" SG_ 1143 CCU477_12_0_TIM2_CHG_END_TIME 2046;
BA_ "GenSigStartValue" SG_ 1143 CCU477_10_2_TIM2_CHG_START_TIME 2046;
BA_ "GenSigStartValue" SG_ 1143 CCU477_6_0_TIM1_CHG_END_TIME 2046;
BA_ "GenSigStartValue" SG_ 1143 CCU477_4_2_TIM1_CHG_START_TIME 2046;
BA_ "GenSigStartValue" SG_ 1142 CCU476_13_1_STS_PNC 2;
BA_ "GenSigStartValue" SG_ 1142 CCU476_11_1_STOP_TIM_TIM_CHG 511;
BA_ "GenSigStartValue" SG_ 1142 CCU476_10_0_START_TIM_TIM_CHG 511;
BA_ "GenSigStartValue" SG_ 1142 CCU476_5_1_STOP_TIM_CH_TIM_CHG 511;
BA_ "GenSigStartValue" SG_ 1142 CCU476_4_0_START_TIM_CH_TIM_CHG 511;
BA_ "GenSigStartValue" SG_ 1105 CCU451_6_0_CHG_COMTI 2046;
BA_ "GenSigStartValue" SG_ 1105 CCU451_4_1_CHG_HILMT_REQ 126;
BA_ "GenSigStartValue" SG_ 1105 CCU451_3_4_DCCHG_PWRUPLMT 14;
BA_ "GenSigStartValue" SG_ 1105 CCU451_3_0_ACCHG_CORUPLMT 14;
BA_ "GenSigSendType" SG_ 1664 CECU680_7_0_RSLT_DEV 3;
BA_ "GenSigSendType" SG_ 1664 CECU680_6_4_SDK_PRG 3;
BA_ "GenSigSendType" SG_ 1664 CECU680_6_0_RSLT_AUTHORITY 3;
BA_ "GenSigSendType" SG_ 1664 CECU680_5_6_RDK_SWAPGRL 3;
BA_ "GenSigSendType" SG_ 1664 CECU680_5_4_RDK_ORRL 3;
BA_ "GenSigSendType" SG_ 1664 CECU680_4_6_RDK_ADRL 3;
BA_ "GenSigSendType" SG_ 1664 CECU680_4_4_RDK_ODRL 3;
BA_ "GenSigSendType" SG_ 1664 CECU680_4_2_RDK_FDRL 3;
BA_ "GenSigSendType" SG_ 1664 CECU680_4_0_RDK_OGRL 3;
BA_ "GenSigSendType" SG_ 1664 CECU680_3_7_ADK_ADLA 3;
BA_ "GenSigSendType" SG_ 1664 CECU680_3_6_ADK_OWDA 3;
BA_ "GenSigSendType" SG_ 1664 CECU680_3_4_ADK_REGA 3;
BA_ "GenSigSendType" SG_ 1664 CECU680_3_3_ADK_STCA 3;
BA_ "GenSigSendType" SG_ 1664 CECU680_3_2_ADK_SWAPSTACA 3;
BA_ "GenSigSendType" SG_ 1664 CECU680_3_1_ADK_FWDA 3;
BA_ "GenSigSendType" SG_ 1664 CECU680_3_0_ADK_SWAPWDA 3;
BA_ "GenSigSendType" SG_ 1664 CECU680_2_0_E2E_COUNTER 3;
BA_ "GenSigSendType" SG_ 1664 CECU680_0_0_E2E_CRC 3;
BA_ "GenSigSendType" SG_ 1726 CCU6BE_10_0_CCU_BOOT_STATE 3;
BA_ "GenSigSendType" SG_ 1726 CCU6BE_9_0_DISP_DRAINAGE 3;
BA_ "GenSigSendType" SG_ 1726 CCU6BE_8_0_DISP_POURING_WATER 3;
BA_ "GenSigSendType" SG_ 1726 CCU6BE_7_4_QDK_DEV 3;
BA_ "GenSigSendType" SG_ 1726 CCU6BE_5_0_SLOTID_ERASE 3;
BA_ "GenSigSendType" SG_ 1726 CCU6BE_4_2_QDK_OSWAP 3;
BA_ "GenSigSendType" SG_ 1726 CCU6BE_4_4_QDK_FDRQ 3;
BA_ "GenSigSendType" SG_ 1726 CCU6BE_4_6_QDK_OWCQ 3;
BA_ "GenSigSendType" SG_ 1726 CCU6BE_3_0_QDK_ORRQ 3;
BA_ "GenSigSendType" SG_ 1726 CCU6BE_3_2_QDK_OGRQ 3;
BA_ "GenSigSendType" SG_ 1726 CCU6BE_3_4_QDK_ODRQ 3;
BA_ "GenSigSendType" SG_ 1726 CCU6BE_3_6_QDK_ADLQ 3;
BA_ "GenSigSendType" SG_ 1726 CCU6BE_2_0_E2E_COUNTER 3;
BA_ "GenSigSendType" SG_ 1726 CCU6BE_0_0_CRC 3;
BA_ "GenSigSendType" SG_ 1612 DKY64C_5_0_DKY_ID 2;
BA_ "GenSigSendType" SG_ 1612 DKY64C_5_6_DKY_RSLT 2;
BA_ "GenSigSendType" SG_ 1612 DKY64C_4_0_RSRGDK 2;
BA_ "GenSigSendType" SG_ 1612 DKY64C_2_0_DKYSID 2;
BA_ "GenSigSendType" SG_ 1612 DKY64C_0_0_DKRGNGFC 2;
BA_ "GenSigSendType" SG_ 1608 DKY648_5_0_MACD2 1;
BA_ "GenSigSendType" SG_ 1608 DKY648_4_0_MACD1 1;
BA_ "GenSigSendType" SG_ 1608 DKY648_4_4_FVD 1;
BA_ "GenSigSendType" SG_ 1608 DKY648_3_0_TMIDD 1;
BA_ "GenSigSendType" SG_ 1608 DKY648_3_3_WCNTD 1;
BA_ "GenSigSendType" SG_ 1608 DKY648_1_1_WINFD 1;
BA_ "GenSigSendType" SG_ 1608 DKY648_0_4_KTYPED 1;
BA_ "GenSigSendType" SG_ 1575 DKY627_6_0_SDRGT 3;
BA_ "GenSigSendType" SG_ 1575 DKY627_2_0_FRNDFDEOUT 3;
BA_ "GenSigSendType" SG_ 1575 DKY627_0_5_SPNUM 3;
VAL_ 940 BIU3AC_7_0_HEADLAMP_SMALL 1 "Turn_ON" 0 "Turn_OFF" ;
VAL_ 940 BIU3AC_7_1_HEADLAMP_LO_REQ 1 "Turn_ON" 0 "Turn_OFF" ;
VAL_ 940 BIU3AC_7_2_HEADLAMP_HI_REQ 1 "Turn_ON" 0 "Turn_OFF" ;
VAL_ 940 BIU3AC_7_3_FT_FOG_RELAY_REQ 1 "Turn_ON" 0 "Turn_OFF" ;
VAL_ 940 BIU3AC_7_4_FOGLAMP_RR 1 "Turn_ON" 0 "Turn_OFF" ;
VAL_ 940 BIU3AC_7_5_DRL 1 "Turn_ON" 0 "Turn_OFF" ;
VAL_ 940 BIU3AC_7_6_WIPER_FRONT 1 "ON" 0 "OFF" ;
VAL_ 940 BIU3AC_7_7_RDEF_RELAY_REQ 1 "ON" 0 "OFF" ;
VAL_ 940 BIU3AC_6_0_RDEFOGSW 1 "ON" 0 "OFF" ;
VAL_ 940 BIU3AC_6_1_CSTM_PRG 1 "PRG" 0 "NOT_PRG" ;
VAL_ 940 BIU3AC_6_2_FAIL_SHIFTLOCKSOL 1 "FAIL" 0 "NORMAL" ;
VAL_ 940 BIU3AC_6_3_REQ_CANCEL_ISS 1 "CANCEL" 0 "NON_CANCEL" ;
VAL_ 940 BIU3AC_6_4_REVERSE_MT 1 "REVERSE_ON" 0 "OFF" ;
VAL_ 940 BIU3AC_6_5_HANDBRAKE 1 "ON" 0 "OFF" ;
VAL_ 940 BIU3AC_6_6_BRAKELAMPSW 1 "ON" 0 "OFF" ;
VAL_ 940 BIU3AC_6_7_TOWING_SW 1 "ON" 0 "OFF" ;
VAL_ 940 BIU3AC_5_0_LANE_OFF_SW 3 "NONE" 2 "BREAKING_OF_WIRE" 1 "P-CR-OFF-SW_ON" 0 "OFF" ;
VAL_ 940 BIU3AC_5_2_PCR_OFF_SW 3 "NONE" 2 "BREAKING_OF_WIRE" 1 "P-CR-OFF-SW_ON" 0 "OFF" ;
VAL_ 940 BIU3AC_5_4_DIMMER_CANCEL 1 "ACTIVE" 0 "NON_ACTIVE" ;
VAL_ 940 BIU3AC_5_5_KEYSW 1 "ON" 0 "OFF" ;
VAL_ 940 BIU3AC_5_6_IND_ND_SHIFTLOCK 1 "表示" 0 "非表示" ;
VAL_ 940 BIU3AC_4_0_DOOR_DRVR 1 "OPEN" 0 "CLOSE" ;
VAL_ 940 BIU3AC_4_1_DOOR_PASS 1 "OPEN" 0 "CLOSE" ;
VAL_ 940 BIU3AC_4_2_DOOR_RRRH 1 "OPEN" 0 "CLOSE" ;
VAL_ 940 BIU3AC_4_3_DOOR_RRLH 1 "OPEN" 0 "CLOSE" ;
VAL_ 940 BIU3AC_4_4_DOOR_RG 1 "OPEN" 0 "CLOSE" ;
VAL_ 940 BIU3AC_4_5_DOOR_TR 1 "OPEN" 0 "CLOSE" ;
VAL_ 940 BIU3AC_4_6_HOOD_CLOSE 1 "ON" 0 "OFF" ;
VAL_ 940 BIU3AC_4_7_HOOD_OPEN 1 "ON" 0 "OFF" ;
VAL_ 940 BIU3AC_3_0_GW_STSW_RES 1 "REQ_RES_EGStart" 0 "NON_REQ_RES_EGStart" ;
VAL_ 940 BIU3AC_3_1_GW_POWER_RES 2 "RES_Start_MODE" 1 "Pre_Air_Cond_MODE" 0 "Normal_MODE" ;
VAL_ 940 BIU3AC_3_3_ST1 1 "ST" 0 "NORMAL" ;
VAL_ 940 BIU3AC_3_4_ST2 1 "ST" 0 "NORMAL" ;
VAL_ 940 BIU3AC_3_5_ACC 1 "ON" 0 "OFF" ;
VAL_ 940 BIU3AC_3_6_IGA 1 "ON" 0 "OFF" ;
VAL_ 940 BIU3AC_3_7_BAT_BACKUP 1 "ON" 0 "OFF" ;
VAL_ 940 BIU3AC_2_0_CSTM_AC 1 "ACTIVE" 0 "NON_ACTIVE" ;
VAL_ 940 BIU3AC_2_1_IMB_SMT 3 "Push&SMT" 2 "IMB_NO" 1 "IMB_YES" 0 "NON" ;
VAL_ 940 BIU3AC_2_3_CSTM_WGN_SDN 1 "WGN" 0 "SDN" ;
VAL_ 940 BIU3AC_2_4_VAL_SEAT_BACK_CTSM 1 "SEAT_BACK_ON" 0 "SEAT_BACK_OFF" ;
VAL_ 940 BIU3AC_2_5_VAL_MIR_AFOLD_CTSM 1 "MIR_AFOLD_ON" 0 "MIR_AFOLD_OFF" ;
VAL_ 940 BIU3AC_2_6_VAL_MIR_RTILT_CTSM 1 "MIR_RTILT_ON" 0 "MIR_RTILT_OFF" ;
VAL_ 940 BIU3AC_2_7_WIPER_REAR 1 "ON" 0 "OFF" ;
VAL_ 940 BIU3AC_1_4_PADDLESHIFT_DOWN_SW 1 "ON" 0 "OFF" ;
VAL_ 940 BIU3AC_1_5_PADDLESHIFT_UP_SW 1 "ON" 0 "OFF" ;
VAL_ 940 BIU3AC_1_6_MANUALMODE_SW 1 "ON" 0 "OFF" ;
VAL_ 1616 BIU650_7_3_DOOR_LINK_SW_STS 1 "ON" 0 "OFF" ;
VAL_ 1616 BIU650_6_3_RR_WIPER_STATUS 3 "Undefined" 2 "Hi" 1 "Lo" 0 "OFF" ;
VAL_ 1616 BIU650_6_5_WIPER_SENSITIVITY_CTM 3 "4" 2 "3" 1 "2" 0 "1" ;
VAL_ 1616 BIU650_5_2_FMH_DOOR_LOCK 3 "Undefined" 2 "Unlock" 1 "Lock" 0 "No request" ;
VAL_ 1616 BIU650_5_4_LMH_DOOR_LOCK 3 "Undefined" 2 "Unlock" 1 "Lock" 0 "No request" ;
VAL_ 1616 BIU650_4_0_REQ_OPE_AUTOLIGHT 3 "Undefined" 2 "Lo" 1 "Small" 0 "OFF" ;
VAL_ 1616 BIU650_4_2_STATE_SHINSSR 3 "Normal Mode" 2 "Diagnostic Mode" 1 "Shipping Inspection Mode" 0 "Initialization Mode" ;
VAL_ 1616 BIU650_4_4_STATE_RLS_FAIL 3 "Undefined" 2 "Recovering" 1 "Abnormal" 0 "Normal" ;
VAL_ 1616 BIU650_3_0_REQ_FWASHER_ITLOCK 1 "ON" 0 "OFF" ;
VAL_ 1616 BIU650_3_1_FWIPER_RTN 1 "ON" 0 "OFF" ;
VAL_ 1616 BIU650_3_2_TURN_LAMP_STATE_LEFT 1 "Blink" 0 "OFF" ;
VAL_ 1616 BIU650_3_3_TURN_LAMP_STATE_RIGHT 1 "Blink" 0 "OFF" ;
VAL_ 1616 BIU650_2_0_HEADLAMP_SMALL_SW 1 "ON" 0 "OFF" ;
VAL_ 1616 BIU650_2_1_HEADLAMP_LO_SW 1 "ON" 0 "OFF" ;
VAL_ 1616 BIU650_2_2_HEADLAMP_OFF_SW 1 "ON" 0 "OFF" ;
VAL_ 1616 BIU650_2_3_HEADLAMP_Hi_SW 1 "ON" 0 "OFF" ;
VAL_ 1616 BIU650_2_4_HEAD_LAMP_PASS_SW 1 "ON" 0 "OFF" ;
VAL_ 1616 BIU650_2_5_FFOG_SW 1 "ON" 0 "OFF" ;
VAL_ 1616 BIU650_2_6_RFOG_SW 1 "ON" 0 "OFF" ;
VAL_ 282 EPS11A_5_1_IND_WARN_EPS 6 "Turn_ON(Fail_mode2_with_INFO)" 5 "Turn_ON(Fail_mode1_without_INFO)" 4 "Turn_ON(Normal:3s_After_IGN_ON)" 3 "Reserve" 2 "Reserve" 1 "Reserve" 0 "Turn_OFF(Normal)" ;
VAL_ 282 EPS11A_5_4_INFO_WARN_EPS 7 "Reserve" 6 "Reserve" 5 "Reserve" 4 "Reserve" 3 "Reserve" 2 "Reserve" 1 "Turn_ON_(Prohibition of Use)" 0 "Turn_OFF(Normal)" ;
VAL_ 282 EPS11A_2_0_STA_STR_CONT_EYE 1 "ACTIVE" 0 "NON_ACTIVE" ;
VAL_ 282 EPS11A_2_1_RECOG_STR_CONT_EYE 1 "RECOGNITION" 0 "NON_RECOGNITION" ;
VAL_ 282 EPS11A_2_2_INT_STR_CONT_EYE 1 "DETECT" 0 "NON_DETECT" ;
VAL_ 282 EPS11A_2_3_LCT_LINK_CTRL_STATE 1 "ENABLE" 0 "DISABLE" ;
VAL_ 282 EPS11A_2_4_EPS_TYPE 1 "MAC" 0 "NON MAC" ;
VAL_ 282 EPS11A_2_5_OVR_JDG_FLG 3 "オーバーライド有 ②" 2 "オーバーライド有 ②" 1 "オーバーライド有 ①" 0 "オーバーライド無" ;
VAL_ 282 EPS11A_1_4_MORS_ACT_FLAG 1 "Activation" 0 "Non Activation" ;
VAL_ 282 EPS11A_1_7_EXIST_OVERRIDE 1 "WITH_OVERRIDE" 0 "WIITHOUT_OVERRIDE" ;
VAL_ 811 EPB32B_6_0_VEHICLE_RUN_STOP_FLG 3 "reserve" 2 "ERROR" 1 "DRIVING" 0 "STOPPING" ;
VAL_ 811 EPB32B_6_2_REQ_HILL_P_CAUTION 1 "Turn_ON" 0 "Turn_OFF" ;
VAL_ 811 EPB32B_5_0_FLG_AVH_OILPRES_EPB 0 "NOT_OPERATE" 1 "OPERATE" ;
VAL_ 811 EPB32B_5_1_FLG_AVH 1 "AVH_OPERATE" 0 "AVH_NOT_OPERATE" ;
VAL_ 811 EPB32B_5_2_AVH_INTENSIFY_PRES 0 "OTHER" 1 "AVH_INTENSIFY_PRESSURE_DURING_ISS" ;
VAL_ 811 EPB32B_5_3_BREAK_IND 3 "UNDEFINED(TURN_OFF/DISPLAY OFF)" 2 "BLINK(Segment LC) or DISPLAY ON(Color LC)" 1 "TURN_ON(Segment LC) or DISPLAY ON(Color LC)" 0 "TURN_OFF(Segment LC) or DISPLAY OFF(Color LC)" ;
VAL_ 811 EPB32B_5_5_AVH_ON_LAMP 1 "ON" 0 "OFF" ;
VAL_ 811 EPB32B_5_6_AVH_FUNC_ON_LUMP 1 "ON" 0 "OFF" ;
VAL_ 811 EPB32B_5_7_AVH_ACTIVE 1 "WITH_AVH" 0 "WIITHOUT_AVH" ;
VAL_ 811 EPB32B_4_0_BUZZER 3 "CANCEL_Pi-X1" 2 "SHIFT_DISABLE_PiX2" 1 "DRIVER_BRAKE_CUE_Pi-" 0 "NO_BUZZER" ;
VAL_ 811 EPB32B_4_2_HILL_HOLD_ON_LAMP 1 "ON" 0 "OFF" ;
VAL_ 811 EPB32B_4_3_CLAMP_LAMP 3 "No_difinition" 2 "LAMP_BLINK" 1 "LAMP_ON" 0 "LAMP_OFF" ;
VAL_ 811 EPB32B_4_5_WARN_LAMP 3 "No_difinition" 2 "LAMP_BLINK" 1 "LAMP_ON" 0 "LAMP_OFF" ;
VAL_ 811 EPB32B_4_7_WARN_EPB_MET_LCD 1 "INDICATE" 0 "NOT_IINDICATE" ;
VAL_ 811 EPB32B_3_0_STATUS_EPB 7 "No_difinition" 6 "No_difinition" 5 "DYNAMIC PARKING" 4 "RELEASING" 3 "OPERATING" 2 "OPERATE" 1 "RELEASE" 0 "ERROR" ;
VAL_ 811 EPB32B_3_3_DYNAMIC_PARKING 1 "ON" 0 "OFF" ;
VAL_ 811 EPB32B_3_4_HILL_HOLD_RUN_FLG 1 "OPERATE" 0 "NOT_OPERATE" ;
VAL_ 811 EPB32B_3_5_INHIBIT_ISS_DELAY 1 "INHIBIT" 0 "PERMIT" ;
VAL_ 811 EPB32B_3_6_INHIBIT_ISS 1 "INHIBIT" 0 "PERMIT" ;
VAL_ 811 EPB32B_3_7_AVH_PERMIT_CONT_ACC 1 "PERMISSION" 0 "PROHIBITION" ;
VAL_ 811 EPB32B_2_0_ERR_INFO 3 "PULL_FORCE_FAIL" 2 "EMERGENCY_RELEASE" 1 "STROKE_SHORT" 0 "NORMAL" ;
VAL_ 811 EPB32B_2_2_EPB_FAIL_FLG1 1 "PERMIT" 0 "INHIBIT" ;
VAL_ 811 EPB32B_2_3_EPB_FAIL_FLG2 1 "PERMIT" 0 "INHIBIT" ;
VAL_ 811 EPB32B_2_4_EPB_FAIL_FLG3 1 "PERMIT" 0 "INHIBIT" ;
VAL_ 811 EPB32B_1_4_WAKE_UP_FRAME 1 "WakeUP_FRAME" 0 "Normal_FRAME" ;
VAL_ 811 EPB32B_1_5_REQ_COMM_CONT 1 "REQUEST" 0 "NO_REQUEST" ;
VAL_ 323 VDC143_1_4_IG_ON 0 "OFF" 1 "ON" ;
VAL_ 323 VDC143_1_5_VEHICLE_SPEED_Q 3 "Reserved" 2 "Faulty" 1 "Normal" 0 "NotInitialized" ;
VAL_ 323 VDC143_1_7_DIAG_STATUS 0 "NON DIAG MODE" 1 "DIAG MODE" ;
VAL_ 808 VDC328_7_1_IND_WARN_CBC 1 "Turn_ON" 0 "Turn_OFF" ;
VAL_ 808 VDC328_7_2_ACTIVATE_CBC 1 "Turn_ON" 0 "Turn_OFF" ;
VAL_ 808 VDC328_7_3_FLAG_ACT_CBC 1 "ACTIVE" 0 "NON_ACTIVE" ;
VAL_ 808 VDC328_6_0_PROHIBIT_VDC_OFF_CCU 1 "PROHIBIT" 0 "PERMIT" ;
VAL_ 808 VDC328_6_1_PROHIBIT_AVH_CCU 1 "PROHIBIT" 0 "PERMIT" ;
VAL_ 808 VDC328_5_0_VDC_BUZZER 3 "reserve" 2 "VDC_OFF_SHIFT" 1 "VDC_OFF_SHIFT_DISABLE" 0 "NO_BUZZER" ;
VAL_ 808 VDC328_5_2_WARN_BRAKE_BOOST 1 "TURN_ON" 0 "TURN_OFF" ;
VAL_ 808 VDC328_5_6_IND_HSA_ON 1 "HSA ON" 0 "HSA OFF" ;
VAL_ 808 VDC328_5_7_IND_TCS_OFF 1 "Turn_ON" 0 "Turn_OFF" ;
VAL_ 808 VDC328_4_0_IND_VDC_OFF 1 "Turn_ON" 0 "Turn_OFF" ;
VAL_ 808 VDC328_4_1_STATE_ACTIVATE_VDC 1 "ACTIVE" 0 "NON_ACTIVE" ;
VAL_ 808 VDC328_4_2_IND_HSA_OFF 1 "HSA OFF" 0 "HSA ON" ;
VAL_ 808 VDC328_4_3_IND_HDC 3 "Uncertain_TURN_OFF" 2 "BLINK" 1 "TURN_ON" 0 "TURN_OFF" ;
VAL_ 808 VDC328_4_5_WARNING_BRAKE_SYS 3 "reserve" 2 "reserve" 1 "TURN_ON" 0 "TURN_OFF" ;
VAL_ 808 VDC328_4_7_ACTIVE_OHB 1 "ACTIVE" 0 "DEACTIVE" ;
VAL_ 808 VDC328_3_0_IND_WARN_EBD 1 "Turn_ON" 0 "Turn_OFF" ;
VAL_ 808 VDC328_3_1_IND_WARN_ABS 1 "Turn_ON" 0 "Turn_OFF" ;
VAL_ 808 VDC328_3_2_IND_WARN_VDC 1 "Turn_ON" 0 "Turn_OFF" ;
VAL_ 808 VDC328_3_3_IND_WARN_HSA 1 "Turn_ON" 0 "Turn_OFF" ;
VAL_ 808 VDC328_3_4_WARN_BRAKEFLUID_LV 3 "OTHER_FAIL" 2 "RESERVE" 1 "FAIL_Turn_ON" 0 "Turn_OFF" ;
VAL_ 808 VDC328_3_6_IND_TCS_OFF 1 "ON" 0 "OFF" ;
VAL_ 808 VDC328_3_7_EXIST_EPB 1 "WITH_EPB" 0 "WIITHOUT_EPB" ;
VAL_ 808 VDC328_2_0_WARN_EBD_MET_LCD 1 "INDICATE" 0 "NOT_IINDICATE" ;
VAL_ 808 VDC328_2_1_WARN_ABS_MET_LCD 1 "INDICATE" 0 "NOT_IINDICATE" ;
VAL_ 808 VDC328_2_2_WARN_VDC_MET_LCD 1 "INDICATE" 0 "NOT_IINDICATE" ;
VAL_ 808 VDC328_2_3_WARN_HSA_MET_LCD 1 "INDICATE" 0 "NOT_IINDICATE" ;
VAL_ 808 VDC328_2_4_EXIST_VECTARING 1 "WITH VECTORING(16inch_BRAKE)" 0 "WITHOUT VECTORING(15inch_BRAKE)" ;
VAL_ 316 VDC13C_7_0_RCV_FAIL_ADA 1 "ALIVE" 0 "NO_ALIVE" ;
VAL_ 316 VDC13C_7_1_FAIL_PCU 1 "NORMAL" 0 "FAIL" ;
VAL_ 316 VDC13C_7_2_CONT_STATE_ES_BRAKE 1 "ALIVE" 0 "NO_ALIVE" ;
VAL_ 316 VDC13C_7_3_ASST_PRECRUSH_ACC 1 "ACTIVE" 0 "NON_ACTIVE" ;
VAL_ 316 VDC13C_7_4_CONT_STATE_PRECRUSH 1 "ACTIVE" 0 "NON_ACTIVE" ;
VAL_ 316 VDC13C_7_5_PERMIT_BRAKE_ACC 1 "PERMIT" 0 "INHIBIT" ;
VAL_ 316 VDC13C_7_6_DETECT_BRAKING 1 "Driver Brake_ON" 0 "Driver Brake_OFF" ;
VAL_ 316 VDC13C_7_7_EMERGENCY_BRAKE 1 "ON" 0 "OFF" ;
VAL_ 316 VDC13C_6_6_VDC_OFF 1 "SYS_ON" 0 "SYS_OFF" ;
VAL_ 316 VDC13C_6_7_STBY_PREVIEW_VDC 1 "PREVIEW_VDC" 0 "NORMAL_VDC" ;
VAL_ 316 VDC13C_5_7_ACTIVATE_TSM 1 "CONTROL" 0 "NOT_CONTROL" ;
VAL_ 316 VDC13C_4_7_ACTIVATE_RMI 1 "CONTROL" 0 "NOT_CONTROL" ;
VAL_ 316 VDC13C_3_7_ACTIVATE_VECTARING 1 "ACTIVE" 0 "NON_ACTIVE" ;
VAL_ 316 VDC13C_2_7_STATE_ACTIVATE_HSA 1 "ACTIVE" 0 "NON_ACTIVE" ;
VAL_ 316 VDC13C_1_4_ACTIVE_BRAKEHOLD 1 "HOLD" 0 "RELEASE" ;
VAL_ 316 VDC13C_1_5_PROHIBIT_BRAKEHOLD 1 "PROHIBIT" 0 "PERMIT" ;
VAL_ 316 VDC13C_1_6_BRAKELAMP_RELAY 1 "ON" 0 "OFF" ;
VAL_ 316 VDC13C_1_7_STATUS_BRAKELAMP 1 "W/C>0MPa_and_ID160_B2b4=1" 0 "TURN_OFF" ;
VAL_ 315 VDC13B_1_4_BRAKE_TYPE 1 "ACTIVE_BOOSTER" 0 "VDC" ;
VAL_ 315 VDC13B_1_5_REQ_ENG_TRQ_DOWN 1 "REQ" 0 "NON_REQ" ;
VAL_ 315 VDC13B_1_6_REQ_ENG_TRQ_UP 1 "REQ" 0 "NON_REQ" ;
VAL_ 315 VDC13B_1_7_PROHIBIT_FUEL_CUT 1 "PROHIBIT" 0 "PERMIT" ;
VAL_ 313 VDC139_7_4_FAIL_PRESSURE_SSR 1 "NORMAL" 0 "FAIL" ;
VAL_ 313 VDC139_7_5_STATUS_EPB 7 "No_difinition" 6 "AVH_OPERATE" 5 "DYNAMIC PARKING" 4 "RELEASING" 3 "OPERATING" 2 "OPERATE" 1 "RELEASE" 0 "ERROR" ;
VAL_ 313 VDC139_4_0_HDC_STATUS 3 "Uncertain(SYS_OFF)" 2 "SYS_ACTIVE" 1 "SYS_WAIT" 0 "SYS_OFF" ;
VAL_ 313 VDC139_4_2_BRAKELAMPSW 1 "ON" 0 "OFF" ;
VAL_ 313 VDC139_4_3_FAIL_BRAKELAMPSW 1 "NORMAL" 0 "FAIL" ;
VAL_ 313 VDC139_4_4_ACTIVATE_ABS 1 "ACTIVE" 0 "NON_ACTIVE" ;
VAL_ 313 VDC139_4_5_ACTIVATE_TCS 1 "ACTIVE" 0 "NON_ACTIVE" ;
VAL_ 313 VDC139_4_6_CONT_OVER_STR 1 "control" 0 "NON_Control" ;
VAL_ 313 VDC139_4_7_CONT_UNDER_STR 1 "control" 0 "NON_Control" ;
VAL_ 313 VDC139_3_5_FAIL_VDC_SSR 1 "NORMAL" 0 "FAIL" ;
VAL_ 313 VDC139_3_6_FAIL_SPD_SSR_FHI 1 "NORMAL" 0 "FAIL" ;
VAL_ 313 VDC139_3_7_FAIL_ABS_SYS 1 "NORMAL" 0 "FAIL" ;
VAL_ 313 VDC139_1_4_FAIL_HDC_SYS 1 "NORMAL" 0 "FAIL" ;
VAL_ 313 VDC139_1_5_VEHICLE_HIGHT 2 "STANDARD" 1 "OBK" 0 "NON" ;
VAL_ 313 VDC139_1_7_REPROGRAMING 1 "STOP_Diag&COMM" 0 "NORMAL" ;
VAL_ 312 VDC138_1_4_ACTIVE_LDP 1 "ACTIVE" 0 "NON_ACTIVE" ;
VAL_ 312 VDC138_1_5_PROHIBIT_LDP 1 "PROHIBIT" 0 "PERMIT" ;
VAL_ 312 VDC138_1_6_VDC_SMALL_MARGIN 1 "SMALL MARGIN" 0 "NOMAL" ;
VAL_ 312 VDC138_1_7_DETECT_REAR_SLIP 1 "CONTROL" 0 "NOT_CONTROL" ;
VAL_ 952 CCU3B8_6_0_ACPANEL_STEER_H_LINK 3 "" 2 "" 1 "SW Push Event" 0 "invalid" ;
VAL_ 952 CCU3B8_5_6_ACPANEL_SEAT_H_LINK_P 3 "" 2 "" 1 "SW Push Event" 0 "invalid" ;
VAL_ 952 CCU3B8_5_4_ACPANEL_SEAT_H_LINK_D 3 "" 2 "" 1 "SW Push Event" 0 "invalid" ;
VAL_ 952 CCU3B8_4_3_ACPANEL_SEAT_V_TEMP_P 3 "Not Operation" 2 "Mild" 1 "Strong" 0 "Normal" ;
VAL_ 952 CCU3B8_4_0_ACPANEL_SEAT_V_TEMP_D 3 "Not Operation" 2 "Mild" 1 "Strong" 0 "Normal" ;
VAL_ 952 CCU3B8_3_7_ACN_CSTM_REQ 1 "required" 0 "NOT_required" ;
VAL_ 952 CCU3B8_3_3_ACPANEL_SEAT_H_TEMP_P 3 "Not Operation" 2 "Mild" 1 "Strong" 0 "Normal" ;
VAL_ 952 CCU3B8_3_0_ACPANEL_SEAT_H_TEMP_D 3 "Not Operation" 2 "Mild" 1 "Strong" 0 "Normal" ;
VAL_ 952 CCU3B8_2_0_ACPANEL_FAN_ONLY_SW 3 "" 2 "" 1 "SW Push Event" 0 "invalid" ;
VAL_ 952 CCU3B8_2_1_ACPANEL_INNER_AIR 3 "Undefind" 2 "Outside Air" 1 "Recirculation" 0 "invalid" ;
VAL_ 952 CCU3B8_1_6_ACPANEL_AUTO_ECO_SW 3 "" 2 "" 1 "SW Push Event" 0 "invalid" ;
VAL_ 952 CCU3B8_1_4_STEER_HEAT_SW 3 "" 2 "" 1 "SW Push Event" 0 "invalid" ;
VAL_ 1712 CCU6B0_7_0_AIL_CSTM_PRS_REQ 1 "required" 0 "NOT_required" ;
VAL_ 1712 CCU6B0_7_1_AIL_RENDER_REQ 5 "CUSTOM" 4 "DR_MD_Linkage" 3 "PAT_D" 2 "PAT_C" 1 "PAT_B" 0 "PAT_A" ;
VAL_ 1712 CCU6B0_3_0_AIL_ADAS_VEH_DIS_REQ 1 "ON" 0 "OFF" ;
VAL_ 1712 CCU6B0_3_1_AIL_ADAS_LANE_DEV_REQ 1 "ON" 0 "OFF" ;
VAL_ 1712 CCU6B0_3_2_AIL_ADAS_FT_CROSS_REQ 1 "ON" 0 "OFF" ;
VAL_ 1712 CCU6B0_3_3_AIL_ADAS_HANDS_FR_REQ 1 "ON" 0 "OFF" ;
VAL_ 1712 CCU6B0_2_0_AIL_WEL_FOL_REQ 1 "ON" 0 "OFF" ;
VAL_ 1712 CCU6B0_2_1_AIL_ADAS_EXP_REQ 1 "ON" 0 "OFF" ;
VAL_ 1712 CCU6B0_2_2_AIL_NOTIFI_EXP_REQ 1 "ON" 0 "OFF" ;
VAL_ 1712 CCU6B0_2_3_AIL_AIR_CON_EXP_REQ 1 "ON" 0 "OFF" ;
VAL_ 1712 CCU6B0_1_4_AIL_CUSTOM_REQ 1 "required" 0 "NOT_required" ;
VAL_ 1712 CCU6B0_1_5_AIL_CUSTOM_RESET_REQ 1 "required" 0 "NOT_required" ;
VAL_ 1712 CCU6B0_1_6_AIL_ON_OFF_REQ 1 "ON" 0 "OFF" ;
VAL_ 1710 CCU6AE_2_4_DEST_PRD_NUM 21 "Reserve" 20 "Reserve" 19 "Reserve" 18 "Reserve" 17 "Reserve" 16 "Reserve" 9 "Reserve" 8 "Reserve" 7 "Reserve" 6 "STANDARD" 5 "Europe" 4 "China" 3 "Australia" 2 "DOM" 1 "US_CANADA" 0 "Undefind" ;
VAL_ 1710 CCU6AE_2_2_VDC_SW_INFO 2 "ON_SW" 1 "OFF_SW" 0 "NOT_operation" ;
VAL_ 1710 CCU6AE_2_0_ISS_SW_INFO 1 "ON" 0 "OFF" ;
VAL_ 1709 CCU6AD_7_0_DMS_SET_REQ 1 "required" 0 "NOT required" ;
VAL_ 1709 CCU6AD_7_1_DP_POPUP_RES 3 "failure" 2 "success" 1 "on_display" 0 "no_process" ;
VAL_ 1709 CCU6AD_6_3_EYE_MONI_BLUE_IND_SET 1 "ON" 0 "OFF" ;
VAL_ 1709 CCU6AD_6_2_EYE_MONI_GRE_IND_SET 1 "ON" 0 "OFF" ;
VAL_ 1709 CCU6AD_6_1_EYE_MONI_YEL_IND_SET 1 "ON" 0 "OFF" ;
VAL_ 1709 CCU6AD_6_0_EYE_MONI_RED_IND_SET 1 "ON" 0 "OFF" ;
VAL_ 1709 CCU6AD_5_0_DP_OPERATION_FLAG 15 "process_stop" 14 "Reserve" 13 "user_switch_require" 12 "Reserve" 11 "user_delete" 10 "Reserve" 9 "user_register_complete" 8 "user_register_ongoing" 7 "Reserve" 6 "SMT_delete" 5 "SMT_register" 4 "DKY_delete" 3 "DKY_register" 2 "IPMS_delete" 1 "IPMS_register" 0 "default" ;
VAL_ 1709 CCU6AD_5_4_DP_OPERATION_NO 15 "all_ID" 14 "Guest" 13 "Reserve" 12 "Reserve" 11 "Reserve" 10 "Reserve" 9 "Reserve" 8 "Reserve" 7 "No.7" 6 "No.6" 5 "No.5" 4 "No.4" 3 "No.3" 2 "No.2" 1 "No.1" 0 "default" ;
VAL_ 1709 CCU6AD_4_7_DP_CCU_FAIL 1 "FAIL" 0 "NORMAL" ;
VAL_ 1709 CCU6AD_4_3_ALERT_BUZZ_REQ 3 "Large" 2 "Middle" 1 "Small" 0 "NOT_required" ;
VAL_ 1709 CCU6AD_4_0_ALERT_VOL_LEVEL_SET 3 "Large" 2 "Middle" 1 "Small" 0 "NOT_required" ;
VAL_ 1709 CCU6AD_3_2_PREC_CAR_START_VOL 3 "ON_Sound" 2 "ON_Buzzer" 1 "OFF" 0 "NOT_required" ;
VAL_ 1709 CCU6AD_3_0_PREC_CAR_SIG_VOL_SET 2 "ON" 1 "OFF" 0 "NOT_required" ;
VAL_ 1709 CCU6AD_2_3_MET_TEMP_UNIT_SET 2 "degF" 1 "degC" 0 "NOT_required" ;
VAL_ 1709 CCU6AD_2_0_UNIT_SET 6 "miles_MPH_kWhpermiles" 5 "miles_MPH_Whpermiles" 4 "miles_MPH_milesperkWh" 3 "km_kmh_kWhper100km" 2 "km_kmh_kmperWhkm" 1 "km_kmh_kmperkWh" 0 "NOT_required" ;
VAL_ 1709 CCU6AD_1_4_DP_DKY_OPERATION_NO 15 "No.15" 14 "No.14" 13 "No.13" 12 "No.12" 11 "No.11" 10 "No.10" 9 "No.9" 8 "No.8" 7 "No.7" 6 "No.6" 5 "No.5" 4 "No.4" 3 "No.3" 2 "No.2" 1 "No.1" 0 "initial" ;
VAL_ 1708 CCU6AC_7_0_REAR_REMIND_SET 3 "Reserve" 2 "ON" 1 "OFF" 0 "NOT required" ;
VAL_ 1708 CCU6AC_6_0_SIDIRVE_SEL_INFO 6 "S" 5 "ECO-C" 4 "I_Normal" 3 "X_DEEPSNOWMUD" 2 "S_sharp" 1 "X_SNOWDIRT" 0 "NOT_required" ;
VAL_ 1708 CCU6AC_5_6_SHIFT_DISP_SET 2 "ON" 1 "OFF" 0 "NOT_required" ;
VAL_ 1708 CCU6AC_5_4_INIT_DIRECT_SET 2 "ON" 1 "OFF" 0 "NOT_required" ;
VAL_ 1708 CCU6AC_5_2_GOOD_BYE_SET 2 "ON" 1 "OFF" 0 "NOT_required" ;
VAL_ 1708 CCU6AC_5_0_WELCOME_SET 2 "ON" 1 "OFF" 0 "NOT_required" ;
VAL_ 1708 CCU6AC_4_5_COMPASS_DISP_SET 5 "Fail" 4 "Initial" 3 "Pattern3" 2 "Pattern2" 1 "Pattern1" 0 "OFF" ;
VAL_ 1708 CCU6AC_4_3_ILL_DOWN_PUSH_SIG 1 "EVENT" 0 "NOT_requried" ;
VAL_ 1708 CCU6AC_4_2_ILL_UP_PUSH_SIG 1 "EVENT" 0 "NOT_requried" ;
VAL_ 1708 CCU6AC_4_0_UI_SW_STATE_SIG 3 "Night" 2 "Day" 1 "Auto" 0 "Initial" ;
VAL_ 1708 CCU6AC_2_7_BRIGHT_SW_SIG 2 "OFF" 1 "ON" 0 "NOT_required" ;
VAL_ 1708 CCU6AC_1_7_SET_INIT_REQ 1 "required" 0 "NOT_required" ;
VAL_ 1707 CCU6AB_7_3_REQ_RESET_CSTM_TPM 1 "required" 0 "NOT required" ;
VAL_ 1707 CCU6AB_7_2_TPM_CSTM_CHG_REQ 1 "required" 0 "NOT required" ;
VAL_ 1707 CCU6AB_7_0_CSTM_TIRE_UNIT 1 "kPa" 0 "PSi" ;
VAL_ 1707 CCU6AB_6_3_REQ_RESET_CSTM_AHL 1 "required" 0 "NOT_required" ;
VAL_ 1707 CCU6AB_6_2_SRH_CSTM_CHG_REQ 1 "required" 0 "NOT_required" ;
VAL_ 1707 CCU6AB_6_0_SRH_CSTM_CHG_SET 1 "ON" 0 "OFF" ;
VAL_ 1707 CCU6AB_5_0_SEATAWAY_DST_CSTM 3 "Min" 2 "Mid" 1 "Max" 0 "NOT_required" ;
VAL_ 1707 CCU6AB_5_2_DRIVER_POSI_REQ 2 "Recovery" 1 "Save" 0 "NOT_required" ;
VAL_ 1707 CCU6AB_5_6_OCCUPANT_DETECT_REQ 3 "Reserve" 2 "Reserve" 1 "required" 0 "NOT required" ;
VAL_ 1707 CCU6AB_4_6_AFOLD_SW_MIR_SW 1 "required" 0 "NOT_required" ;
VAL_ 1707 CCU6AB_4_2_MIR_DIRECTION_MIR_SW 4 "Right" 3 "Left" 2 "Down" 1 "Up" 0 "NOT_required" ;
VAL_ 1707 CCU6AB_4_0_MIR_SELECT_LR_MIR_SW 2 "Right" 1 "Left" 0 "NOT_required" ;
VAL_ 1707 CCU6AB_3_0_PRG_OPENER_SW 1 "SW_Press" 0 "SW_NOT_Press" ;
VAL_ 1707 CCU6AB_3_1_PRG_MEM_CHG_REQ 1 "required" 0 "NOT_required" ;
VAL_ 1707 CCU6AB_3_2_PRG_HF_CHG_REQ 1 "required" 0 "NOT_required" ;
VAL_ 1707 CCU6AB_3_6_MIR_RTILT_R_CSTM 1 "required" 0 "NOT required" ;
VAL_ 1707 CCU6AB_3_7_MIR_RTILT_L_CSTM 1 "required" 0 "NOT required" ;
VAL_ 1707 CCU6AB_2_6_WASH_CAR_MODE_REQ 1 "required" 0 "NOT_required" ;
VAL_ 1707 CCU6AB_2_4_SHUT_DOWN_MODE_REQ 1 "required" 0 "NOT_required" ;
VAL_ 1707 CCU6AB_2_2_PET_MODE_SWITCH_REQ 1 "required" 0 "NOT_required" ;
VAL_ 1707 CCU6AB_2_0_POW_ON_FIX_MODE_REQ 1 "required" 0 "NOT_required" ;
VAL_ 1707 CCU6AB_1_7_CECU_CSTM_RESET_REQ 1 "required" 0 "NOT_required" ;
VAL_ 1706 CCU6AA_5_0_WINDOW_LOCK_SET_REQ 1 "required" 0 "NOT_required" ;
VAL_ 1706 CCU6AA_5_2_DOOR_LINK_SET_REQ 1 "required" 0 "NOT_required" ;
VAL_ 1706 CCU6AA_5_4_BULK_TURN_ON_REQ 1 "required" 0 "NOT_required" ;
VAL_ 1706 CCU6AA_5_6_WIPER_SERV_MODE_REQ 3 "Reserve" 2 "ON" 1 "OFF" 0 "NOT required" ;
VAL_ 1706 CCU6AA_4_0_ITMITT_SENSITIVE_REQ 21 "Reserve" 20 "Reserve" 19 "Reserve" 18 "Reserve" 17 "Reserve" 16 "Reserve" 9 "Reserve" 8 "Reserve" 7 "Reserve" 6 "Reserve" 5 "Reserve" 4 "4" 3 "3" 2 "2" 1 "1" 0 "NOT required" ;
VAL_ 1706 CCU6AA_4_4_REAR_WIPER_SET_REQ 3 "Hi" 2 "Lo" 1 "OFF" 0 "NOT_required" ;
VAL_ 1706 CCU6AA_3_0_WELCOME_RIDEON_REQ 7 "Reserve" 6 "Reserve" 5 "Reserve" 4 "30sec" 3 "20sec" 2 "10sec" 1 "OFF" 0 "NOT required" ;
VAL_ 1706 CCU6AA_3_3_WELCOME_GETOFF_REQ 7 "Reserve" 6 "90sec" 5 "60sec" 4 "30sec" 3 "20sec" 2 "10sec" 1 "OFF" 0 "NOT required" ;
VAL_ 1706 CCU6AA_2_0_WIPER_HEADLAMP_REQ 3 "Reserve" 2 "ON" 1 "OFF" 0 "NOT required" ;
VAL_ 1706 CCU6AA_1_4_WIUL_CUSTOM_REQ 2 "ON" 1 "OFF" 0 "NOT_required" ;
VAL_ 1706 CCU6AA_1_6_WAL_CUSTOM_REQ 2 "ON" 1 "OFF" 0 "NOT_required" ;
VAL_ 1704 CCU6A8_7_5_TRQ_CHG_MODE_SET 3 "Blink" 2 "ON" 1 "OFF" 0 "NOT_required" ;
VAL_ 1704 CCU6A8_7_3_ADAPT_DEC_CHG_REQ 3 "Blink" 2 "ON" 1 "OFF" 0 "NOT_required" ;
VAL_ 1704 CCU6A8_7_0_DEC_SELECT_REQ_B 3 "Hi" 2 "Mid" 1 "Lo" 0 "NOT_required" ;
VAL_ 1704 CCU6A8_6_5_DEC_SELECT_REQ_D 3 "Hi" 2 "Mid" 1 "Lo" 0 "NOT_required" ;
VAL_ 1704 CCU6A8_6_2_DEC_SELECT_REQ_ALL 3 "Hi" 2 "Mid" 1 "Lo" 0 "NOT_required" ;
VAL_ 1704 CCU6A8_6_0_DEC_SELECT_REQ_IND 3 "Blink" 2 "ON" 1 "OFF" 0 "NOT_required" ;
VAL_ 1704 CCU6A8_5_2_TOWING_MODE_REQ 2 "ON" 1 "OFF" 0 "NOT_required" ;
VAL_ 1704 CCU6A8_5_0_FACTORY_MODE_STATE 3 "Blink" 2 "ON" 1 "OFF" 0 "NOT_required" ;
VAL_ 1704 CCU6A8_4_2_TRIP_RESET_REQ 1 "required" 0 "NOT_required" ;
VAL_ 1704 CCU6A8_4_0_TRIP_SWITCH_REQ 3 "TRIP B" 2 "TRIP A" 1 "ODO" 0 "NOT required" ;
VAL_ 1704 CCU6A8_3_0_DOW_SFT_POS_SET 1 "required" 0 "NOT required" ;
VAL_ 1704 CCU6A8_2_6_DOW_SET 1 "required" 0 "NOT required" ;
VAL_ 1704 CCU6A8_2_4_RCTA_SET 1 "required" 0 "NOT required" ;
VAL_ 1704 CCU6A8_2_2_BSD_LCA_2ND_SET 1 "required" 0 "NOT required" ;
VAL_ 1704 CCU6A8_2_0_SRVD_SET 1 "required" 0 "NOT required" ;
VAL_ 1704 CCU6A8_1_6_RCR_CSTM_RESET_REQ 1 "required" 0 "NOT required" ;
VAL_ 1704 CCU6A8_1_4_BEV_CSTM_RESET_REQ 1 "required" 0 "NOT required" ;
VAL_ 1146 CCU47A_24_0_MRM_OPERATION_INFO 6 "MRM Finish" 5 "Cancel Restart" 4 "Execute Restart" 3 "Pause" 2 "Cancel Start" 1 "Execute Start" 0 "NOT pushed" ;
VAL_ 1146 CCU47A_21_2_DATA_COLLECT_LOC 3 "Reserve" 2 "ON" 1 "OFF" 0 "NOT required" ;
VAL_ 1146 CCU47A_21_0_DATA_COLLECT_IMAGE 3 "Reserve" 2 "ON" 1 "OFF" 0 "NOT required" ;
VAL_ 1146 CCU47A_20_6_ADDON_CSTM 3 "Reserve" 2 "ON" 1 "OFF" 0 "NOT required" ;
VAL_ 1146 CCU47A_20_4_EYE_LANE_SELECT_CONT 3 "Reserve" 2 "ON" 1 "OFF" 0 "NOT required" ;
VAL_ 1146 CCU47A_20_2_DATA_COLLECT_CSTM 3 "Reserve" 2 "ON" 1 "OFF" 0 "NOT required" ;
VAL_ 1146 CCU47A_20_0_V2N_CSTM 3 "Reserve" 2 "ON" 1 "OFF" 0 "NOT required" ;
VAL_ 1146 CCU47A_19_6_PROPOSAL_HMI_CSTM 3 "Reserve" 2 "ON" 1 "OFF" 0 "NOT required" ;
VAL_ 1146 CCU47A_19_4_EYE_LANE_SELECT_CSTM 3 "Reserve" 2 "Left" 1 "Right" 0 "NOT required" ;
VAL_ 1146 CCU47A_19_2_EYE_GREEN_LIGHT_CSTM 3 "Reserve" 2 "ON" 1 "OFF" 0 "NOT required" ;
VAL_ 1146 CCU47A_19_0_LSW_CSTM 3 "Reserve" 2 "ON" 1 "OFF" 0 "NOT required" ;
VAL_ 1146 CCU47A_16_0_ISA_IACC_ACCEPT_CONT 3 "Reserve" 2 "ON" 1 "OFF" 0 "NOT required" ;
VAL_ 1146 CCU47A_15_0_SLWF_OFFSET_OV50 31 "Reserve" 30 "Reserve" 29 "Reserve" 28 "Reserve" 27 "Reserve" 26 "Reserve" 25 "Reserve" 24 "Reserve" 23 "Reserve" 22 "Reserve" 21 "10" 20 "9" 19 "8" 18 "7" 17 "6" 16 "5" 15 "4" 14 "3" 13 "2" 12 "1" 11 "0" 10 "-1" 9 "-2" 8 "-3" 7 "-4" 6 "-5" 5 "-6" 4 "-7" 3 "-8" 2 "-9" 1 "-10" 0 "NOT required" ;
VAL_ 1146 CCU47A_14_0_SLWF_OFFSET_U50 31 "Reserve" 30 "Reserve" 29 "Reserve" 28 "Reserve" 27 "Reserve" 26 "Reserve" 25 "Reserve" 24 "Reserve" 23 "Reserve" 22 "Reserve" 21 "10" 20 "9" 19 "8" 18 "7" 17 "6" 16 "5" 15 "4" 14 "3" 13 "2" 12 "1" 11 "0" 10 "-1" 9 "-2" 8 "-3" 7 "-4" 6 "-5" 5 "-6" 4 "-7" 3 "-8" 2 "-9" 1 "-10" 0 "NOT required" ;
VAL_ 1146 CCU47A_13_0_ISA_IACC_OFFSET_OV50 31 "Reserve" 30 "Reserve" 29 "Reserve" 28 "Reserve" 27 "Reserve" 26 "Reserve" 25 "Reserve" 24 "Reserve" 23 "Reserve" 22 "Reserve" 21 "10" 20 "9" 19 "8" 18 "7" 17 "6" 16 "5" 15 "4" 14 "3" 13 "2" 12 "1" 11 "0" 10 "-1" 9 "-2" 8 "-3" 7 "-4" 6 "-5" 5 "-6" 4 "-7" 3 "-8" 2 "-9" 1 "-10" 0 "NOT required" ;
VAL_ 1146 CCU47A_12_0_ISA_IACC_OFFSET_U50 31 "Reserve" 30 "Reserve" 29 "Reserve" 28 "Reserve" 27 "Reserve" 26 "Reserve" 25 "Reserve" 24 "Reserve" 23 "Reserve" 22 "Reserve" 21 "10" 20 "9" 19 "8" 18 "7" 17 "6" 16 "5" 15 "4" 14 "3" 13 "2" 12 "1" 11 "0" 10 "-1" 9 "-2" 8 "-3" 7 "-4" 6 "-5" 5 "-6" 4 "-7" 3 "-8" 2 "-9" 1 "-10" 0 "NOT required" ;
VAL_ 1146 CCU47A_11_5_SLWF_OFS_CONT 3 "Reserve" 2 "ON" 1 "OFF" 0 "NOT required" ;
VAL_ 1146 CCU47A_11_3_ISA_IACC_OFS_CONT 3 "Reserve" 2 "ON" 1 "OFF" 0 "NOT required" ;
VAL_ 1146 CCU47A_11_0_ISA_IACC_ACCEPT_CSTM 7 "Reserve" 6 "Reserve" 5 "Reserve" 4 "Reserve" 3 "Approval" 2 "Auto" 1 "Manual" 0 "NOT required" ;
VAL_ 1146 CCU47A_10_6_EYE_LOADSIGNS_SYS 3 "Reserve" 2 "ON" 1 "OFF" 0 "NOT required" ;
VAL_ 1146 CCU47A_10_4_SLWF_CSTM 3 "Reserve" 2 "ON" 1 "OFF" 0 "NOT required" ;
VAL_ 1146 CCU47A_10_2_SIGN_SWITCH_SOUND 3 "Reserve" 2 "ON" 1 "OFF" 0 "NOT required" ;
VAL_ 1146 CCU47A_10_0_EYE_LOADSIGNS_ADD 3 "Reserve" 2 "ON" 1 "OFF" 0 "NOT required" ;
VAL_ 1146 CCU47A_6_6_TEMP_OFF_REQ 1 "required" 0 "NOT required" ;
VAL_ 1146 CCU47A_6_2_CSTM_SONNER 3 "Reserve" 2 "ON" 1 "OFF" 0 "NOT required" ;
VAL_ 1146 CCU47A_6_0_CSTM_RAB 3 "Reserve" 2 "ON" 1 "OFF" 0 "NOT required" ;
VAL_ 1146 CCU47A_5_7_SNR_CSTM_RESET_REQ 1 "required" 0 "NOT required" ;
VAL_ 1146 CCU47A_5_6_ADAS_CSTM_RESET_REQ 1 "required" 0 "NOT required" ;
VAL_ 1146 CCU47A_5_2_PED_RAB_TIMING 7 "Reserve" 6 "Reserve" 5 "Reserve" 4 "Reserve" 3 "Far" 2 "Normal" 1 "Near" 0 "NOT required" ;
VAL_ 1146 CCU47A_5_0_PED_RAB_ON_OFF 3 "Reserve" 2 "ON" 1 "OFF" 0 "NOT required" ;
VAL_ 1146 CCU47A_3_0_EYE_CSTM_CHG_REQ_47A 1 "required" 0 "NOT required" ;
VAL_ 1145 CCU479_29_4_ACC_TGT_OPT_HIGHWAY 3 "Reserve" 2 "ON" 1 "OFF" 0 "NOT required" ;
VAL_ 1145 CCU479_29_2_ACC_TGT_OPT_SLOWDOWN 3 "Reserve" 2 "ON" 1 "OFF" 0 "NOT required" ;
VAL_ 1145 CCU479_29_0_ACC_TGT_OPT_STOP 3 "Reserve" 2 "ON" 1 "OFF" 0 "NOT required" ;
VAL_ 1145 CCU479_28_2_EYE_ACC_FUNC_CONT 3 "Reserve" 2 "ON" 1 "OFF" 0 "NOT required" ;
VAL_ 1145 CCU479_28_0_ACC_TARGET_OPT_CSTM 3 "Reserve" 2 "ON" 1 "OFF" 0 "NOT required" ;
VAL_ 1145 CCU479_27_5_EYE_ACC_SYS_CSTM 3 "Reserve" 2 "ON" 1 "OFF" 0 "NOT required" ;
VAL_ 1145 CCU479_27_3_ACC_OVERTAKE_CSTM 3 "Reserve" 2 "ON" 1 "OFF" 0 "NOT required" ;
VAL_ 1145 CCU479_27_0_EYE_ACC_CONT_CSTM 7 "Reserve" 6 "Reserve" 5 "Reserve" 4 "Dynamic" 3 "Standard" 2 "Comfort" 1 "Eco" 0 "NOT required" ;
VAL_ 1145 CCU479_24_4_EYE_LKS_OPT_OFFSET 3 "Reserve" 2 "ON" 1 "OFF" 0 "NOT required" ;
VAL_ 1145 CCU479_24_2_EYE_LKS_OPT_NAVI 3 "Reserve" 2 "ON" 1 "OFF" 0 "NOT required" ;
VAL_ 1145 CCU479_24_0_EYE_LKS_OPT_AUTOPASS 3 "Reserve" 2 "ON" 1 "OFF" 0 "NOT required" ;
VAL_ 1145 CCU479_23_2_EYE_LKS_OPT_CONT 3 "Reserve" 2 "ON" 1 "OFF" 0 "NOT required" ;
VAL_ 1145 CCU479_23_0_EYE_ACTIVE_LKS_CSTM 3 "Reserve" 2 "ON" 1 "OFF" 0 "NOT required" ;
VAL_ 1145 CCU479_21_4_EYE_ELK_CTRL_CSTM 3 "Reserve" 2 "ON" 1 "OFF" 0 "NOT required" ;
VAL_ 1145 CCU479_21_2_EYE_ELK_VIB_CSTM 3 "Reserve" 2 "ON" 1 "OFF" 0 "NOT required" ;
VAL_ 1145 CCU479_21_0_EYE_ELK_SOUND_CSTM 3 "Reserve" 2 "ON" 1 "OFF" 0 "NOT required" ;
VAL_ 1145 CCU479_20_6_ELK_ASSISTTYPE_CONT 3 "Reserve" 2 "ON" 1 "OFF" 0 "NOT required" ;
VAL_ 1145 CCU479_20_4_EYE_LDW_TIMING_CONT 3 "Reserve" 2 "ON" 1 "OFF" 0 "NOT required" ;
VAL_ 1145 CCU479_20_2_LDW_OFF_EXE 3 "Reserve" 2 "ON" 1 "OFF" 0 "NOT required" ;
VAL_ 1145 CCU479_20_0_EYE_ELK_CSTM 3 "Reserve" 2 "ON" 1 "OFF" 0 "NOT required" ;
VAL_ 1145 CCU479_19_6_LDP_TARGET_SIDE_VHCL 3 "Reserve" 2 "ON" 1 "OFF" 0 "NOT required" ;
VAL_ 1145 CCU479_19_4_LDP_TARGET_SIDE_OBJ 3 "Reserve" 2 "ON" 1 "OFF" 0 "NOT required" ;
VAL_ 1145 CCU479_19_2_LDP_TARGET_DASHLINE 3 "Reserve" 2 "ON" 1 "OFF" 0 "NOT required" ;
VAL_ 1145 CCU479_19_0_LDP_TARGET_SOLIDLINE 3 "Reserve" 2 "ON" 1 "OFF" 0 "NOT required" ;
VAL_ 1145 CCU479_18_6_LDP_TARGET_CONT 3 "Reserve" 2 "ON" 1 "OFF" 0 "NOT required" ;
VAL_ 1145 CCU479_18_4_LANE_DEP_LDP_CSTM 3 "Reserve" 2 "ON" 1 "OFF" 0 "NOT required" ;
VAL_ 1145 CCU479_18_2_LANE_DEP_LDW_VI_CSTM 3 "Reserve" 2 "ON" 1 "OFF" 0 "NOT required" ;
VAL_ 1145 CCU479_18_0_LANE_DEP_LDW_SO_CSTM 3 "Reserve" 2 "ON" 1 "OFF" 0 "NOT required" ;
VAL_ 1145 CCU479_17_5_LANE_DEP_LDW_CONT 3 "Reserve" 2 "ON" 1 "OFF" 0 "NOT required" ;
VAL_ 1145 CCU479_17_2_EYE_LDW_TIMING_CSTM 7 "Reserve" 6 "Reserve" 5 "Reserve" 4 "Reserve" 3 "Early" 2 "Late" 1 "Normal" 0 "NOT required" ;
VAL_ 1145 CCU479_17_0_LANE_DEPARTURE_CSTM 3 "Reserve" 2 "ON" 1 "OFF" 0 "NOT required" ;
VAL_ 1145 CCU479_16_2_EYE_MIS_AT_BACK_CONT 3 "Reserve" 2 "ON" 1 "OFF" 0 "NOT required" ;
VAL_ 1145 CCU479_16_0_EYE_SAFTY_MODE_SENS 3 "Reserve" 2 "ON" 1 "OFF" 0 "NOT required" ;
VAL_ 1145 CCU479_15_6_FCTI_NOTICE_CONT 3 "Reserve" 2 "ON" 1 "OFF" 0 "NOT required" ;
VAL_ 1145 CCU479_15_4_FCW_TYPE_CONT 3 "Reserve" 2 "ON" 1 "OFF" 0 "NOT required" ;
VAL_ 1145 CCU479_15_2_FCW_TIMING_CONT 3 "Reserve" 2 "ON" 1 "OFF" 0 "NOT required" ;
VAL_ 1145 CCU479_15_0_BRAKE_TIMING_CONT 3 "Reserve" 2 "ON" 1 "OFF" 0 "NOT required" ;
VAL_ 1145 CCU479_14_5_FCW_OFF_EXE 3 "Reserve" 2 "ON" 1 "OFF" 0 "NOT required" ;
VAL_ 1145 CCU479_14_2_EYE_MIS_AT_BACK_LV 7 "Reserve" 6 "Reserve" 5 "Reserve" 4 "Reserve" 3 "High speed" 2 "Medium speed" 1 "Low speed" 0 "NOT required" ;
VAL_ 1145 CCU479_14_0_EYE_MIS_AT_BACK_CSTM 3 "Reserve" 2 "ON" 1 "OFF" 0 "NOT required" ;
VAL_ 1145 CCU479_13_2_FCTI_PULSE_CSTM 3 "Reserve" 2 "ON" 1 "OFF" 0 "NOT required" ;
VAL_ 1145 CCU479_13_0_FCTI_SOUND_CSTM 3 "Reserve" 2 "ON" 1 "OFF" 0 "NOT required" ;
VAL_ 1145 CCU479_12_4_EYE_SAFTY_MODE_LV 7 "Reserve" 6 "Reserve" 5 "Reserve" 4 "Reserve" 3 "High" 2 "Low" 1 "Normal" 0 "NOT required" ;
VAL_ 1145 CCU479_12_2_EYE_SAFTY_MODE_CSTM 3 "Reserve" 2 "ON" 1 "OFF" 0 "NOT required" ;
VAL_ 1145 CCU479_12_0_FCTI_CONT_CSTM 3 "Reserve" 2 "ON" 1 "OFF" 0 "NOT required" ;
VAL_ 1145 CCU479_11_2_FCW_TYPE_PULSE_CSTM 3 "Reserve" 2 "ON" 1 "OFF" 0 "NOT required" ;
VAL_ 1145 CCU479_11_0_FCW_TYPE_SOUND_CSTM 3 "Reserve" 2 "ON" 1 "OFF" 0 "NOT required" ;
VAL_ 1145 CCU479_10_5_FCW_TIMING_CSTM 7 "Reserve" 6 "Reserve" 5 "Reserve" 4 "Reserve" 3 "Far" 2 "Near" 1 "Normal" 0 "NOT required" ;
VAL_ 1145 CCU479_10_2_BRAKE_TIMING_CSTM 7 "Reserve" 6 "Reserve" 5 "Reserve" 4 "Reserve" 3 "Reserve" 2 "Far" 1 "Normal" 0 "NOT required" ;
VAL_ 1145 CCU479_10_0_EYE_P_CR_CSTM 3 "Reserve" 2 "ON" 1 "OFF" 0 "NOT required" ;
VAL_ 1145 CCU479_6_4_SUPPRESS_SPD_TGT_SLO 3 "Reserve" 2 "ON" 1 "OFF" 0 "NOT required" ;
VAL_ 1145 CCU479_6_2_SUPPRESS_SPD_TGT_SUR 3 "Reserve" 2 "ON" 1 "OFF" 0 "NOT required" ;
VAL_ 1145 CCU479_6_0_SUPPRESS_SPD_TGT_VEH 3 "Reserve" 2 "ON" 1 "OFF" 0 "NOT required" ;
VAL_ 1145 CCU479_5_5_ACTIVE_AVOIDANCE_LV 7 "Reserve" 6 "Reserve" 5 "Reserve" 4 "Reserve" 3 "High" 2 "Low" 1 "Normal" 0 "NOT required" ;
VAL_ 1145 CCU479_5_3_ACTIVE_AVOIDANCE 3 "Reserve" 2 "ON" 1 "OFF" 0 "NOT required" ;
VAL_ 1145 CCU479_5_0_SUPPRESS_SPEED_LEVEL 7 "Reserve" 6 "Reserve" 5 "Reserve" 4 "Reserve" 3 "High" 2 "Low" 1 "Normal" 0 "NOT required" ;
VAL_ 1145 CCU479_4_4_SUPPRESS_SPD_TGT_CONT 3 "Reserve" 2 "ON" 1 "OFF" 0 "NOT required" ;
VAL_ 1145 CCU479_4_2_SUPPRESS_SPEED_CSTM 3 "Reserve" 2 "ON" 1 "OFF" 0 "NOT required" ;
VAL_ 1145 CCU479_4_0_PDA_CSTM 3 "Reserve" 2 "ON" 1 "OFF" 0 "NOT required" ;
VAL_ 1145 CCU479_3_1_FAIL_CCU_TO_EYE 3 "Reserve" 2 "Reserve" 1 "FAIL" 0 "NORMAL" ;
VAL_ 1145 CCU479_3_0_CCU_VALID 1 "Valid" 0 "Invalid" ;
VAL_ 1144 CCU478_21_0_LAT_CHG_SET_TYPE 3 "Fail_Value" 2 "Time_Range_Type" 1 "Start_Time_Type" 0 "Initial_Value" ;
VAL_ 1144 CCU478_20_2_TIRE_SIZE 7 "21inch" 6 "20inch" 5 "19inch" 4 "18inch" 3 "17inch" 2 "16inch" 1 "15inch" 0 "Initial_Value" ;
VAL_ 1144 CCU478_20_0_TIRE_TYPE 3 "All_Terrain" 2 "Winter" 1 "Normal" 0 "Initial_Value" ;
VAL_ 1144 CCU478_19_2_SW_PFO_MOD_CHG 2 "Performance_Mode_Req" 1 "Normal_Mode_Req" 0 "No_Req" ;
VAL_ 1144 CCU478_19_0_DEP_TIM_CHG_FLG 3 "Fail_Value" 2 "Departure_Time_Setting_UnChanged" 1 "Departure_Time_Setting_Changed" 0 "Initial_Value" ;
VAL_ 1144 CCU478_15_7_DEP_TIM4_PER_FLG 1 "Performance_Mode" 0 "Initial_Value(Normal)" ;
VAL_ 1144 CCU478_15_5_DEP_TIM4_SW_STS 3 "Fail_Value" 2 "ON" 1 "OFF" 0 "Initial_Value(Non-timer)" ;
VAL_ 1144 CCU478_15_0_TIM4_DISP_ID 31 "Fail_Value" 4 "Disp_Seq_No_ID4" 3 "Disp_Seq_No_ID3" 2 "Disp_Seq_No_ID2" 1 "Disp_Seq_No_ID1" 0 "Initial_Value(Non-display)" ;
VAL_ 1144 CCU478_11_7_DEP_TIM3_PER_FLG 1 "Performance_Mode" 0 "Initial_Value(Normal)" ;
VAL_ 1144 CCU478_11_5_DEP_TIM3_SW_STS 3 "Fail_Value" 2 "ON" 1 "OFF" 0 "Initial_Value(Non-timer)" ;
VAL_ 1144 CCU478_11_0_TIM3_DISP_ID 31 "Fail_Value" 4 "Disp_Seq_No_ID4" 3 "Disp_Seq_No_ID3" 2 "Disp_Seq_No_ID2" 1 "Disp_Seq_No_ID1" 0 "Initial_Value(Non-display)" ;
VAL_ 1144 CCU478_7_7_DEP_TIM2_PER_FLG 1 "Performance_Mode" 0 "Initial_Value(Normal)" ;
VAL_ 1144 CCU478_7_5_DEP_TIM2_SW_STS 3 "Fail_Value" 2 "ON" 1 "OFF" 0 "Initial_Value(Non-timer)" ;
VAL_ 1144 CCU478_7_0_TIM2_DISP_ID 31 "Fail_Value" 4 "Disp_Seq_No_ID4" 3 "Disp_Seq_No_ID3" 2 "Disp_Seq_No_ID2" 1 "Disp_Seq_No_ID1" 0 "Initial_Value(Non-display)" ;
VAL_ 1144 CCU478_3_7_DEP_TIM1_PER_FLG 1 "Performance_Mode" 0 "Initial_Value(Normal)" ;
VAL_ 1144 CCU478_3_5_DEP_TIM1_SW_STS 3 "Fail_Value" 2 "ON" 1 "OFF" 0 "Initial_Value(Non-timer)" ;
VAL_ 1144 CCU478_3_0_TIM1_DISP_ID 31 "Fail_Value" 4 "Disp_Seq_No_ID4" 3 "Disp_Seq_No_ID3" 2 "Disp_Seq_No_ID2" 1 "Disp_Seq_No_ID1" 0 "Initial_Value(Non-display)" ;
VAL_ 1143 CCU477_28_2_TIM_CHG_CHG_FLG 3 "Fail _Value" 2 "Timer_Charging_Setting_UnChanged" 1 "Timer_Charging_Setting_Changed" 0 "Initial_Value" ;
VAL_ 1143 CCU477_28_0_TIM_CHG_ICON_DISP 3 "Fail_Value" 2 "OFF" 1 "ON" 0 "Initial_Value" ;
VAL_ 1143 CCU477_27_4_TIM_CHG_STATUS 15 "Fail_Value" 8 "Charging_Now(Reserved)" 7 "Time_Range_Type_Charging_End(Reserved)" 6 "Time_Range_Type_Charging_Start(Reserved)" 5 "Start_Time_Type_Charging_Start(Reserved)" 4 "Charging_End" 3 "Charging_Start" 2 "Timer_Charging_Standby" 1 "Non_Timer_Charging" 0 "Initial _Value" ;
VAL_ 1143 CCU477_27_1_DEP_TIM_PRE_CON_FLAG 7 "Fail_Value" 6 "Reserved" 5 "Reserved" 4 "Departure_Time" 3 "Start_AC" 2 "Start_Temp_Ctrl_Performance" 1 "Start_Temp_Ctrl_Normal" 0 "Initial_Value(OFF)" ;
VAL_ 1143 CCU477_27_0_TIM_CHG_PERM_FLAG 1 "Timer_Charging_Abled" 0 "Initial_Value (timer charging disabled)" ;
VAL_ 1143 CCU477_22_0_TIM4_CHG_SET_TYPE 3 "Fail_Value" 2 "Time_Range_Type" 1 "Start_Time_Type" 0 "Initial_Value" ;
VAL_ 1143 CCU477_21_5_TIM4_CHG_SW_STS 3 "Fail_Value" 2 "ON" 1 "OFF" 0 "Initial_Value(Non-timer)	" ;
VAL_ 1143 CCU477_21_0_TIM4_DISP_ID 31 "Fail_Value" 4 "Disp_Seq_No_ID4" 3 "Disp_Seq_No_ID3" 2 "Disp_Seq_No_ID2" 1 "Disp_Seq_No_ID1" 0 "Initial_Value(Non-display)	" ;
VAL_ 1143 CCU477_16_0_TIM3_CHG_SET_TYPE 3 "Fail_Value" 2 "Time_Range_Type" 1 "Start_Time_Type" 0 "Initial_Value" ;
VAL_ 1143 CCU477_15_5_TIM3_CHG_SW_STS 3 "Fail_Value" 2 "ON" 1 "OFF" 0 "Initial_Value(Non-timer)	" ;
VAL_ 1143 CCU477_15_0_TIM3_DISP_ID 31 "Fail_Value" 4 "Disp_Seq_No_ID4" 3 "Disp_Seq_No_ID3" 2 "Disp_Seq_No_ID2" 1 "Disp_Seq_No_ID1" 0 "Initial_Value(Non-display)	" ;
VAL_ 1143 CCU477_10_0_TIM2_CHG_SET_TYPE 3 "Fail_value" 2 "TimeRange_Type" 1 "StartTime_Type" 0 "Initial_value" ;
VAL_ 1143 CCU477_9_5_TIM2_CHG_SW_STS 3 "Fail_Value" 2 "ON" 1 "OFF" 0 "Initial_Value(Non-timer)	" ;
VAL_ 1143 CCU477_9_0_TIM2_DISP_ID 31 "Fail_Value" 4 "Disp_Seq_No_ID4" 3 "Disp_Seq_No_ID3" 2 "Disp_Seq_No_ID2" 1 "Disp_Seq_No_ID1" 0 "Initial_Value(Non-display)	" ;
VAL_ 1143 CCU477_4_0_TIM1_CHG_SET_TYPE 3 "Fail_Value" 2 "Time_Range_Type" 1 "Start_Time_Type" 0 "Initial_Value" ;
VAL_ 1143 CCU477_3_5_TIM1_CHG_SW_STS 3 "Fail_Value" 2 "ON" 1 "OFF" 0 "Initial_Value(Non-timer)	" ;
VAL_ 1143 CCU477_3_0_TIM1_DISP_ID 31 "Fail_Value" 4 "Disp_Seq_No_ID4" 3 "Disp_Seq_No_ID3" 2 "Disp_Seq_No_ID2" 1 "Disp_Seq_No_ID1" 0 "Initial_Value(Non-display)	" ;
VAL_ 1142 CCU476_17_2_SW_STOP_CHG 1 "ON" 0 "OFF" ;
VAL_ 1142 CCU476_17_1_SW_NORMAL_MOD_CHG 1 "押す" 0 "No signal" ;
VAL_ 1142 CCU476_17_0_SW_PWR_MOD_CHG 1 "押す" 0 "No signal" ;
VAL_ 1142 CCU476_16_4_AC_CUR_MAX_LIM_CHG 6 "8A" 5 "12A" 4 "16A" 3 "24A" 2 "32A" 1 "40A" 0 "要求なし" ;
VAL_ 1142 CCU476_16_0_DC_PWR_MAX_LIM_CHG 8 "50kW" 7 "75kW" 6 "100kW" 5 "125kW" 4 "150kW" 3 "175kW" 2 "200kW" 1 "225kW" 0 "要求なし" ;
VAL_ 1142 CCU476_13_5_SW_CAUTION_PNC 1 "押す" 0 "No signal" ;
VAL_ 1142 CCU476_13_4_SW_NEW_PNC 1 "押す" 0 "No signal" ;
VAL_ 1142 CCU476_13_3_START_CTR_PNC 1 "契約案内出力" 0 "非表示" ;
VAL_ 1142 CCU476_13_1_STS_PNC 3 "オン状態（ON）" 2 "オフ状態（OFF）" 1 "新規契約 (New)" 0 "新規契約 (New)" ;
VAL_ 1142 CCU476_13_0_DESC_PNC 1 "文言A表示" 0 "非表示" ;
VAL_ 1142 CCU476_9_0_WKD_SET_TIM_CHG 7 "日曜日" 6 "土曜日 " 5 "金曜日 " 4 "木曜日 " 3 "水曜日 " 2 "火曜日 " 1 "月曜日" 0 "不定" ;
VAL_ 1142 CCU476_8_0_LOGIN_REQ_TIM_CHG 3 "削除" 2 "変更" 1 "追加 " 0 "不定(設定要求なし)" ;
VAL_ 1142 CCU476_3_0_PNC_SW_REQ_CCU 5 "PnC_Function_Terminated(Certificate_Deleted)" 4 "Key_Unlocked" 3 "Key_Locked" 2 "ON" 1 "OFF" 0 "No_Request" ;
VAL_ 1142 CCU476_2_7_SW_TIM_CHG 1 "オン状態" 0 "オフ状態" ;
VAL_ 1141 CCU475_3_2_SW_PWR_SPL_DC 2 "OFF_Request" 1 "ON_Request(Unused)" 0 "No_Request" ;
VAL_ 1141 CCU475_3_0_SW_PWR_SPL_AC 3 "Undefined" 2 "OFF_Request" 1 "ON_Request" 0 "No_Request" ;
VAL_ 1105 CCU451_8_0_CHG_BTN_FLG_CCU 4 "Precondition_Button_Display(Resverd)" 2 "Begin_Charging_Button_Display" 1 "Stop_Charging_Button_Display" 0 "Non_Display(Initial)" ;
VAL_ 1105 CCU451_8_3_CHG_CNG_FLG_CCU 1 "Changed" 0 "No_Change(Initial)" ;
VAL_ 1105 CCU451_5_0_SW_RIGHT_NOW_PRE_CON 4 "Undefined" 2 "ON" 1 "OFF" 0 "No_Request" ;
VAL_ 1105 CCU451_4_0_CHG_STP_REQ 1 "Request" 0 "Not Request" ;
VAL_ 1105 CCU451_3_4_DCCHG_PWRUPLMT 15 "Fail" 14 "Initial" 8 "50kW" 7 "75kW" 6 "100kW" 5 "125kW" 4 "150kW" 3 "175kW" 2 "200kW" 1 "225kW" 0 "MAX" ;
VAL_ 1105 CCU451_3_0_ACCHG_CORUPLMT 15 "Fail" 14 "Initial" 6 "8A" 5 "12A" 4 "16A" 3 "24A" 2 "32A" 1 "40A" 0 "MAX " ;
VAL_ 1664 CECU680_6_4_SDK_PRG 7 "Pattern8" 6 "Pattern7" 5 "Pattern6" 4 "Pattern5" 3 "Pattern4" 2 "Pattern3" 1 "Pattern2" 0 "Pattern1" ;
VAL_ 1664 CECU680_6_0_RSLT_AUTHORITY 3 "Friend" 2 "Owner other" 1 "Owner AcKey" 0 "Indefinite" ;
VAL_ 1664 CECU680_5_6_RDK_SWAPGRL 2 "Failure" 1 "Success" 0 "No Response" ;
VAL_ 1664 CECU680_5_4_RDK_ORRL 2 "Failure" 1 "Success" 0 "No Response" ;
VAL_ 1664 CECU680_4_6_RDK_ADRL 2 "Failure" 1 "Success" 0 "No Response" ;
VAL_ 1664 CECU680_4_4_RDK_ODRL 2 "Failure" 1 "Success" 0 "No Response" ;
VAL_ 1664 CECU680_4_2_RDK_FDRL 2 "Failure" 1 "Success" 0 "No Response" ;
VAL_ 1664 CECU680_4_0_RDK_OGRL 2 "Failure" 1 "Success" 0 "No Response" ;
VAL_ 1664 CECU680_3_7_ADK_ADLA 1 "Available" 0 "Uｎavailble" ;
VAL_ 1664 CECU680_3_6_ADK_OWDA 1 "Available" 0 "Uｎavailble" ;
VAL_ 1664 CECU680_3_4_ADK_REGA 1 "Available" 0 "Uｎavailble" ;
VAL_ 1664 CECU680_3_3_ADK_STCA 1 "Available" 0 "Uｎavailble" ;
VAL_ 1664 CECU680_3_2_ADK_SWAPSTACA 1 "Available" 0 "Uｎavailble" ;
VAL_ 1664 CECU680_3_1_ADK_FWDA 1 "Available" 0 "Uｎavailble" ;
VAL_ 1664 CECU680_3_0_ADK_SWAPWDA 1 "Available" 0 "Uｎavailble" ;
VAL_ 1726 CCU6BE_10_0_CCU_BOOT_STATE 7 "Reserved" 6 "Reserved" 5 "Reserved" 4 "Reserved" 3 "CCU_NORMAL_STARTUP_STATE" 2 "IOC_AND_CLUSTER_NORMAL_STARTUP_STATE" 1 "IOC_AND_IVI_NORMAL_STARTUP_STATE" 0 "IOC_NORMAL_STARTUP_STATE" ;
VAL_ 1726 CCU6BE_9_0_DISP_DRAINAGE 5 "CANCEL_INSTRUCTION" 4 "WAITING_FOR_DRAINAGE_COMPLETION" 3 "START_DRAINAGE_COMPLETION" 2 "WAITING_FOR_DRAINAGE_COMPLETION_START" 1 "SWITCH_TO_DRAINAGE_MODE" 0 "NO_DRAINAGE_CONTROL_REQUEST" ;
VAL_ 1726 CCU6BE_8_0_DISP_POURING_WATER 13 "CANCEL_INSTRUCTION" 12 "INJECTION_COMPLETED" 11 "START_INJECTION_COMPLETION" 10 "WAITING_FOR_INJECTION_COMPLETION" 9 "START_4TH_AIR_BLEEDING" 8 "WAITING_FOR_4TH_AIR_BLEEDING" 7 "START_3RD_AIR_BLEEDING" 6 "WAITING_FOR_3RD_AIR_BLEEDING" 5 "START_2ND_AIR_BLEEDING" 4 "WAITING_FOR_2ND_AIR_BLEEDING" 3 "START_1ST_AIR_BLEEDING" 2 "WAITING_FOR_1ST_AIR_BLEEDING" 1 "SWITCH_TO_WATER_INJECTION_MODE" 0 "NO_WATER_INJECTION_REQUEST" ;
VAL_ 1726 CCU6BE_4_2_QDK_OSWAP 2 "Cancel" 1 "Reqest" 0 "No reqest" ;
VAL_ 1726 CCU6BE_4_4_QDK_FDRQ 2 "Cancel" 1 "Reqest" 0 "No reqest" ;
VAL_ 1726 CCU6BE_4_6_QDK_OWCQ 2 "Cancel" 1 "Reqest" 0 "No reqest" ;
VAL_ 1726 CCU6BE_3_0_QDK_ORRQ 2 "Cancel" 1 "Reqest" 0 "No reqest" ;
VAL_ 1726 CCU6BE_3_2_QDK_OGRQ 2 "Cancel" 1 "Reqest" 0 "No reqest" ;
VAL_ 1726 CCU6BE_3_4_QDK_ODRQ 2 "Cancel" 1 "Reqest" 0 "No reqest" ;
VAL_ 1726 CCU6BE_3_6_QDK_ADLQ 2 "Cancel" 1 "Reqest" 0 "No reqest" ;
VAL_ 1613 DKY64D_0_5_BLEMSGID 5 "Pattern5" 4 "Pattern4" 3 "Pattern3" 2 "Pattern2" 1 "Pattern1" ;
VAL_ 1612 DKY64C_5_6_DKY_RSLT 3 "Pattern4" 2 "Pattern3" 1 "Pattern2" 0 "Pattern１" ;
VAL_ 1612 DKY64C_4_0_RSRGDK 54 "Pattern15" 53 "Pattern14" 52 "Pattern13" 51 "Pattern12" 50 "Pattern11" 49 "Pattern10" 40 "Pattern9" 39 "Pattern8" 38 "Pattern7" 37 "Pattern6" 36 "Pattern5" 35 "Pattern4" 34 "Pattern3" 17 "Pattern2" 0 "Pattern1" ;
VAL_ 1612 DKY64C_0_0_DKRGNGFC 132 "Pattern11" 131 "Pattern10" 130 "Pattern9" 129 "Pattern8" 128 "Pattern7" 5 "Pattern6" 4 "Pattern5" 3 "Pattern4" 2 "Pattern3" 1 "Pattern2" 0 "Pattern1" ;
VAL_ 1608 DKY648_3_0_TMIDD 7 "Key7" 6 "Key6" 5 "Key5" 4 "Key4" 3 "Key3" 2 "Key2" 1 "Key1" 0 "Other" ;
VAL_ 1608 DKY648_1_1_WINFD 32 "UNLOCK" 16 "LOCK" 0 "OFF" ;
VAL_ 1608 DKY648_0_4_KTYPED 14 "otherwise未定義" 4 "Pattern2" 3 "Pattern1" ;
VAL_ 1575 DKY627_0_5_SPNUM 4 "Num4" 3 "Num3" 2 "Num2" 1 "Num1" 0 "No Connect" ;
